VERSION ""

NS_ :

BS_:

BU_: XXX CAMERA FRONT_RADAR ADRV APRK

BO_ 731 MLM_02_200ms: 8 XXX
 SG_ MLM_SlvColor_X : 0|8@1+ (1,0) [0|255] "" XXX
 SG_ MLM_SlvColor_Y : 8|16@1+ (1,0) [0|65535] "" XXX
 SG_ MLM_SlvBrgtnsVal : 24|8@1+ (1,0) [0|255] "" XXX
 SG_ MLM_SlvFadeInTimetVal : 32|8@1+ (1,0) [0|255] "" XXX
 SG_ MLM_SlvFadeOutTimetVal : 40|8@1+ (1,0) [0|255] "" XXX
 SG_ MLM_SlvFadeInOutOnOff : 48|8@1+ (1,0) [0|255] "" XXX

BO_ 732 ADAS_PRK_CAM_01_600ms: 8 XXX
 SG_ ADAS_PRK_CAM_Crc1Val : 0|16@1+ (1,0) [0|65535] "" XXX
 SG_ ADAS_PRK_CAM_AlvCnt1Val : 16|8@1+ (1,0) [0|255] "" XXX
 SG_ SVM_CamExtID : 24|8@1+ (1,0) [0|255] "" XXX
 SG_ SVM_CamExtTrnX : 32|13@1+ (1,0) [0|8191] "" XXX
 SG_ SVM_CamExtTrnY : 45|19@1+ (1,0) [0|524287] "" XXX
 SG_ SVM_CamExtTrnZ : 64|10@1+ (1,0) [0|1023] "" XXX
 SG_ SVM_CamExtPitch : 74|11@1+ (1,0) [0|2047] "" XXX
 SG_ SVM_CamExtYaw : 85|11@1+ (1,0) [0|2047] "" XXX
 SG_ SVM_CamExtRoll : 96|8@1+ (1,0) [0|255] "" XXX

BO_ 733 CMS_LH_01_200ms: 8 XXX
 SG_ USM_TurnDstLnDispSta : 20|2@1+ (1,0) [0|3] "" XXX
 SG_ USM_TurnDstLnDispStaRH : 22|2@1+ (1,0) [0|3] "" XXX
 SG_ USM_RhstaLvlEnaSta : 24|2@1+ (1,0) [0|3] "" XXX
 SG_ USM_RhstaLvlEnaStaRH : 26|2@1+ (1,0) [0|3] "" XXX
 SG_ USM_CMSDayBrgtnsLvlLHSta : 28|4@1+ (1,0) [0|15] "" XXX
 SG_ USM_CMSNgtBrgtnsLvlLHSta : 32|4@1+ (1,0) [0|15] "" XXX
 SG_ IMS_CMSPlayBackSta_LH : 36|4@1+ (1,0) [0|15] "" XXX
 SG_ CMSFldReq : 40|8@1+ (1,0) [0|255] "" XXX
 SG_ CMS_LHVerPosVal : 48|8@1+ (1,0) [0|255] "" XXX
 SG_ CMS_LHHorPosVal : 56|8@1+ (1,0) [0|255] "" XXX

BO_ 734 CMS_LH_02_200ms: 8 XXX
 SG_ CMS_LHSta : 16|2@1+ (1,0) [0|3] "" XXX
 SG_ CMS_Opt : 18|6@1+ (1,0) [0|63] "" XXX

BO_ 735 HU_FPM_E: 8 XXX
 SG_ CF_AVN_FpLpRedNValueSet : 0|9@1+ (1,0) [0|511] "" XXX
 SG_ CF_AVN_FpLpGreenNValueSet : 9|9@1+ (1,0) [0|511] "" XXX
 SG_ CF_AVN_FpLpBlueNValueSet : 18|9@1+ (1,0) [0|511] "" XXX
 SG_ CF_AVN_FpLpCtrlNvalueSet : 27|5@1+ (1,0) [0|31] "" XXX

BO_ 736 VCU_03_100ms: 32 XXX
 SG_ VCU_Crc3Val : 0|16@1+ (1,0) [0|65535] "" XXX
 SG_ VCU_AlvCnt3Val : 16|8@1+ (1,0) [0|255] "" XXX
 SG_ VCU_CrzDrvAlertDisp : 24|2@1+ (1,0) [0|3] "" XXX
 SG_ VCU_SpdLimSetLampSta : 26|2@1+ (1,0) [0|3] "" XXX
 SG_ VCU_CrzOnLampSta : 32|2@1+ (1,0) [0|3] "" XXX
 SG_ VCU_CrzSetLampSta : 34|2@1+ (1,0) [0|3] "" XXX
 SG_ VCU_CrzOvrrideSta : 36|2@1+ (1,0) [0|3] "" XXX
 SG_ VCU_SpdLmtActSta : 38|1@1+ (1,0) [0|1] "" XXX
 SG_ VCU_CrzSetSpdVal : 40|8@1+ (1,0) [0|255] "" XXX
 SG_ VCU_SpdLmtSetSpdVal : 48|7@1+ (1,0) [0|127] "" XXX
 SG_ MAX_SPEED : 55|1@0+ (1,0) [0|1] "" XXX
 SG_ VCU_RegenLvl_EcoModeSta : 56|2@1+ (1,0) [0|3] "" XXX
 SG_ VCU_RegenLvl_NorModeSta : 58|2@1+ (1,0) [0|3] "" XXX
 SG_ VCU_RegenLvl_SptModeSta : 60|2@1+ (1,0) [0|3] "" XXX
 SG_ VCU_SccAvailSta : 62|2@1+ (1,0) [0|3] "" XXX
 SG_ VCU_SccMaxTqVal : 64|8@1+ (1,0) [0|255] "" XXX
 SG_ VCU_EcoModSpdLmt_ActSta : 72|5@1+ (1,0) [0|31] "" XXX
 SG_ VCU_SmartModSta : 77|3@1+ (1,0) [0|7] "" XXX
 SG_ VCU_EcoModSpdLmt_SetSpdVal : 80|8@1+ (1,0) [0|255] "" XXX
 SG_ VCU_SmartRegen_UsmSta : 88|2@1+ (1,0) [0|3] "" XXX
 SG_ VCU_SmartRegen_OnSta : 90|2@1+ (1,0) [0|3] "" XXX
 SG_ VCU_SmartRegen_RdrCstActSta : 92|2@1+ (1,0) [0|3] "" XXX
 SG_ VCU_SmartRegen_WarnMsgSta : 94|2@1+ (1,0) [0|3] "" XXX
 SG_ VCU_SmartModIdx : 96|5@1+ (1,0) [0|31] "" XXX
 SG_ VCU_VehHoldSta : 101|2@1+ (1,0) [0|3] "" XXX
 SG_ VCU_SmartRegen_OnAlarmSta : 103|2@1+ (1,0) [0|3] "" XXX
 SG_ VCU_RegenLvlVal : 105|6@1+ (1,0) [0|63] "" XXX
 SG_ VCU_SmartRegen_MapCstActSta : 111|3@1+ (1,0) [0|7] "" XXX
 SG_ VCU_SmartRegen_MapEventUsmSta : 114|2@1+ (1,0) [0|3] "" XXX
 SG_ VCU_SmartRegen_IntsectUsmSta : 116|2@1+ (1,0) [0|3] "" XXX
 SG_ VCU_SmartRegen_SpdHumpUsmSta : 118|2@1+ (1,0) [0|3] "" XXX
 SG_ VCU_SmartRegen_SpdLmtUsmSta : 120|2@1+ (1,0) [0|3] "" XXX
 SG_ VCU_SmartRegen_SensUsmSta : 122|6@1+ (1,0) [0|63] "" XXX
 SG_ VCU_SmartRegen_VehHoldUsmSta : 128|2@1+ (1,0) [0|3] "" XXX
 SG_ VCU_SmartRegen_IntsectCstActSta : 130|2@1+ (1,0) [0|3] "" XXX
 SG_ VCU_SmartRegen_SpdHumpCstActSta : 132|2@1+ (1,0) [0|3] "" XXX
 SG_ VCU_SmartRegen_SpdLmtCstActSta : 134|2@1+ (1,0) [0|3] "" XXX
 SG_ VCU_iPedalUsmSta : 136|2@1+ (1,0) [0|3] "" XXX
 SG_ VCU_SmartRegen_MapCstWarnMsgSta : 138|3@1+ (1,0) [0|7] "" XXX
 SG_ VCU_SmartRegen_RdrCstWarnMsgSta : 141|3@1+ (1,0) [0|7] "" XXX
 SG_ MAX_SPEED_COPY : 144|8@1+ (1,0) [0|255] "" XXX
 SG_ VCU_SpdLmtDrvAlertDisp : 173|2@1+ (1,0) [0|3] "" XXX
 SG_ VCU_iPedalActSta : 175|2@1+ (1,0) [0|3] "" XXX
 SG_ VCU_DrvModeApply : 177|8@1+ (1,0) [0|255] "" XXX
 SG_ VCU_iPedalIndiSta : 185|7@1+ (1,0) [0|127] "" XXX
 SG_ VCU_TowWeightUsmSta : 192|4@1+ (1,0) [0|15] "" XXX
 SG_ VCU_TowMaxWeightUsmSta : 196|4@1+ (1,0) [0|15] "" XXX
 SG_ VCU_TrailerModWarnMsgSta : 200|8@1+ (1,0) [0|255] "" XXX
 SG_ VCU_VgsSftMod : 208|3@1+ (1,0) [0|7] "" XXX
 SG_ VCU_VgsVirEngSpdRpmMaxVal : 211|5@1+ (1,0) [0|31] "" XXX
 SG_ VCU_VgsGearStepType : 216|4@1+ (1,0) [0|15] "" XXX
 SG_ VCU_VgsVirEngSpdRpmRedStartVal : 220|28@1+ (1,0) [0|268435455] "" XXX
 SG_ VCU_eEPBCtrlSta : 248|2@1+ (1,0) [0|3] "" XXX
 SG_ VCU_eEPBSta : 250|2@1+ (1,0) [0|3] "" XXX
 SG_ VCU_eEPBCommSta : 252|4@1+ (1,0) [0|15] "" XXX

BO_ 741 OBC_01_100ms: 8 XXX
 SG_ OBC_Crc1Val : 0|16@1+ (1,0) [0|65535] "" XXX
 SG_ OBC_AlvCnt1Val : 16|8@1+ (1,0) [0|255] "" XXX
 SG_ OBC_SysRdySta : 24|4@1+ (1,0) [0|15] "" XXX
 SG_ OBC_ContrabSta : 28|4@1+ (1,0) [0|15] "" XXX
 SG_ OBC_SysFltSta : 32|2@1+ (1,0) [0|3] "" XXX
 SG_ OBC_ChrgFnshSta : 34|2@1+ (1,0) [0|3] "" XXX
 SG_ OBC_AcDetSta : 36|2@1+ (1,0) [0|3] "" XXX
 SG_ OBC_HvIntlkReq : 38|2@1+ (1,0) [0|3] "" XXX
 SG_ OBC_VcrmReq : 40|2@1+ (1,0) [0|3] "" XXX
 SG_ OBC_SvrLmpReq : 42|6@1+ (1,0) [0|63] "" XXX
 SG_ OBC_OpModeSta : 48|3@1+ (1,0) [0|7] "" XXX
 SG_ OBC_DiagInfoGrp : 51|5@1+ (1,0) [0|31] "" XXX
 SG_ OBC_DcMaxCurrVal : 56|8@1+ (1,0) [0|255] "" XXX
 SG_ OBC_SeqSta : 64|8@1+ (1,0) [0|255] "" XXX
 SG_ OBC_PwrLmtSta : 72|4@1+ (1,0) [0|15] "" XXX
 SG_ OBC_InfoCodVal : 76|12@1+ (1,0) [0|4095] "" XXX
 SG_ OBC_EstDcOutPwrValForVcms : 88|8@1+ (1,0) [0|255] "" XXX
 SG_ OBC_AcVoltValForVcms : 96|8@1+ (1,0) [0|255] "" XXX

BO_ 746 MCU_08_200ms: 8 XXX
 SG_ MCU_Crc8Val : 0|16@1+ (1,0) [0|65535] "" XXX
 SG_ MCU_AlvCnt8Val : 16|8@1+ (1,0) [0|255] "" XXX
 SG_ VCRM_Mg2RsvrLssjsFigRdsVal : 24|10@1+ (1,0) [0|1023] "" XXX
 SG_ VCRM_Mg2MainStateSta : 34|6@1+ (1,0) [0|63] "" XXX
 SG_ VCRM_Mg2RsvrLssjsFigDevVal : 40|16@1+ (1,0) [0|65535] "" XXX
 SG_ VCRM_Mg2OpSta : 56|8@1+ (1,0) [0|255] "" XXX
 SG_ VCRM_Mg2CurRmsVal : 64|16@1+ (1,0) [0|65535] "" XXX
 SG_ MCU_Mg2MotPower_Wh : 80|16@1+ (1,0) [0|65535] "" XXX
 SG_ MCU_Mg2GenPower_Wh : 96|32@1+ (1,0) [0|4294967295] "" XXX
 SG_ VCRM_Mg2FltCodeVal : 128|8@1+ (1,0) [0|255] "" XXX

BO_ 758 SBCM_DRV_02_200ms: 8 XXX
 SG_ SBCM_DRV_Crc2Val : 0|8@1+ (1,0) [0|255] "" XXX
 SG_ SBCM_DRV_DiagSta : 8|4@1+ (1,0) [0|15] "" XXX
 SG_ SBCM_DRV_AlvCnt2Val : 12|4@1+ (1,0) [0|15] "" XXX
 SG_ SBCM_PsvDrLkReq : 16|6@1+ (1,0) [0|63] "" XXX
 SG_ USM_DrvGhostDoorSta : 22|6@1+ (1,0) [0|63] "" XXX
 SG_ DRV_CrashMRActAlarm : 28|8@1+ (1,0) [0|255] "" XXX
 SG_ IMS_OSMirPlayBackSta_LH : 36|4@1+ (1,0) [0|15] "" XXX
 SG_ ECMMRR_PLUS : 40|8@1+ (1,0) [0|255] "" XXX
 SG_ Mirror_LHVerPosVal : 48|8@1+ (1,0) [0|255] "" XXX
 SG_ Mirror_LHHorPosVal : 56|8@1+ (1,0) [0|255] "" XXX

BO_ 759 SBCM_RL_02_200ms: 8 XXX
 SG_ RL_CrashMRActAlarm : 10|2@1+ (1,0) [0|3] "" XXX
 SG_ PwrDRBuzzerOut_RL : 12|4@1+ (1,0) [0|15] "" XXX
 SG_ PwrDRClosingRLDrSta : 16|8@1+ (1,0) [0|255] "" XXX

BO_ 760 SBCM_RR_02_200ms: 8 XXX
 SG_ SMK_Crc1Val : 0|8@1+ (1,0) [0|255] "" XXX
 SG_ Auth_Event : 8|4@1+ (1,0) [0|15] "" XXX
 SG_ RR_CrashMRActAlarm : 10|2@1+ (1,0) [0|3] "" XXX
 SG_ SMK_AlvCnt1Val : 12|4@1+ (1,0) [0|15] "" XXX
 SG_ PwrDRClosingRRDrSta : 16|8@1+ (1,0) [0|255] "" XXX
 SG_ DoorLock_PsvDrUnLkReq : 19|3@1+ (1,0) [0|7] "" XXX
 SG_ DoorLock_DrvDrPsvAcsReq : 22|2@1+ (1,0) [0|3] "" XXX
 SG_ DoorLock_AsstDrPsvAcsReq : 24|2@1+ (1,0) [0|3] "" XXX
 SG_ DoorLock_TrnkTlgtPsvAcsReq : 26|2@1+ (1,0) [0|3] "" XXX
 SG_ DoorLock_RrLftDrPsvAcsReq : 28|2@1+ (1,0) [0|3] "" XXX
 SG_ DoorLock_RrRtDrPsvAcsReq : 30|8@1+ (1,0) [0|255] "" XXX
 SG_ RSPA_DigitalKeyAuth : 38|4@1+ (1,0) [0|15] "" XXX
 SG_ SCM_SWVerMajor1 : 40|8@1+ (1,0) [0|255] "" XXX
 SG_ Auth_Method : 42|6@1+ (1,0) [0|63] "" XXX
 SG_ SCM_SWVerMinor1 : 48|8@1+ (1,0) [0|255] "" XXX
 SG_ SCM_SWVerMinor2 : 56|8@1+ (1,0) [0|255] "" XXX

BO_ 761 CMS_RH_01_200ms_CMS: 8 XXX
 SG_ Mirror_RHVerPosVal : 48|8@1+ (1,0) [0|255] "" XXX
 SG_ Mirror_RHHorPosVal : 56|8@1+ (1,0) [0|255] "" XXX

BO_ 762 BMS_02_100ms: 8 XXX
 SG_ BMS_Crc2Val : 0|16@1+ (1,0) [0|65535] "" XXX
 SG_ BMS_AlvCnt2Val : 16|8@1+ (1,0) [0|255] "" XXX
 SG_ xEV_SrvLmpReq : 24|2@1+ (1,0) [0|3] "" XXX
 SG_ xEV_MainRlyOnSta : 26|2@1+ (1,0) [0|3] "" XXX
 SG_ xEV_SysFltSta : 28|4@1+ (1,0) [0|15] "" XXX
 SG_ xEV_BattRmnEnrgVal : 32|8@1+ (1,0) [0|255] "" XXX
 SG_ xEV_InltTempVal : 40|8@1+ (1,0) [0|255] "" XXX
 SG_ xEV_MinBattCelVoltVal : 48|8@1+ (1,0) [0|255] "" XXX
 SG_ xEV_MaxBattCelVoltVal : 56|8@1+ (1,0) [0|255] "" XXX
 SG_ xEV_BattCurrVal : 64|16@1+ (1,0) [0|65535] "" XXX
 SG_ xEV_MinBattTempVal : 80|8@1+ (1,0) [0|255] "" XXX
 SG_ xEV_MaxBattTempVal : 88|16@1+ (1,0) [0|65535] "" XXX
 SG_ xEV_DiagGrpVal : 104|8@1+ (1,0) [0|255] "" XXX
 SG_ xEV_DiagMonVal : 112|8@1+ (1,0) [0|255] "" XXX
 SG_ xEV_SocDis : 120|34@1+ (1,0) [0|17179869183] "" XXX
 SG_ xEV_ClimateOffReq : 154|2@1+ (1,0) [0|3] "" XXX
 SG_ xEV_MainRlyOnRetrySta : 156|2@1+ (1,0) [0|3] "" XXX
 SG_ xEV_Bms_BlackBox_Data_req : 158|12@1+ (1,0) [0|4095] "" XXX
 SG_ xEV_BmsRomType : 170|6@1+ (1,0) [0|63] "" XXX
 SG_ xEV_PRATempSnsVal_ : 176|16@1+ (1,0) [0|65535] "" XXX
 SG_ xEV_BattRCHTimeEst : 192|16@1+ (1,0) [0|65535] "" XXX
 SG_ EV_DischrgCurrLimForV2X : 208|16@1+ (1,0) [0|65535] "" XXX
 SG_ xEV_Bms_IsolDetDeactFuncSta : 224|2@1+ (1,0) [0|3] "" XXX
 SG_ xEV_Bms_CellBalDeactFuncSta : 226|6@1+ (1,0) [0|63] "" XXX
 SG_ EV_V2XDischrgLimSocVal_SYNC : 232|8@1+ (1,0) [0|255] "" XXX

BO_ 763 SBCM_DRV_03_200ms: 8 XXX
 SG_ SBCM_DRV_Crc3Val : 0|12@1+ (1,0) [0|4095] "" XXX
 SG_ SBCM_DRV_AlvCnt3Val : 12|22@1+ (1,0) [0|4194303] "" XXX
 SG_ PwrDRBuzzerOut_DRV : 34|12@1+ (1,0) [0|4095] "" XXX
 SG_ SBCM_Longkey_DRVDrAtClsSwSta : 46|2@1+ (1,0) [0|3] "" XXX
 SG_ PwrDRClosingDRVDrSta : 48|8@1+ (1,0) [0|255] "" XXX

BO_ 769 CCU_FOD_01_200ms: 8 XXX
 SG_ CCU_FOD_Crc1Val : 0|16@1+ (1,0) [0|65535] "" XXX
 SG_ CCU_FOD_AlvCnt1Val : 16|8@1+ (1,0) [0|255] "" XXX
 SG_ CCU_FOD_VIN_Status : 24|2@1+ (1,0) [0|3] "" XXX
 SG_ CCU_FOD_VIN_Index : 26|6@1+ (1,0) [0|63] "" XXX
 SG_ CCU_FOD_VIN_32 : 32|8@1+ (1,0) [0|255] "" XXX

BO_ 773 MCU_09_1000ms: 8 XXX
 SG_ MCU_Crc9Val : 0|16@1+ (1,0) [0|65535] "" XXX
 SG_ MCU_AlvCnt9Val : 16|8@1+ (1,0) [0|255] "" XXX
 SG_ VCRM_Mg2EstMtrTqVal : 24|8@1+ (1,0) [0|255] "" XXX
 SG_ VCRM_Mg2MtrDeratingFctrVal : 32|8@1+ (1,0) [0|255] "" XXX
 SG_ VCRM_Mg2InvtTempVal : 40|8@1+ (1,0) [0|255] "" XXX
 SG_ VCRM_Mg2MtrTempVal : 48|24@1+ (1,0) [0|16777215] "" XXX
 SG_ VCRM_Mg2IgbtJnctnTempVal : 72|16@1+ (1,0) [0|65535] "" XXX
 SG_ VCRM_Mg2InvtInVoltVal : 88|8@1+ (1,0) [0|255] "" XXX
 SG_ VCRM_Mg2EwpSpdReq : 96|8@1+ (1,0) [0|255] "" XXX
 SG_ VCRM_Mg2HtsnkTempVal : 104|8@1+ (1,0) [0|255] "" XXX
 SG_ VCRM_Mg2ActlMtrRotatSpdRpmVal : 112|16@1+ (1,0) [0|65535] "" XXX
 SG_ VCRM_Mg2EwpActSpdRpmVal : 128|56@1+ (1,0) [0|7.20575940379279e+16] "" XXX
 SG_ VCRM_Mg2LampReq : 184|2@1+ (1,0) [0|3] "" XXX
 SG_ VCRM_Mg2McuReq : 186|6@1+ (1,0) [0|63] "" XXX

BO_ 778 VCMS_02_100ms: 8 XXX
 SG_ VCMS_CyclicRedundancyCheck2Value : 0|16@1+ (1,0) [0|65535] "" XXX
 SG_ VCMS_AliveCounter2Value : 16|8@1+ (1,0) [0|255] "" XXX
 SG_ VCMS_CONTRAB : 24|2@1+ (1,0) [0|3] "" XXX
 SG_ VCMS_PDStatus : 26|2@1+ (1,0) [0|3] "" XXX
 SG_ VCMS_ChgFinished : 28|2@1+ (1,0) [0|3] "" XXX
 SG_ VCMS_WRN : 30|2@1+ (1,0) [0|3] "" XXX
 SG_ VCMS_Flt : 32|2@1+ (1,0) [0|3] "" XXX
 SG_ VCMS_Rdy : 34|2@1+ (1,0) [0|3] "" XXX
 SG_ VCMS_IG3DrvStat : 36|2@1+ (1,0) [0|3] "" XXX
 SG_ VCMS_PlugConnect : 38|2@1+ (1,0) [0|3] "" XXX
 SG_ VCMS_S2SWOnStat : 40|2@1+ (1,0) [0|3] "" XXX
 SG_ VCMS_MILReq : 42|2@1+ (1,0) [0|3] "" XXX
 SG_ VCMS_VCRM_Req : 44|2@1+ (1,0) [0|3] "" XXX
 SG_ VCMS_SERVICE_LAMP_Req : 46|2@1+ (1,0) [0|3] "" XXX
 SG_ VCMS_V2LActivation : 48|2@1+ (1,0) [0|3] "" XXX
 SG_ VCMS_DCChargingStat : 50|2@1+ (1,0) [0|3] "" XXX
 SG_ VCMS_ACChargingStat : 52|4@1+ (1,0) [0|15] "" XXX
 SG_ VCMS_ChargeInit : 56|2@1+ (1,0) [0|3] "" XXX
 SG_ VCMS_ChargingCycle : 58|2@1+ (1,0) [0|3] "" XXX
 SG_ VCMS_EvseRdyStat : 60|2@1+ (1,0) [0|3] "" XXX
 SG_ VCMS_ChgStopAlarm : 62|2@1+ (1,0) [0|3] "" XXX
 SG_ VCMS_PlcCpFlt : 64|2@1+ (1,0) [0|3] "" XXX
 SG_ VCMS_McuForcedDischReq : 66|2@1+ (1,0) [0|3] "" XXX
 SG_ VCMS_GbtPDStatus : 68|2@1+ (1,0) [0|3] "" XXX
 SG_ VCMS_V2lPlugConnect : 70|1@1+ (1,0) [0|1] "" XXX
 SG_ VCMS_CPDutyFloat : 71|10@1+ (1,0) [0|1023] "" XXX
 SG_ VCMS_CPVolt : 81|7@1+ (1,0) [0|127] "" XXX
 SG_ VCMS_FltCode_Confirm : 88|5@1+ (1,0) [0|31] "" XXX
 SG_ VCMS_FltType_Confirm : 93|3@1+ (1,0) [0|7] "" XXX
 SG_ VCMS_PdVolt : 96|8@1+ (1,0) [0|255] "" XXX
 SG_ VCMS_CluDisMode : 104|8@1+ (1,0) [0|255] "" XXX
 SG_ VCMS_EvseMaxVolt : 112|16@1+ (1,0) [0|65535] "" XXX
 SG_ VCMS_EvseMaxCurr : 128|16@1+ (1,0) [0|65535] "" XXX
 SG_ VCMS_EvseOutCurr : 144|16@1+ (1,0) [0|65535] "" XXX
 SG_ VCMS_ChgInletTmpMax : 160|8@1+ (1,0) [0|255] "" XXX
 SG_ VCMS_ChgEstPwr : 168|16@1+ (1,0) [0|65535] "" XXX
 SG_ OBC_AcPwrSysTyp : 173|3@1+ (1,0) [0|7] "" XXX
 SG_ VCMS_ChgAlarm_Stat : 184|4@1+ (1,0) [0|15] "" XXX
 SG_ VCMS_ChgAlarm_Subcode : 188|4@1+ (1,0) [0|15] "" XXX
 SG_ VCMS_ChgMaxCurr : 192|16@1+ (1,0) [0|65535] "" XXX
 SG_ VCMS_AcPwrSysTyp : 208|3@1+ (1,0) [0|7] "" XXX
 SG_ VCMS_Chg_SOC_Lv : 211|3@1+ (1,0) [0|7] "" XXX
 SG_ VCMS_GbtPlugConnect : 214|2@1+ (1,0) [0|3] "" XXX
 SG_ VCMS_ChrgInletTyp : 216|8@1+ (1,0) [0|255] "" XXX
 SG_ VCMS_ChgInCurrModSta : 224|2@1+ (1,0) [0|3] "" XXX
 SG_ VCMS_V2GMode : 226|3@1+ (1,0) [0|7] "" XXX
 SG_ VCMS_V2LMode : 229|20@1+ (1,0) [0|1048575] "" XXX
 SG_ VCMS_Asw_Num : 249|7@1+ (1,0) [0|127] "" XXX

BO_ 799 SBCM_DRV_01_200ms: 8 XXX
 SG_ SBCM_DRV_Crc1Val : 0|8@1+ (1,0) [0|255] "" XXX
 SG_ DRVDoorPushAlarm : 8|2@1+ (1,0) [0|3] "" XXX
 SG_ DRV_CrashUnlockCmd : 10|1@1+ (1,0) [0|1] "" XXX
 SG_ C_ApprOpenStatus : 11|1@1+ (1,0) [0|1] "" XXX
 SG_ SBCM_DRV_AlvCnt1Val : 12|8@1+ (1,0) [0|255] "" XXX
 SG_ Warn_DrvDrSwSta_SBCM : 20|2@1+ (1,0) [0|3] "" XXX
 SG_ DoorLock_DrvDrUnLkSta_SBCM : 22|2@1+ (1,0) [0|3] "" XXX
 SG_ DRV_SEAWarn_LH : 24|2@1+ (1,0) [0|3] "" XXX
 SG_ DRV_SEAWarn_RH : 26|2@1+ (1,0) [0|3] "" XXX
 SG_ DRV_SEWWarn_LH : 28|2@1+ (1,0) [0|3] "" XXX
 SG_ DRV_SEWWarn_RH : 30|2@1+ (1,0) [0|3] "" XXX
 SG_ DRV_MRActivationAlarm : 32|2@1+ (1,0) [0|3] "" XXX
 SG_ DRV_ReleaseWarn : 34|2@1+ (1,0) [0|3] "" XXX
 SG_ Latch_TypeOption_DRV : 36|2@1+ (1,0) [0|3] "" XXX
 SG_ DRV_SWFailAlarm : 38|6@1+ (1,0) [0|63] "" XXX
 SG_ USM_PwrDRCloseByRKELockSta : 44|2@1+ (1,0) [0|3] "" XXX
 SG_ USM_PwrDRCloseByRKELockOpt : 46|2@1+ (1,0) [0|3] "" XXX
 SG_ USM_PwrDRCloseByBrakeSta : 48|2@1+ (1,0) [0|3] "" XXX
 SG_ USM_PwrDRCloseByBrakeOpt : 50|2@1+ (1,0) [0|3] "" XXX
 SG_ USM_PwrDRBuzzerSta : 52|2@1+ (1,0) [0|3] "" XXX
 SG_ USM_PwrDRBuzzerOpt : 54|2@1+ (1,0) [0|3] "" XXX
 SG_ PDS_TypeOption_DRV : 56|2@1+ (1,0) [0|3] "" XXX
 SG_ C_DrvDoorApproachOpen : 58|2@1+ (1,0) [0|3] "" XXX
 SG_ C_DrvDoorApproachClose : 60|2@1+ (1,0) [0|3] "" XXX
 SG_ DoorLock_PDSLkSwSta_DRV : 62|2@1+ (1,0) [0|3] "" XXX

BO_ 805 BMS_06_100ms: 8 XXX
 SG_ BMS_Crc6Val : 0|16@1+ (1,0) [0|65535] "" XXX
 SG_ BMS_AlvCnt6Val : 16|8@1+ (1,0) [0|255] "" XXX
 SG_ CHRG_StndChrgConnSta_120V : 24|2@1+ (1,0) [0|3] "" XXX
 SG_ CHRG_StndChrgSta : 26|2@1+ (1,0) [0|3] "" XXX
 SG_ CHRG_ChrgCycStrtSta : 28|2@1+ (1,0) [0|3] "" XXX
 SG_ CHRG_FulChrgSta : 30|2@1+ (1,0) [0|3] "" XXX
 SG_ CHRG_ChrgSta : 32|2@1+ (1,0) [0|3] "" XXX
 SG_ CHRG_SpplmntChrgSta : 34|2@1+ (1,0) [0|3] "" XXX
 SG_ CHRG_LdcInhbtReq : 36|2@1+ (1,0) [0|3] "" XXX
 SG_ CHRG_NorChgFnshSta : 38|2@1+ (1,0) [0|3] "" XXX
 SG_ CHRG_ChrgFnshSta : 40|2@1+ (1,0) [0|3] "" XXX
 SG_ CHRG_Ig3RlyOffReq : 42|2@1+ (1,0) [0|3] "" XXX
 SG_ CHRG_PShftChgSta : 44|2@1+ (1,0) [0|3] "" XXX
 SG_ CHRG_PilotFlSta : 46|2@1+ (1,0) [0|3] "" XXX
 SG_ CHRG_ObcCmdCurrVal : 48|16@1+ (1,0) [0|65535] "" XXX
 SG_ CHRG_StndChrgRmnTimeVal : 64|16@1+ (1,0) [0|65535] "" XXX
 SG_ CHRG_ChrgRmnTimeVal : 80|16@1+ (1,0) [0|65535] "" XXX
 SG_ CHRG_ObcRlyOnSta : 96|2@1+ (1,0) [0|3] "" XXX
 SG_ CHRG_NrmlOpSta : 98|2@1+ (1,0) [0|3] "" XXX
 SG_ CHRG_ChgLamp_1EA : 100|4@1+ (1,0) [0|15] "" XXX
 SG_ CHRG_ObcCmdVoltVal : 104|16@1+ (1,0) [0|65535] "" XXX
 SG_ CHRG_ObcMainVoltVal : 120|8@1+ (1,0) [0|255] "" XXX
 SG_ CHRG_StndChrgRmnTime120Val : 128|16@1+ (1,0) [0|65535] "" XXX
 SG_ CHRG_StndChrgRmnTime240Val : 144|16@1+ (1,0) [0|65535] "" XXX
 SG_ CHRG_ObcOutCurrVal : 160|8@1+ (1,0) [0|255] "" XXX
 SG_ CHRG_DomStndChrgRmnTimeVal : 168|16@1+ (1,0) [0|65535] "" XXX
 SG_ CHRG_ChrgFltSubCodVal : 184|8@1+ (1,0) [0|255] "" XXX
 SG_ CHRG_ScChgTrgtSocVal : 192|8@1+ (1,0) [0|255] "" XXX
 SG_ CHRG_EuroStndChrgRmnTimeVal : 200|16@1+ (1,0) [0|65535] "" XXX
 SG_ CHRG_RealStndChrgRmnTimeVal : 216|16@1+ (1,0) [0|65535] "" XXX
 SG_ PHEV_EstChrgRmnTimeVal : 232|16@1+ (1,0) [0|65535] "" XXX
 SG_ CHRG_ChrgLmp_3EA : 248|8@1+ (1,0) [0|255] "" XXX

BO_ 816 BMS_05_100ms: 8 XXX
 SG_ BMS_Crc5Val : 0|16@1+ (1,0) [0|65535] "" XXX
 SG_ BMS_AlvCnt5Val : 16|8@1+ (1,0) [0|255] "" XXX
 SG_ EV_SysErrSta : 24|2@1+ (1,0) [0|3] "" XXX
 SG_ EV_BattHtOpSta : 26|2@1+ (1,0) [0|3] "" XXX
 SG_ EV_EnrgTrnsfrTyp : 28|4@1+ (1,0) [0|15] "" XXX
 SG_ EV_FulSocVal : 32|8@1+ (1,0) [0|255] "" XXX
 SG_ EV_BulkSocVal : 40|8@1+ (1,0) [0|255] "" XXX
 SG_ EV_EnrgCapVal : 48|16@1+ (1,0) [0|65535] "" XXX
 SG_ EV_FulSocRmnTimeVal : 64|16@1+ (1,0) [0|65535] "" XXX
 SG_ EV_BulkSocRmnTimeVal : 80|16@1+ (1,0) [0|65535] "" XXX
 SG_ EV_MaxPwrVal : 96|16@1+ (1,0) [0|65535] "" XXX
 SG_ EV_EnrgReqVal : 112|16@1+ (1,0) [0|65535] "" XXX
 SG_ EV_WeldDetSta : 128|2@1+ (1,0) [0|3] "" XXX
 SG_ EV_Rdy2ChrgSta : 130|2@1+ (1,0) [0|3] "" XXX
 SG_ EV_CabinConSta : 132|2@1+ (1,0) [0|3] "" XXX
 SG_ EV_TempChrgFlSta : 134|2@1+ (1,0) [0|3] "" XXX
 SG_ EV_GearPosChrgFlSta : 136|2@1+ (1,0) [0|3] "" XXX
 SG_ EV_LkFltChrgFlSta : 138|2@1+ (1,0) [0|3] "" XXX
 SG_ EV_MalFuncChrgFlSta : 140|2@1+ (1,0) [0|3] "" XXX
 SG_ EV_CurrDiffChrgFlSta : 142|2@1+ (1,0) [0|3] "" XXX
 SG_ EV_VoltRngChrgFlSta : 144|2@1+ (1,0) [0|3] "" XXX
 SG_ EV_IncompChrgFlSta : 146|2@1+ (1,0) [0|3] "" XXX
 SG_ EV_NoDataChrgFlSta : 148|4@1+ (1,0) [0|15] "" XXX
 SG_ EV_MaxCurrVal : 152|16@1+ (1,0) [0|65535] "" XXX
 SG_ EV_MaxVoltVal : 168|16@1+ (1,0) [0|65535] "" XXX
 SG_ CHRG_ScChgTargetSOCSync : 184|8@1+ (1,0) [0|255] "" XXX
 SG_ CHRG_QcChgTargetSOCSync : 192|8@1+ (1,0) [0|255] "" XXX
 SG_ EV_LowOutTempStatus : 200|2@1+ (1,0) [0|3] "" XXX
 SG_ CHRG_TargetSocFullChgSta : 202|2@1+ (1,0) [0|3] "" XXX
 SG_ CHRG_QuickChgStartSta : 204|4@1+ (1,0) [0|15] "" XXX
 SG_ CHRG_BattPackVoltVal : 208|16@1+ (1,0) [0|65535] "" XXX
 SG_ CHRG_ScChgEnergy_TargetSOCVal : 224|16@1+ (1,0) [0|65535] "" XXX
 SG_ CHRG_QcChgEnergy_TargetSOCVal : 240|8@1+ (1,0) [0|255] "" XXX

BO_ 821 BMS_07_100ms: 8 XXX
 SG_ BMS_Crc7Val : 0|16@1+ (1,0) [0|65535] "" XXX
 SG_ BMS_AlvCnt7Val : 16|8@1+ (1,0) [0|255] "" XXX
 SG_ VCRM_StndChrgConnSta : 24|2@1+ (1,0) [0|3] "" XXX
 SG_ VCRM_StndChrgSta : 26|2@1+ (1,0) [0|3] "" XXX
 SG_ VCRM_MilReq : 28|2@1+ (1,0) [0|3] "" XXX
 SG_ VCRM_SrvLmpReq : 30|2@1+ (1,0) [0|3] "" XXX
 SG_ VCRM_MainRlyOnSta : 32|2@1+ (1,0) [0|3] "" XXX
 SG_ VCRM_SysFltSta : 34|2@1+ (1,0) [0|3] "" XXX
 SG_ VCRM_ChrgSta : 36|2@1+ (1,0) [0|3] "" XXX
 SG_ VCRM_ChrgFnshSta : 38|2@1+ (1,0) [0|3] "" XXX
 SG_ VCRM_SocDisplayVal : 40|8@1+ (1,0) [0|255] "" XXX
 SG_ VCRM_InltTempVal : 48|8@1+ (1,0) [0|255] "" XXX
 SG_ VCRM_MinBattCelVoltSta : 56|8@1+ (1,0) [0|255] "" XXX
 SG_ VCRM_MaxBattCelVoltSta : 64|8@1+ (1,0) [0|255] "" XXX
 SG_ VCRM_BattCurrVal : 72|16@1+ (1,0) [0|65535] "" XXX
 SG_ VCRM_MinBattTempVal : 88|8@1+ (1,0) [0|255] "" XXX
 SG_ VCRM_MaxBattTempVal : 96|8@1+ (1,0) [0|255] "" XXX
 SG_ VCRM_ServceMliLampReq : 104|2@1+ (1,0) [0|3] "" XXX
 SG_ VCRM_SubFanSpdStpSta : 106|6@1+ (1,0) [0|63] "" XXX
 SG_ VCRM_DiagGrpVal : 112|8@1+ (1,0) [0|255] "" XXX
 SG_ VCRM_IsolResistVal : 120|4@1+ (1,0) [0|15] "" XXX
 SG_ VCRM_ChrgLmp_1EA : 124|4@1+ (1,0) [0|15] "" XXX
 SG_ VCRM_ObcCmdCurrVal : 128|8@1+ (1,0) [0|255] "" XXX
 SG_ VCRM_StndChrgRmnTimeVal : 136|16@1+ (1,0) [0|65535] "" XXX
 SG_ VCRM_SwVerVal : 152|16@1+ (1,0) [0|65535] "" XXX
 SG_ VCRM_BattPckVoltVal : 168|16@1+ (1,0) [0|65535] "" XXX
 SG_ VCRM_SubInltTempVal : 184|8@1+ (1,0) [0|255] "" XXX
 SG_ VCRM_BattChrgLimVal : 192|16@1+ (1,0) [0|65535] "" XXX
 SG_ VCRM_BattDischrgLimVal : 208|16@1+ (1,0) [0|65535] "" XXX
 SG_ VCRM_ChrgLmp_3EA : 224|8@1+ (1,0) [0|255] "" XXX
 SG_ VCRM_SocVal_ : 232|8@1+ (1,0) [0|255] "" XXX
 SG_ VCRM_BatMonitorFaultcode : 240|8@1+ (1,0) [0|255] "" XXX

BO_ 827 TP_HU_IAU: 8 XXX
 SG_ TP_HU_IAU_Byte0 : 0|8@1+ (1,0) [0|255] "" XXX
 SG_ TP_HU_IAU_Byte1 : 8|8@1+ (1,0) [0|255] "" XXX
 SG_ TP_HU_IAU_Byte2 : 16|8@1+ (1,0) [0|255] "" XXX
 SG_ TP_HU_IAU_Byte3 : 24|8@1+ (1,0) [0|255] "" XXX
 SG_ TP_HU_IAU_Byte4 : 32|8@1+ (1,0) [0|255] "" XXX
 SG_ TP_HU_IAU_Byte5 : 40|8@1+ (1,0) [0|255] "" XXX
 SG_ TP_HU_IAU_Byte6 : 48|8@1+ (1,0) [0|255] "" XXX
 SG_ TP_HU_IAU_Byte7 : 56|8@1+ (1,0) [0|255] "" XXX

BO_ 828 TP_IAU_HU: 8 XXX
 SG_ TP_IAU_HU_Byte0 : 0|8@1+ (1,0) [0|255] "" XXX
 SG_ TP_IAU_HU_Byte1 : 8|8@1+ (1,0) [0|255] "" XXX
 SG_ TP_IAU_HU_Byte2 : 16|8@1+ (1,0) [0|255] "" XXX
 SG_ TP_IAU_HU_Byte3 : 24|8@1+ (1,0) [0|255] "" XXX
 SG_ TP_IAU_HU_Byte4 : 32|8@1+ (1,0) [0|255] "" XXX
 SG_ TP_IAU_HU_Byte5 : 40|8@1+ (1,0) [0|255] "" XXX
 SG_ TP_IAU_HU_Byte6 : 48|8@1+ (1,0) [0|255] "" XXX
 SG_ TP_IAU_HU_Byte7 : 56|8@1+ (1,0) [0|255] "" XXX

BO_ 836 WCCU_03_200ms: 8 XXX
 SG_ WCCU_GA_SSID_5 : 64|32@1+ (1,0) [0|4294967295] "" XXX
 SG_ WCCU_GA_SSID_6 : 96|32@1+ (1,0) [0|4294967295] "" XXX
 SG_ WCCU_GA_SSID_7 : 128|32@1+ (1,0) [0|4294967295] "" XXX
 SG_ WCCU_GA_SSID_8 : 160|32@1+ (1,0) [0|4294967295] "" XXX
 SG_ WCCU_GA_SSID_9 : 192|32@1+ (1,0) [0|4294967295] "" XXX
 SG_ WCCU_GA_SSID_10 : 224|8@1+ (1,0) [0|255] "" XXX

BO_ 837 ADAS_DRV_01_200ms: 8 XXX
 SG_ ADAS_DRV_Crc1Val : 0|16@1+ (1,0) [0|65535] "" XXX
 SG_ ADAS_DRV_AlvCnt1Val : 16|8@1+ (1,0) [0|255] "" XXX
 SG_ ADAS_DRV_FCAEquipSta : 24|2@1+ (1,0) [0|3] "" XXX
 SG_ ADAS_DRV_SCCEquipSta : 26|2@1+ (1,0) [0|3] "" XXX
 SG_ ADAS_DRV_MDPSCtrlSta : 28|4@1+ (1,0) [0|15] "" XXX
 SG_ ADAS_DRV_CodingSta : 32|2@1+ (1,0) [0|3] "" XXX
 SG_ ADAS_DRV_ACANMonSta : 34|6@1+ (1,0) [0|63] "" XXX

BO_ 842 DATC_16_1000ms: 8 XXX
 SG_ DATC_Crc16Val : 0|16@1+ (1,0) [0|65535] "" XXX
 SG_ DATC_AlvCnt16Val : 16|8@1+ (1,0) [0|255] "" XXX
 SG_ DATC_SwVer1 : 24|7@1+ (1,0) [0|127] "" XXX
 SG_ DATC_SwVer2 : 31|7@1+ (1,0) [0|127] "" XXX
 SG_ DATC_SwVer3 : 38|10@1+ (1,0) [0|1023] "" XXX
 SG_ DATC_Typ2 : 48|8@1+ (1,0) [0|255] "" XXX

BO_ 853 CCM_03_200ms: 8 XXX
 SG_ CCM_Crc3Val : 0|16@1+ (1,0) [0|65535] "" XXX
 SG_ CCM_AlvCnt3Val : 16|8@1+ (1,0) [0|255] "" XXX
 SG_ CCM_Evse_ID1 : 24|40@1+ (1,0) [0|1099511627775] "" XXX
 SG_ CCM_Evse_ID2 : 64|40@1+ (1,0) [0|1099511627775] "" XXX
 SG_ CCM_Cert_PCID1 : 104|24@1+ (1,0) [0|16777215] "" XXX
 SG_ CCM_Cert_PCID2 : 128|64@1+ (1,0) [0|1.84467440737096e+19] "" XXX
 SG_ CCM_Cert_PCID3 : 192|8@1+ (1,0) [0|255] "" XXX

BO_ 858 SBCM_AST_02_200ms: 8 XXX
 SG_ SBCM_AST_Crc3Val : 0|8@1+ (1,0) [0|255] "" XXX
 SG_ SBCM_AST_DiagSta : 8|4@1+ (1,0) [0|15] "" XXX
 SG_ AST_CrashUnlockCmd : 10|2@1+ (1,0) [0|3] "" XXX
 SG_ SBCM_AST_AlvCnt3Val : 12|20@1+ (1,0) [0|1048575] "" XXX
 SG_ DoorLock_CtrlDrLkSwSta_SBCM : 16|2@1+ (1,0) [0|3] "" XXX
 SG_ DoorLock_CtrlDrUnLkSwSta_SBCM : 18|2@1+ (1,0) [0|3] "" XXX
 SG_ Warn_AsstDrSwSta_SBCM : 20|2@1+ (1,0) [0|3] "" XXX
 SG_ DoorLock_AsstDrUnLkSta_SBCM : 22|2@1+ (1,0) [0|3] "" XXX
 SG_ AST_SEAWarn_RH : 24|2@1+ (1,0) [0|3] "" XXX
 SG_ AST_SEAWarn_LH : 26|2@1+ (1,0) [0|3] "" XXX
 SG_ AST_SEWWarn_LH : 28|2@1+ (1,0) [0|3] "" XXX
 SG_ AST_SEWWarn_RH : 30|2@1+ (1,0) [0|3] "" XXX
 SG_ AST_MRActivationAlarm : 32|2@1+ (1,0) [0|3] "" XXX
 SG_ PwrDRBuzzerOut_AST : 34|2@1+ (1,0) [0|3] "" XXX
 SG_ USM_AstGhostDoorSta : 36|2@1+ (1,0) [0|3] "" XXX
 SG_ AST_SWFailAlarm : 38|2@1+ (1,0) [0|3] "" XXX
 SG_ PwrDRClosingASTDrSta : 40|6@1+ (1,0) [0|63] "" XXX
 SG_ PDS_TypeOption_AST : 42|6@1+ (1,0) [0|63] "" XXX
 SG_ SBCM_Longkey_ASTDrAtClsSwSta : 46|2@1+ (1,0) [0|3] "" XXX

BO_ 862 SBCM_RL_01_200ms: 8 XXX
 SG_ SBCM_RL_Crc1Val : 0|8@1+ (1,0) [0|255] "" XXX
 SG_ RLDoorPushAlarm : 8|2@1+ (1,0) [0|3] "" XXX
 SG_ RL_CrashUnlockCmd : 10|2@1+ (1,0) [0|3] "" XXX
 SG_ SBCM_RL_AlvCnt1Val : 12|4@1+ (1,0) [0|15] "" XXX
 SG_ Warn_RrLftDrSwSta_SBCM : 16|2@1+ (1,0) [0|3] "" XXX
 SG_ DoorLock_RrLftDrUnLkSta_SBCM : 18|2@1+ (1,0) [0|3] "" XXX
 SG_ RL_SEAActivated : 20|2@1+ (1,0) [0|3] "" XXX
 SG_ RL_SEAWarn : 22|2@1+ (1,0) [0|3] "" XXX
 SG_ RL_SEWWarn : 24|2@1+ (1,0) [0|3] "" XXX
 SG_ RL_ReleaseWarn : 26|2@1+ (1,0) [0|3] "" XXX
 SG_ RL_SWFailAlarm : 28|2@1+ (1,0) [0|3] "" XXX
 SG_ RL_ChildLock_ActnFlSta : 30|2@1+ (1,0) [0|3] "" XXX
 SG_ RL_MRActivationAlarm : 32|2@1+ (1,0) [0|3] "" XXX
 SG_ RL_ChildLock_Status : 34|2@1+ (1,0) [0|3] "" XXX
 SG_ USM_RLGhostDoorSta : 36|4@1+ (1,0) [0|15] "" XXX
 SG_ DoorLock_PDSLkSwSta_RL : 40|2@1+ (1,0) [0|3] "" XXX
 SG_ PDS_TypeOption_RL : 42|6@1+ (1,0) [0|63] "" XXX

BO_ 866 CAM_0x362: 32 CAMERA
 SG_ CHECKSUM : 0|16@1+ (1,0) [0|65535] "" XXX
 SG_ COUNTER : 16|8@1+ (1,0) [0|255] "" XXX
 SG_ BYTE3 : 24|8@1+ (1,0) [0|255] "" XXX
 SG_ BYTE4 : 32|8@1+ (1,0) [0|255] "" XXX
 SG_ BYTE5 : 40|8@1+ (1,0) [0|255] "" XXX
 SG_ BYTE6 : 48|8@1+ (1,0) [0|255] "" XXX
 SG_ LEFT_LANE_LINE : 56|2@1+ (1,0) [0|3] "" XXX
 SG_ SET_ME_0 : 58|2@1+ (1,0) [0|3] "" XXX
 SG_ RIGHT_LANE_LINE : 60|2@1+ (1,0) [0|3] "" XXX
 SG_ SET_ME_0_2 : 62|2@1+ (1,0) [0|3] "" XXX
 SG_ BYTE8 : 64|8@1+ (1,0) [0|255] "" XXX
 SG_ BYTE9 : 72|8@1+ (1,0) [0|255] "" XXX
 SG_ BYTE10 : 80|8@1+ (1,0) [0|255] "" XXX
 SG_ BYTE11 : 88|8@1+ (1,0) [0|255] "" XXX
 SG_ BYTE12 : 96|8@1+ (1,0) [0|255] "" XXX
 SG_ BYTE13 : 104|8@1+ (1,0) [0|255] "" XXX
 SG_ BYTE14 : 112|8@1+ (1,0) [0|255] "" XXX
 SG_ BYTE15 : 120|8@1+ (1,0) [0|255] "" XXX
 SG_ BYTE16 : 128|8@1+ (1,0) [0|255] "" XXX
 SG_ BYTE17 : 136|8@1+ (1,0) [0|255] "" XXX
 SG_ BYTE18 : 144|8@1+ (1,0) [0|255] "" XXX
 SG_ BYTE19 : 152|8@1+ (1,0) [0|255] "" XXX
 SG_ BYTE20 : 160|8@1+ (1,0) [0|255] "" XXX
 SG_ BYTE21 : 168|8@1+ (1,0) [0|255] "" XXX
 SG_ BYTE22 : 176|8@1+ (1,0) [0|255] "" XXX
 SG_ BYTE23 : 184|8@1+ (1,0) [0|255] "" XXX
 SG_ BYTE24 : 192|8@1+ (1,0) [0|255] "" XXX
 SG_ BYTE25 : 200|8@1+ (1,0) [0|255] "" XXX
 SG_ BYTE26 : 208|8@1+ (1,0) [0|255] "" XXX
 SG_ BYTE27 : 216|8@1+ (1,0) [0|255] "" XXX
 SG_ BYTE28 : 224|8@1+ (1,0) [0|255] "" XXX
 SG_ BYTE29 : 232|8@1+ (1,0) [0|255] "" XXX
 SG_ BYTE30 : 240|8@1+ (1,0) [0|255] "" XXX
 SG_ BYTE31 : 248|8@1+ (1,0) [0|255] "" XXX

BO_ 874 BLINDSPOTS_FRONT_CORNER_2: 16 XXX
 SG_ CHECKSUM : 0|16@1+ (1,0) [0|65535] "" XXX
 SG_ COUNTER : 16|8@1+ (1,0) [0|255] "" XXX

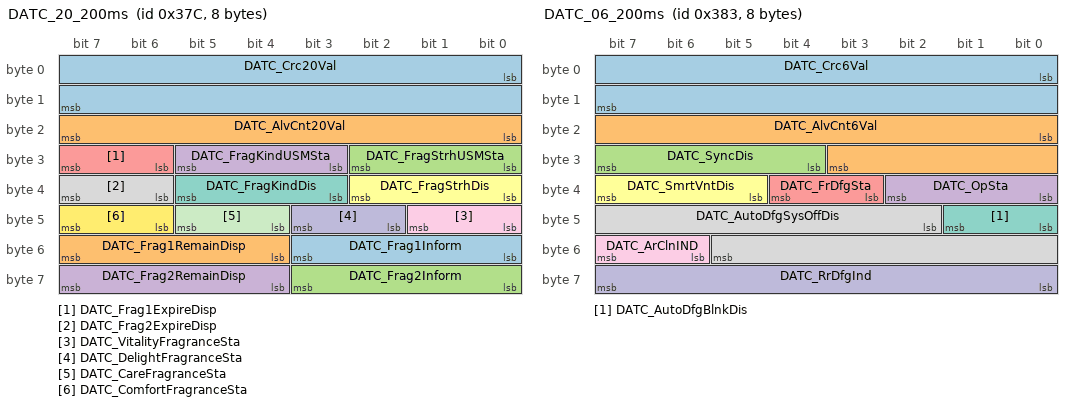
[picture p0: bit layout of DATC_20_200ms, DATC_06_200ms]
BO_ 892 DATC_20_200ms: 8 XXX
 SG_ DATC_Crc20Val : 0|16@1+ (1,0) [0|65535] "" XXX
 SG_ DATC_AlvCnt20Val : 16|8@1+ (1,0) [0|255] "" XXX
 SG_ DATC_FragStrhUSMSta : 24|3@1+ (1,0) [0|7] "" XXX
 SG_ DATC_FragKindUSMSta : 27|3@1+ (1,0) [0|7] "" XXX
 SG_ DATC_Frag1ExpireDisp : 30|2@1+ (1,0) [0|3] "" XXX
 SG_ DATC_FragStrhDis : 32|3@1+ (1,0) [0|7] "" XXX
 SG_ DATC_FragKindDis : 35|3@1+ (1,0) [0|7] "" XXX
 SG_ DATC_Frag2ExpireDisp : 38|2@1+ (1,0) [0|3] "" XXX
 SG_ DATC_VitalityFragranceSta : 40|2@1+ (1,0) [0|3] "" XXX
 SG_ DATC_DelightFragranceSta : 42|2@1+ (1,0) [0|3] "" XXX
 SG_ DATC_CareFragranceSta : 44|2@1+ (1,0) [0|3] "" XXX
 SG_ DATC_ComfortFragranceSta : 46|2@1+ (1,0) [0|3] "" XXX
 SG_ DATC_Frag1Inform : 48|4@1+ (1,0) [0|15] "" XXX
 SG_ DATC_Frag1RemainDisp : 52|4@1+ (1,0) [0|15] "" XXX
 SG_ DATC_Frag2Inform : 56|4@1+ (1,0) [0|15] "" XXX
 SG_ DATC_Frag2RemainDisp : 60|4@1+ (1,0) [0|15] "" XXX

BO_ 895 GATEWAY_STS_100ms: 8 XXX
 SG_ GATEWAY_HS_D_STS : 22|2@1+ (1,0) [0|3] "" XXX

BO_ 896 DATC_03_200ms: 8 XXX
 SG_ DATC_Crc3Val : 0|16@1+ (1,0) [0|65535] "" XXX
 SG_ DATC_AlvCnt3Val : 16|8@1+ (1,0) [0|255] "" XXX
 SG_ DATC_DrvTempCDis : 24|8@1+ (1,0) [0|255] "" XXX
 SG_ DATC_DrvTempFDis : 32|8@1+ (1,0) [0|255] "" XXX
 SG_ DATC_PassTempCDis : 40|8@1+ (1,0) [0|255] "" XXX
 SG_ DATC_PassTempFDis : 48|8@1+ (1,0) [0|255] "" XXX
 SG_ DATC_TempDispSta : 56|8@1+ (1,0) [0|255] "" XXX

BO_ 897 DATC_04_200ms: 8 XXX
 SG_ DATC_Crc4Val : 0|16@1+ (1,0) [0|65535] "" XXX
 SG_ DATC_AlvCnt4Val : 16|8@1+ (1,0) [0|255] "" XXX
 SG_ DATC_RrDrvTempCDis : 24|8@1+ (1,0) [0|255] "" XXX
 SG_ DATC_RrDrvTempFDis : 32|8@1+ (1,0) [0|255] "" XXX

BO_ 898 DATC_05_200ms: 8 XXX
 SG_ DATC_Crc5Val : 0|16@1+ (1,0) [0|65535] "" XXX
 SG_ DATC_AlvCnt5Val : 16|8@1+ (1,0) [0|255] "" XXX
 SG_ DATC_FrDrvModDis : 24|4@1+ (1,0) [0|15] "" XXX
 SG_ DATC_FrPassModDis : 28|4@1+ (1,0) [0|15] "" XXX
 SG_ DATC_ClmtTxtPopupOSD : 32|8@1+ (1,0) [0|255] "" XXX
 SG_ DATC_TempDispUnitSta : 40|2@1+ (1,0) [0|3] "" XXX
 SG_ DATC_DrvAutoDis : 42|4@1+ (1,0) [0|15] "" XXX
 SG_ DATC_FrClmtScrnDis : 46|2@1+ (1,0) [0|3] "" XXX
 SG_ DATC_AcDis : 48|2@1+ (1,0) [0|3] "" XXX
 SG_ DATC_IntakeSta : 50|6@1+ (1,0) [0|63] "" XXX

BO_ 899 DATC_06_200ms: 8 XXX
 SG_ DATC_Crc6Val : 0|16@1+ (1,0) [0|65535] "" XXX
 SG_ DATC_AlvCnt6Val : 16|12@1+ (1,0) [0|4095] "" XXX
 SG_ DATC_SyncDis : 28|4@1+ (1,0) [0|15] "" XXX
 SG_ DATC_OpSta : 32|3@1+ (1,0) [0|7] "" XXX
 SG_ DATC_FrDfgSta : 35|2@1+ (1,0) [0|3] "" XXX
 SG_ DATC_SmrtVntDis : 37|3@1+ (1,0) [0|7] "" XXX
 SG_ DATC_AutoDfgBlnkDis : 40|2@1+ (1,0) [0|3] "" XXX
 SG_ DATC_AutoDfgSysOffDis : 42|12@1+ (1,0) [0|4095] "" XXX
 SG_ DATC_ArClnIND : 54|2@1+ (1,0) [0|3] "" XXX
 SG_ DATC_RrDfgInd : 56|8@1+ (1,0) [0|255] "" XXX

BO_ 900 DATC_07_200ms: 8 XXX
 SG_ DATC_Crc7Val : 0|16@1+ (1,0) [0|65535] "" XXX
 SG_ DATC_AlvCnt7Val : 16|8@1+ (1,0) [0|255] "" XXX
 SG_ DATC_FrDrvBlwDis : 24|4@1+ (1,0) [0|15] "" XXX
 SG_ DATC_FrPsBlwDis : 28|4@1+ (1,0) [0|15] "" XXX
 SG_ DATC_HeatDis : 32|4@1+ (1,0) [0|15] "" XXX
 SG_ DATC_DrvOnlyDis : 36|20@1+ (1,0) [0|1048575] "" XXX
 SG_ DATC_AUTOStep : 56|4@1+ (1,0) [0|15] "" XXX
 SG_ DATC_IntakeDis : 60|4@1+ (1,0) [0|15] "" XXX

BO_ 902 PSM_02_200ms: 8 XXX
 SG_ PSM_DrvStSldFwdDis : 0|2@1+ (1,0) [0|3] "" XXX
 SG_ PSM_DrvStSldBckwdDis : 2|2@1+ (1,0) [0|3] "" XXX
 SG_ PSM_DrvStReclneFwdDis : 4|2@1+ (1,0) [0|3] "" XXX
 SG_ PSM_DrvStReclneBckwdDis : 6|2@1+ (1,0) [0|3] "" XXX
 SG_ PSM_IMSOptTyp : 8|16@1+ (1,0) [0|65535] "" XXX
 SG_ PSM_DrvStTiltDnDis : 10|2@1+ (1,0) [0|3] "" XXX
 SG_ PSM_DrvStHghtUpDis : 12|2@1+ (1,0) [0|3] "" XXX
 SG_ PSM_DrvStHghtDnDis : 14|2@1+ (1,0) [0|3] "" XXX
 SG_ PSM_DrvStCushExtBckwdDis : 16|2@1+ (1,0) [0|3] "" XXX
 SG_ PSM_DrvStCushExtFwdDis : 18|2@1+ (1,0) [0|3] "" XXX
 SG_ PSM_DrvStHdRstUpDis : 20|2@1+ (1,0) [0|3] "" XXX
 SG_ PSM_DrvStHdRstDnDis : 22|2@1+ (1,0) [0|3] "" XXX
 SG_ SmrtIMS_StatureRspVal : 24|4@1+ (1,0) [0|15] "" XXX
 SG_ PSM_DrvStHdRstBckwdDis : 26|6@1+ (1,0) [0|63] "" XXX
 SG_ SmrtIMS_SeatedHghtRspVal : 28|4@1+ (1,0) [0|15] "" XXX
 SG_ SmrtIMS_WghtRspVal : 32|4@1+ (1,0) [0|15] "" XXX
 SG_ PSM_DrvStLmbrLoDis : 34|2@1+ (1,0) [0|3] "" XXX
 SG_ SmartIMS_DisReq : 36|4@1+ (1,0) [0|15] "" XXX
 SG_ PSM_DrvStLmbrUpDis : 38|2@1+ (1,0) [0|3] "" XXX
 SG_ SmrtIMS_ExitSta : 40|3@1+ (1,0) [0|7] "" XXX
 SG_ PSM_DrvStBlstrInfDis : 42|6@1+ (1,0) [0|63] "" XXX
 SG_ PSM_DrvStRlxTiltUpDis : 43|2@1+ (1,0) [0|3] "" XXX
 SG_ PSM_DrvStRlxTiltDnDis : 45|2@1+ (1,0) [0|3] "" XXX
 SG_ PSM_DrvStLegUpDis : 47|2@1+ (1,0) [0|3] "" XXX
 SG_ PSM_DrvStLegDnDis : 49|7@1+ (1,0) [0|127] "" XXX

BO_ 903 APSU_03_200ms_APSU: 8 XXX
 SG_ PSM_LmbrSigSrcTyp : 44|4@1+ (1,0) [0|15] "" XXX

BO_ 904 PSM_04_200ms: 8 XXX
 SG_ PSM_DrvReclinePosition : 0|8@1+ (1,0) [0|255] "" XXX
 SG_ PSM_EsyAcsGetOnSta : 8|2@1+ (1,0) [0|3] "" XXX
 SG_ PSM_EsyAcsGetOffSta : 10|2@1+ (1,0) [0|3] "" XXX
 SG_ PSM_EsyAcsStpSta : 12|4@1+ (1,0) [0|15] "" XXX
 SG_ RRPSS_L_StSldFwdMvBtn : 16|0@1+ (1,0) [0|0] "" XXX
 SG_ RRPSS_L_StSldBwdMvBtn : 18|0@1+ (1,0) [0|0] "" XXX
 SG_ RRPSS_L_StRclFwdMvBtn : 20|0@1+ (1,0) [0|0] "" XXX
 SG_ RRPSS_L_StRclBwdMvBtn : 22|0@1+ (1,0) [0|0] "" XXX
 SG_ PSM_SWVerMinor1 : 24|8@1+ (1,0) [0|255] "" XXX
 SG_ RRPSS_L_StTltUpMvBtn : 28|0@1+ (1,0) [0|0] "" XXX
 SG_ RRPSS_L_StTltDnMvBtn : 30|0@1+ (1,0) [0|0] "" XXX
 SG_ RRPSS_L_StHRestUpMvBtn : 32|0@1+ (1,0) [0|0] "" XXX
 SG_ RRPSS_L_StHRestDnMvBtn : 34|0@1+ (1,0) [0|0] "" XXX
 SG_ RRPSS_L_StHRestFwdMvBtn : 36|0@1+ (1,0) [0|0] "" XXX
 SG_ RRPSS_L_StHRestBwdMvBtn : 38|0@1+ (1,0) [0|0] "" XXX
 SG_ RRPSS_L_StLegRestUpBtn : 40|0@1+ (1,0) [0|0] "" XXX
 SG_ RRPSS_L_StLegRestDnBtn : 42|0@1+ (1,0) [0|0] "" XXX
 SG_ PSM_DrvHeightPosition : 48|8@1+ (1,0) [0|255] "" XXX
 SG_ PSM_DrvSlidePosition : 56|8@1+ (1,0) [0|255] "" XXX

BO_ 905 SBCM_RR_01_200ms: 8 XXX
 SG_ SBCM_RR_Crc1Val : 0|8@1+ (1,0) [0|255] "" XXX
 SG_ RRDoorPushAlarm : 8|2@1+ (1,0) [0|3] "" XXX
 SG_ RR_CrashUnlockCmd : 10|2@1+ (1,0) [0|3] "" XXX
 SG_ SBCM_RR_AlvCnt1Val : 12|4@1+ (1,0) [0|15] "" XXX
 SG_ Warn_RrRtDrSwSta_SBCM : 16|2@1+ (1,0) [0|3] "" XXX
 SG_ DoorLock_RrRtDrUnLkSta_SBCM : 18|2@1+ (1,0) [0|3] "" XXX
 SG_ RR_SEAActivated : 20|2@1+ (1,0) [0|3] "" XXX
 SG_ RR_SEAWarn : 22|2@1+ (1,0) [0|3] "" XXX
 SG_ RR_SEWWarn : 24|2@1+ (1,0) [0|3] "" XXX
 SG_ RR_ReleaseWarn : 26|2@1+ (1,0) [0|3] "" XXX
 SG_ RR_SWFailAlarm : 28|2@1+ (1,0) [0|3] "" XXX
 SG_ RR_ChildLock_ActnFlSta : 30|2@1+ (1,0) [0|3] "" XXX
 SG_ RR_MRActivationAlarm : 32|2@1+ (1,0) [0|3] "" XXX
 SG_ RR_ChildLock_Status : 34|2@1+ (1,0) [0|3] "" XXX
 SG_ USM_RRGhostDoorSta : 36|4@1+ (1,0) [0|15] "" XXX
 SG_ DoorLock_PDSLkSwSta_RR : 40|2@1+ (1,0) [0|3] "" XXX
 SG_ PDS_TypeOption_RR : 42|6@1+ (1,0) [0|63] "" XXX

BO_ 907 FPM_11_200ms: 8 XXX
 SG_ FPM_Crc11Val : 0|12@1+ (1,0) [0|4095] "" XXX
 SG_ FPM_AlvCnt11Val : 12|20@1+ (1,0) [0|1048575] "" XXX
 SG_ FPM2AVN_H2PV : 32|16@1+ (1,0) [0|65535] "" XXX
 SG_ FPM2IAU_H2PV : 48|8@1+ (1,0) [0|255] "" XXX

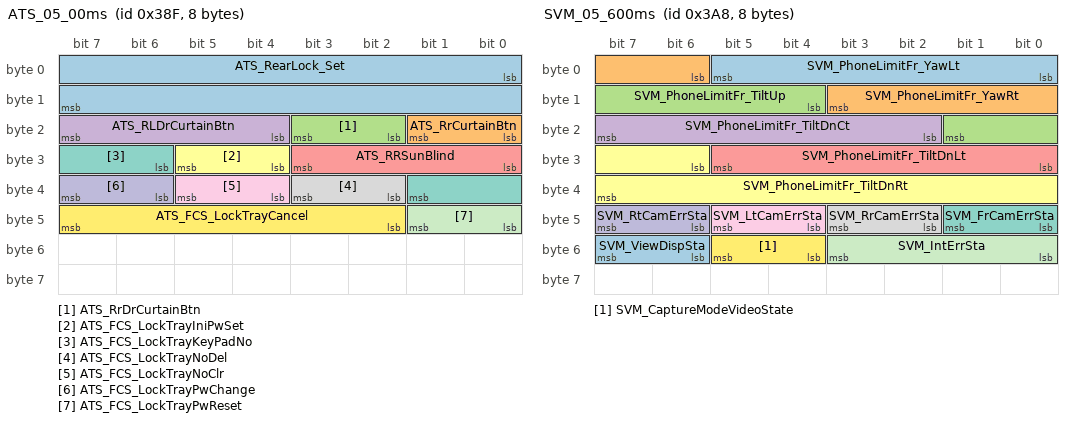
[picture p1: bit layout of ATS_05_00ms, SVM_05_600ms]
BO_ 911 ATS_05_00ms: 8 XXX
 SG_ ATS_RearLock_Set : 0|16@1+ (1,0) [0|65535] "" XXX
 SG_ ATS_RrCurtainBtn : 16|2@1+ (1,0) [0|3] "" XXX
 SG_ ATS_RrDrCurtainBtn : 18|2@1+ (1,0) [0|3] "" XXX
 SG_ ATS_RLDrCurtainBtn : 20|4@1+ (1,0) [0|15] "" XXX
 SG_ ATS_RRSunBlind : 24|4@1+ (1,0) [0|15] "" XXX
 SG_ ATS_FCS_LockTrayIniPwSet : 28|2@1+ (1,0) [0|3] "" XXX
 SG_ ATS_FCS_LockTrayKeyPadNo : 30|4@1+ (1,0) [0|15] "" XXX
 SG_ ATS_FCS_LockTrayNoDel : 34|2@1+ (1,0) [0|3] "" XXX
 SG_ ATS_FCS_LockTrayNoClr : 36|2@1+ (1,0) [0|3] "" XXX
 SG_ ATS_FCS_LockTrayPwChange : 38|2@1+ (1,0) [0|3] "" XXX
 SG_ ATS_FCS_LockTrayPwReset : 40|2@1+ (1,0) [0|3] "" XXX
 SG_ ATS_FCS_LockTrayCancel : 42|6@1+ (1,0) [0|63] "" XXX

BO_ 912 HU_GW_PE_01_HU: 8 XXX
 SG_ ThemeType : 12|4@1+ (1,0) [0|15] "" XXX
 SG_ CAM_Request : 33|7@1+ (1,0) [0|127] "" XXX

BO_ 916 BCM_19_200ms: 8 XXX
 SG_ BCM_Crc19Val : 0|8@1+ (1,0) [0|255] "" XXX
 SG_ USM_1stRrStRmndSta : 8|4@1+ (1,0) [0|15] "" XXX
 SG_ BCM_AlvCnt19Val : 12|7@1+ (1,0) [0|127] "" XXX
 SG_ USM_IBU_AutoDrUnLkReq : 19|5@1+ (1,0) [0|31] "" XXX
 SG_ USM_IBU_TwoTrnUnLkCurrentSta : 24|5@1+ (1,0) [0|31] "" XXX
 SG_ USM_IBU_RemoteWDWCurrentSta : 29|11@1+ (1,0) [0|2047] "" XXX
 SG_ USM_IBU_AutoDrLkReq2 : 40|8@1+ (1,0) [0|255] "" XXX

BO_ 917 MCU_04_200ms: 8 XXX
 SG_ MCU_Crc4Val : 0|16@1+ (1,0) [0|65535] "" XXX
 SG_ MCU_AlvCnt4Val : 16|8@1+ (1,0) [0|255] "" XXX
 SG_ VCRM_Mg1RsvrLssjsFigRdsVal : 24|10@1+ (1,0) [0|1023] "" XXX
 SG_ VCRM_Mg1MainStateSta : 34|6@1+ (1,0) [0|63] "" XXX
 SG_ VCRM_Mg1RsvrLssjsFigDevVal : 40|16@1+ (1,0) [0|65535] "" XXX
 SG_ VCRM_Mg1OpSta : 56|8@1+ (1,0) [0|255] "" XXX
 SG_ VCRM_Mg1CurRmsVal : 64|16@1+ (1,0) [0|65535] "" XXX
 SG_ MCU_Mg1MotPower_Wh : 80|16@1+ (1,0) [0|65535] "" XXX
 SG_ MCU_Mg1GenPower_Wh : 96|32@1+ (1,0) [0|4294967295] "" XXX
 SG_ VCRM_Mg1FltCodeVal : 128|8@1+ (1,0) [0|255] "" XXX

BO_ 923 OBC_01_100ms_1_OBC: 8 XXX
 SG_ ECO_SysRdySta : 42|6@1+ (1,0) [0|63] "" XXX
 SG_ OBC_AcPwrDis : 88|8@1+ (1,0) [0|255] "" XXX

BO_ 925 HCU_08_100ms_1_HCU: 8 XXX
 SG_ ENG_PwrAutoOffTimeSta : 26|19@1+ (1,0) [0|524287] "" XXX
 SG_ ENG_AutoShutOff : 45|3@1+ (1,0) [0|7] "" XXX

BO_ 928 TPMS_01_200ms: 8 XXX
 SG_ TPMS_Crc1Val : 0|16@1+ (1,0) [0|65535] "" XXX
 SG_ TPMS_AlvCnt1Val : 16|8@1+ (1,0) [0|255] "" XXX
 SG_ TPMS_FLPosWrngLmpSta : 24|2@1+ (1,0) [0|3] "" XXX
 SG_ TPMS_FRPosWrngLmpSta : 26|2@1+ (1,0) [0|3] "" XXX
 SG_ TPMS_RLPosWrngLmpSta : 28|2@1+ (1,0) [0|3] "" XXX
 SG_ TPMS_RRPosWrngLmpSta : 30|2@1+ (1,0) [0|3] "" XXX
 SG_ TPMS_FLTirePrsrVal : 32|8@1+ (1,0) [0|255] "" XXX
 SG_ TPMS_FRTirePrsrVal : 40|8@1+ (1,0) [0|255] "" XXX
 SG_ TPMS_RLTirePrsrVal : 48|8@1+ (1,0) [0|255] "" XXX
 SG_ TPMS_RRTirePrsrVal : 56|8@1+ (1,0) [0|255] "" XXX
 SG_ TPMS_SnsrSta : 64|3@1+ (1,0) [0|7] "" XXX
 SG_ TPMS_WrngLmpSta : 67|2@1+ (1,0) [0|3] "" XXX
 SG_ TPMS_TreadWrngLmpSta : 69|3@1+ (1,0) [0|7] "" XXX
 SG_ TPMS_PrsrUnitSta : 72|8@1+ (1,0) [0|255] "" XXX
 SG_ TPMS_FLMuteTimer : 80|4@1+ (1,0) [0|15] "" XXX
 SG_ TPMS_FRMuteTimer : 84|4@1+ (1,0) [0|15] "" XXX
 SG_ TPMS_RLMuteTimer : 88|4@1+ (1,0) [0|15] "" XXX
 SG_ TPMS_RRMuteTimer : 92|4@1+ (1,0) [0|15] "" XXX
 SG_ TPMS_FLSnsrRSSI : 96|6@1+ (1,0) [0|63] "" XXX
 SG_ TPMS_FRSnsrRSSI : 102|6@1+ (1,0) [0|63] "" XXX
 SG_ TPMS_RRSnsrRSSI : 108|6@1+ (1,0) [0|63] "" XXX
 SG_ TPMS_RLSnsrRSSI : 114|6@1+ (1,0) [0|63] "" XXX
 SG_ TPMS_NoiseRSSI : 120|8@1+ (1,0) [0|255] "" XXX

BO_ 934 PTGM_01_200ms: 256 XXX
 SG_ ccIC_HU_Crc5Val : 0|16@1+ (1,0) [0|65535] "" XXX
 SG_ PTGM_SpeedRValue : 8|4@1+ (1,0) [0|15] "" XXX
 SG_ PTGM_AlvCnt1Val : 12|4@1+ (1,0) [0|15] "" XXX
 SG_ ccIC_HU_AlvCnt5Val : 16|8@1+ (1,0) [0|255] "" XXX
 SG_ PTGM_ModSta : 18|4@1+ (1,0) [0|15] "" XXX
 SG_ PTGM_OptTyp : 22|2@1+ (1,0) [0|3] "" XXX
 SG_ SCC_TqIntrvntnVal : 24|16@1+ (1,0) [0|65535] "" XXX
 SG_ PTGM_TrnkLkSwSta : 26|2@1+ (1,0) [0|3] "" XXX
 SG_ PTGM_UsmSetSta : 28|4@1+ (1,0) [0|15] "" XXX
 SG_ PTGM_HeightRValue : 32|3@1+ (1,0) [0|7] "" XXX
 SG_ PTGM_OpnClsState : 35|5@1+ (1,0) [0|31] "" XXX
 SG_ TCS_LmpSta : 40|24@1+ (1,0) [0|16777215] "" XXX
 SG_ PTGM_AntiPinchSnsr : 43|13@1+ (1,0) [0|8191] "" XXX
 SG_ PTGM_TrnkTlgtOption : 56|2@1+ (1,0) [0|3] "" XXX
 SG_ PTGM_LatchType : 58|6@1+ (1,0) [0|63] "" XXX
 SG_ TCS_Sta : 64|0@1+ (1,0) [0|0] "" XXX
 SG_ SCC_EnblReq : 66|2@1+ (1,0) [0|3] "" XXX
 SG_ SCC_TqReq : 68|2@1+ (1,0) [0|3] "" XXX
 SG_ SCC_ReqLimSta : 70|16@1+ (1,0) [0|65535] "" XXX
 SG_ ESC_Sta : 72|64@1+ (1,0) [0|1.84467440737096e+19] "" XXX
 SG_ TCS_TqFlag : 86|1@1+ (1,0) [0|1] "" XXX
 SG_ MSR_TqFlag : 87|9@1+ (1,0) [0|511] "" XXX
 SG_ TCS_Req : 96|0@1+ (1,0) [0|0] "" XXX
 SG_ MSR_FuncReq : 98|64@1+ (1,0) [0|1.84467440737096e+19] "" XXX
 SG_ TCS_TqIntrvntnVal : 104|8@1+ (1,0) [0|255] "" XXX
 SG_ MSR_TqIntrvntnVal : 112|8@1+ (1,0) [0|255] "" XXX
 SG_ TCS_TqFlag_Frnt : 156|4@1+ (1,0) [0|15] "" XXX
 SG_ TCS_TqIntrvntnVal_Frnt : 160|40@1+ (1,0) [0|1099511627775] "" XXX
 SG_ TCS_MtrTrgtRpm_Flag_Frnt : 192|1@1+ (1,0) [0|1] "" XXX
 SG_ TCS_MtrTrgtRpm_Flag_Rear : 193|59@1+ (1,0) [0|5.76460752303423e+17] "" XXX
 SG_ LDM_Sta : 194|6@1+ (1,0) [0|63] "" XXX
 SG_ TCS_MtrTrgtRpm_Frnt : 200|12@1+ (1,0) [0|4095] "" XXX
 SG_ TCS_MtrTrgtRpm_Rear : 212|4@1+ (1,0) [0|15] "" XXX
 SG_ AWD_FastOpnCrdnShftCltchReq : 252|4@1+ (1,0) [0|15] "" XXX

BO_ 936 SVM_05_600ms: 8 XXX
 SG_ SVM_PhoneLimitFr_YawLt : 0|6@1+ (1,0) [0|63] "" XXX
 SG_ SVM_PhoneLimitFr_YawRt : 6|6@1+ (1,0) [0|63] "" XXX
 SG_ SVM_PhoneLimitFr_TiltUp : 12|6@1+ (1,0) [0|63] "" XXX
 SG_ SVM_PhoneLimitFr_TiltDnCt : 18|6@1+ (1,0) [0|63] "" XXX
 SG_ SVM_PhoneLimitFr_TiltDnLt : 24|6@1+ (1,0) [0|63] "" XXX
 SG_ SVM_PhoneLimitFr_TiltDnRt : 30|10@1+ (1,0) [0|1023] "" XXX
 SG_ SVM_FrCamErrSta : 40|2@1+ (1,0) [0|3] "" XXX
 SG_ SVM_RrCamErrSta : 42|2@1+ (1,0) [0|3] "" XXX
 SG_ SVM_LtCamErrSta : 44|2@1+ (1,0) [0|3] "" XXX
 SG_ SVM_RtCamErrSta : 46|2@1+ (1,0) [0|3] "" XXX
 SG_ SVM_IntErrSta : 48|4@1+ (1,0) [0|15] "" XXX
 SG_ SVM_CaptureModeVideoState : 52|2@1+ (1,0) [0|3] "" XXX
 SG_ SVM_ViewDispSta : 54|2@1+ (1,0) [0|3] "" XXX

BO_ 937 SVM_06_600ms: 8 XXX
 SG_ SVM_PhoneLimitRr_YawLt : 0|6@1+ (1,0) [0|63] "" XXX
 SG_ SVM_PhoneLimitRr_YawRt : 6|6@1+ (1,0) [0|63] "" XXX
 SG_ SVM_PhoneLimitRr_TiltUp : 12|6@1+ (1,0) [0|63] "" XXX
 SG_ SVM_PhoneLimitRr_TiltDnCt : 18|6@1+ (1,0) [0|63] "" XXX
 SG_ SVM_PhoneLimitRr_TiltDnLt : 24|6@1+ (1,0) [0|63] "" XXX
 SG_ SVM_PhoneLimitRr_TiltDnRt : 30|2@1+ (1,0) [0|3] "" XXX

BO_ 938 CDM_HS_01_200ms: 8 XXX
 SG_ CDM_HS_Crc1Val : 0|12@1+ (1,0) [0|4095] "" XXX
 SG_ CDM_HS_AlvCnt1Val : 12|8@1+ (1,0) [0|255] "" XXX
 SG_ CDM_HS_CmdStatus : 20|13@1+ (1,0) [0|8191] "" XXX
 SG_ CDM_HS_OpnClsState : 33|3@1+ (1,0) [0|7] "" XXX
 SG_ CDM_HS_WarnMsg : 36|2@1+ (1,0) [0|3] "" XXX
 SG_ CDM_HS_OptTyp : 38|2@1+ (1,0) [0|3] "" XXX

BO_ 940 SVM_07_600ms: 8 XXX
 SG_ SVM_PhoneLimitLt_YawLt : 0|6@1+ (1,0) [0|63] "" XXX
 SG_ SVM_PhoneLimitLt_YawRt : 6|6@1+ (1,0) [0|63] "" XXX
 SG_ SVM_PhoneLimitLt_TiltUp : 12|6@1+ (1,0) [0|63] "" XXX
 SG_ SVM_PhoneLimitLt_TiltDnCt : 18|6@1+ (1,0) [0|63] "" XXX
 SG_ SVM_PhoneLimitLt_TiltDnLt : 24|6@1+ (1,0) [0|63] "" XXX
 SG_ SVM_PhoneLimitLt_TiltDnRt : 30|2@1+ (1,0) [0|3] "" XXX

BO_ 941 SVM_08_600ms: 8 XXX
 SG_ SVM_PhoneLimitRt_YawLt : 0|6@1+ (1,0) [0|63] "" XXX
 SG_ SVM_PhoneLimitRt_YawRt : 6|6@1+ (1,0) [0|63] "" XXX
 SG_ SVM_PhoneLimitRt_TiltUp : 12|6@1+ (1,0) [0|63] "" XXX
 SG_ SVM_PhoneLimitRt_TiltDnCt : 18|6@1+ (1,0) [0|63] "" XXX
 SG_ SVM_PhoneLimitRt_TiltDnLt : 24|6@1+ (1,0) [0|63] "" XXX
 SG_ SVM_PhoneLimitRt_TiltDnRt : 30|2@1+ (1,0) [0|3] "" XXX

BO_ 942 HU_AMP_E: 8 XXX
 SG_ AMP_Beep1VolumeStep_DATC : 0|8@1+ (1,0) [0|255] "" XXX
 SG_ AMP_SPDIF_OutputCh_Select : 8|16@1+ (1,0) [0|65535] "" XXX
 SG_ AMP_Analog_OutputCh_Select : 24|16@1+ (1,0) [0|65535] "" XXX
 SG_ AMP_Beep1_OutputCh_Select : 40|16@1+ (1,0) [0|65535] "" XXX
 SG_ AMP_Beep1KBDVolumeStep : 56|8@1+ (1,0) [0|255] "" XXX

BO_ 945 DATC_09_200ms: 8 XXX
 SG_ DATC_Crc9Val : 0|16@1+ (1,0) [0|65535] "" XXX
 SG_ DATC_AlvCnt9Val : 16|16@1+ (1,0) [0|65535] "" XXX
 SG_ DATC_RrBlwDis : 32|8@1+ (1,0) [0|255] "" XXX
 SG_ DATC_ArClnSysOSD : 40|4@1+ (1,0) [0|15] "" XXX
 SG_ DATC_ArClnStepClr : 44|4@1+ (1,0) [0|15] "" XXX
 SG_ DATC_ArClnSmblTyp : 48|4@1+ (1,0) [0|15] "" XXX
 SG_ DATC_AfterBlowUSMSta : 52|2@1+ (1,0) [0|3] "" XXX
 SG_ DATC_SchdldVntUSMSta : 54|2@1+ (1,0) [0|3] "" XXX
 SG_ DATC_SchdldVntHrSta : 56|5@1+ (1,0) [0|31] "" XXX
 SG_ DATC_SchdldVntMinSta : 61|3@1+ (1,0) [0|7] "" XXX

BO_ 946 DATC_10_200ms: 8 XXX
 SG_ DATC_Crc10Val : 0|16@1+ (1,0) [0|65535] "" XXX
 SG_ DATC_AlvCnt10Val : 16|8@1+ (1,0) [0|255] "" XXX
 SG_ DATC_Typ : 24|8@1+ (1,0) [0|255] "" XXX
 SG_ DATC_Opt1Typ : 32|8@1+ (1,0) [0|255] "" XXX
 SG_ DATC_Opt3Typ : 40|8@1+ (1,0) [0|255] "" XXX
 SG_ DATC_Opt2Typ : 48|4@1+ (1,0) [0|15] "" XXX
 SG_ DATC_Opt4Typ : 52|6@1+ (1,0) [0|63] "" XXX
 SG_ DATC_StrWhlUSMSta : 58|2@1+ (1,0) [0|3] "" XXX
 SG_ DATC_StrWhlHtngReq : 60|4@1+ (1,0) [0|15] "" XXX

BO_ 949 ILCU_LH_02_50ms_ILCULH_HeightSnsrFront: 8 XXX
 SG_ OBC_AcVolt_SubA_Val : 146|9@1+ (1,0) [0|511] "" XXX
 SG_ OBC_AcVolt_SubB_Val : 155|5@1+ (1,0) [0|31] "" XXX

BO_ 960 BCM_11_200ms_USM: 8 XXX
 SG_ USM_ROA_RrStRmndSta : 27|5@1+ (1,0) [0|31] "" XXX

BO_ 961 BLINKER_STALKS: 8 XXX
 SG_ CHECKSUM_MAYBE : 7|8@0+ (1,0) [0|255] "" XXX
 SG_ COUNTER_ALT : 15|4@0+ (1,0) [0|15] "" XXX
 SG_ HIGHBEAM_FORWARD : 18|1@0+ (1,0) [0|1] "" XXX
 SG_ LIGHT_KNOB_POSITION : 21|2@0+ (1,0) [0|3] "" XXX
 SG_ HIGHBEAM_BACKWARD : 26|1@0+ (1,0) [0|1] "" XXX
 SG_ LEFT_BLINKER : 30|1@0+ (1,0) [0|1] "" XXX
 SG_ RIGHT_BLINKER : 32|1@0+ (1,0) [0|1] "" XXX

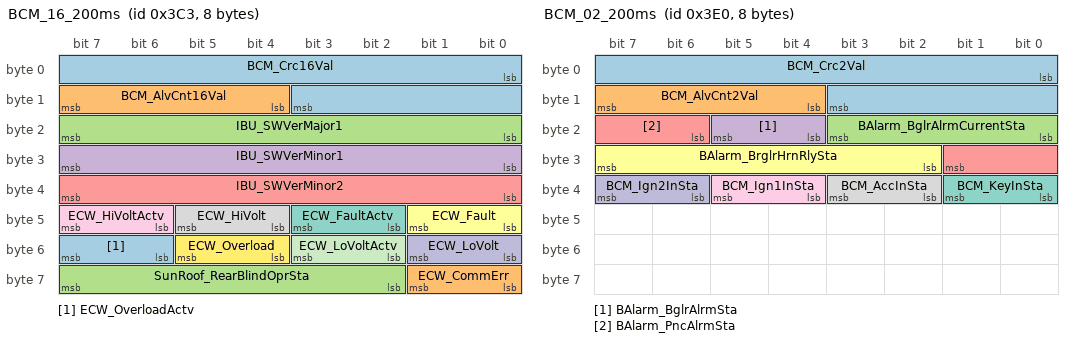
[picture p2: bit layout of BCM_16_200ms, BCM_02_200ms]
BO_ 963 BCM_16_200ms: 8 XXX
 SG_ BCM_Crc16Val : 0|12@1+ (1,0) [0|4095] "" XXX
 SG_ BCM_AlvCnt16Val : 12|4@1+ (1,0) [0|15] "" XXX
 SG_ IBU_SWVerMajor1 : 16|8@1+ (1,0) [0|255] "" XXX
 SG_ IBU_SWVerMinor1 : 24|8@1+ (1,0) [0|255] "" XXX
 SG_ IBU_SWVerMinor2 : 32|8@1+ (1,0) [0|255] "" XXX
 SG_ ECW_Fault : 40|2@1+ (1,0) [0|3] "" XXX
 SG_ ECW_FaultActv : 42|2@1+ (1,0) [0|3] "" XXX
 SG_ ECW_HiVolt : 44|2@1+ (1,0) [0|3] "" XXX
 SG_ ECW_HiVoltActv : 46|2@1+ (1,0) [0|3] "" XXX
 SG_ ECW_LoVolt : 48|2@1+ (1,0) [0|3] "" XXX
 SG_ ECW_LoVoltActv : 50|2@1+ (1,0) [0|3] "" XXX
 SG_ ECW_Overload : 52|2@1+ (1,0) [0|3] "" XXX
 SG_ ECW_OverloadActv : 54|2@1+ (1,0) [0|3] "" XXX
 SG_ ECW_CommErr : 56|2@1+ (1,0) [0|3] "" XXX
 SG_ SunRoof_RearBlindOprSta : 58|6@1+ (1,0) [0|63] "" XXX

BO_ 975 HU_GW_PE_01_CF_AVN: 8 XXX
 SG_ C_BLE_ProfileIDRValue : 12|4@1+ (1,0) [0|15] "" XXX

BO_ 979 HU_FRU_E: 8 XXX
 SG_ CF_AVN_FRButtonInput : 0|4@1+ (1,0) [0|15] "" XXX
 SG_ CF_AVN_FREntryUsageNval : 4|4@1+ (1,0) [0|15] "" XXX

BO_ 981 APSS_01_200ms: 8 XXX
 SG_ APSS_StSldFwdMvBtn : 16|2@1+ (1,0) [0|3] "" XXX
 SG_ APSS_StSldBwdMvBtn : 18|2@1+ (1,0) [0|3] "" XXX
 SG_ APSS_StRclFwdMvBtn : 20|2@1+ (1,0) [0|3] "" XXX
 SG_ APSS_StRclBwdMvBtn : 22|2@1+ (1,0) [0|3] "" XXX
 SG_ APSS_StHgtUpMvBtn : 24|2@1+ (1,0) [0|3] "" XXX
 SG_ APSS_StHgtDnMvBtn : 26|2@1+ (1,0) [0|3] "" XXX
 SG_ APSS_StTltUpMvBtn : 28|2@1+ (1,0) [0|3] "" XXX
 SG_ APSS_StTltDnMvBtn : 30|2@1+ (1,0) [0|3] "" XXX
 SG_ APSS_StHRestUpMvBtn : 32|2@1+ (1,0) [0|3] "" XXX
 SG_ APSS_StHRestDnMvBtn : 34|2@1+ (1,0) [0|3] "" XXX
 SG_ APSS_StHRestFwdMvBtn : 36|2@1+ (1,0) [0|3] "" XXX
 SG_ APSS_StHRestBwdMvBtn : 38|2@1+ (1,0) [0|3] "" XXX
 SG_ APSS_StLegUpMvBtn : 40|2@1+ (1,0) [0|3] "" XXX
 SG_ APSS_StLegDnMvBtn : 42|2@1+ (1,0) [0|3] "" XXX
 SG_ APSS_StRlxModeBtn : 44|2@1+ (1,0) [0|3] "" XXX
 SG_ APSS_StRlxReturnBtn : 46|2@1+ (1,0) [0|3] "" XXX
 SG_ APSS_StRlxTltUpMvBtn : 48|2@1+ (1,0) [0|3] "" XXX
 SG_ APSS_StRlxTltDnMvBtn : 50|6@1+ (1,0) [0|63] "" XXX

BO_ 992 BCM_02_200ms: 8 XXX
 SG_ BCM_Crc2Val : 0|12@1+ (1,0) [0|4095] "" XXX
 SG_ BCM_AlvCnt2Val : 12|4@1+ (1,0) [0|15] "" XXX
 SG_ BAlarm_BglrAlrmCurrentSta : 16|4@1+ (1,0) [0|15] "" XXX
 SG_ BAlarm_BglrAlrmSta : 20|2@1+ (1,0) [0|3] "" XXX
 SG_ BAlarm_PncAlrmSta : 22|4@1+ (1,0) [0|15] "" XXX
 SG_ BAlarm_BrglrHrnRlySta : 26|6@1+ (1,0) [0|63] "" XXX
 SG_ BCM_KeyInSta : 32|2@1+ (1,0) [0|3] "" XXX
 SG_ BCM_AccInSta : 34|2@1+ (1,0) [0|3] "" XXX
 SG_ BCM_Ign1InSta : 36|2@1+ (1,0) [0|3] "" XXX
 SG_ BCM_Ign2InSta : 38|2@1+ (1,0) [0|3] "" XXX

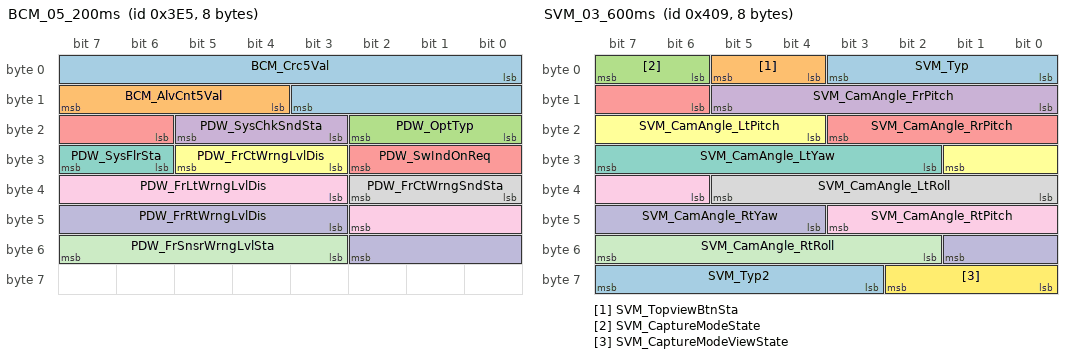
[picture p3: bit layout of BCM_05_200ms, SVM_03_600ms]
BO_ 997 BCM_05_200ms: 8 XXX
 SG_ BCM_Crc5Val : 0|12@1+ (1,0) [0|4095] "" XXX
 SG_ BCM_AlvCnt5Val : 12|4@1+ (1,0) [0|15] "" XXX
 SG_ PDW_OptTyp : 16|3@1+ (1,0) [0|7] "" XXX
 SG_ PDW_SysChkSndSta : 19|3@1+ (1,0) [0|7] "" XXX
 SG_ PDW_SwIndOnReq : 22|5@1+ (1,0) [0|31] "" XXX
 SG_ PDW_FrCtWrngLvlDis : 27|3@1+ (1,0) [0|7] "" XXX
 SG_ PDW_SysFlrSta : 30|2@1+ (1,0) [0|3] "" XXX
 SG_ PDW_FrCtWrngSndSta : 32|3@1+ (1,0) [0|7] "" XXX
 SG_ PDW_FrLtWrngLvlDis : 35|8@1+ (1,0) [0|255] "" XXX
 SG_ PDW_FrRtWrngLvlDis : 43|8@1+ (1,0) [0|255] "" XXX
 SG_ PDW_FrSnsrWrngLvlSta : 51|5@1+ (1,0) [0|31] "" XXX

BO_ 998 BCM_06_200ms: 8 XXX
 SG_ BCM_Crc6Val : 0|12@1+ (1,0) [0|4095] "" XXX
 SG_ BCM_AlvCnt6Val : 12|4@1+ (1,0) [0|15] "" XXX
 SG_ PDW_RrCtWrngLvlDis : 16|8@1+ (1,0) [0|255] "" XXX
 SG_ PDW_RrLtWrngLvlDis : 24|8@1+ (1,0) [0|255] "" XXX
 SG_ PDW_RrRtWrngLvlDis : 32|8@1+ (1,0) [0|255] "" XXX

BO_ 999 TMU_HU_E_01: 8 XXX
 SG_ TMU_eCall : 27|5@1+ (1,0) [0|31] "" XXX

BO_ 1000 ECALL_HU_E_01: 8 XXX
 SG_ TMU_eCall_Fail : 6|2@1+ (1,0) [0|3] "" XXX

BO_ 1002 UNK_DEV_MAYBE: 8 XXX
 SG_ DVRS_Prk_time_HU_OTA_E_00_HU_OTA_Update : 16|8@1+ (1,0) [0|255] "" XXX
 SG_ DVRS_Prk_Crash_Event_Count_BLTN_CAM_HU_PE_00_200ms_BLTN_CAM_DEV : 24|8@1+ (1,0) [0|255] "" XXX
 SG_ DVRS_Status_HU_CCS_PE_00_HU_CALL : 32|8@1+ (1,0) [0|255] "" XXX
 SG_ DVRS_BeepSound_BLTN_CAM_E_00_BLTN_CAM_Dis_Touch : 38|2@1+ (1,0) [0|3] "" XXX

BO_ 1003 RLPSM_01_200ms: 8 XXX
 SG_ PSM_BzrOnRLReq : 0|10@1+ (1,0) [0|1023] "" XXX
 SG_ RLPSM_RearModeState : 10|8@1+ (1,0) [0|255] "" XXX
 SG_ RLPSM_RLStEsyAcsUSMSta : 18|6@1+ (1,0) [0|63] "" XXX
 SG_ RLPSM_RLSlidePosition : 24|24@1+ (1,0) [0|16777215] "" XXX
 SG_ RLPSM_LimSetSta : 48|8@1+ (1,0) [0|255] "" XXX

BO_ 1019 HU_MOOD_E: 8 XXX
 SG_ HU_MoodTherapyDrSeat : 0|2@1+ (1,0) [0|3] "" XXX
 SG_ HU_MoodTherapyPsSeat : 2|2@1+ (1,0) [0|3] "" XXX
 SG_ HU_MoodTherapyRlSeat : 4|2@1+ (1,0) [0|3] "" XXX
 SG_ HU_MoodTherapyRrSeat : 6|2@1+ (1,0) [0|3] "" XXX
 SG_ HU_VitalityMoodLamp : 8|2@1+ (1,0) [0|3] "" XXX
 SG_ HU_VitalityFragrance : 10|2@1+ (1,0) [0|3] "" XXX
 SG_ HU_VitalityCurtain : 12|2@1+ (1,0) [0|3] "" XXX
 SG_ HU_DelightMoodLamp : 14|2@1+ (1,0) [0|3] "" XXX
 SG_ HU_DelightFragrance : 16|2@1+ (1,0) [0|3] "" XXX
 SG_ HU_DelightCurtain : 18|2@1+ (1,0) [0|3] "" XXX
 SG_ HU_CareMoodLamp : 20|2@1+ (1,0) [0|3] "" XXX
 SG_ HU_CareFragrance : 22|2@1+ (1,0) [0|3] "" XXX
 SG_ HU_CareMassage : 24|2@1+ (1,0) [0|3] "" XXX
 SG_ HU_CareCurtain : 26|2@1+ (1,0) [0|3] "" XXX
 SG_ HU_ComfortMoodLamp : 28|2@1+ (1,0) [0|3] "" XXX
 SG_ HU_ComfortFragrance : 30|2@1+ (1,0) [0|3] "" XXX
 SG_ HU_ComfortMassage : 32|2@1+ (1,0) [0|3] "" XXX
 SG_ HU_ComfortCurtain : 34|2@1+ (1,0) [0|3] "" XXX
 SG_ HU_MoodTherapyMode : 36|4@1+ (1,0) [0|15] "" XXX

BO_ 1020 MLM_03_200ms: 8 XXX
 SG_ MLM_VitalityMoodLightSta : 0|2@1+ (1,0) [0|3] "" XXX
 SG_ MLM_CareMoodLightSta : 2|2@1+ (1,0) [0|3] "" XXX
 SG_ MLM_ComfortMoodLightSta : 4|2@1+ (1,0) [0|3] "" XXX
 SG_ MLM_DelightMoodLighSta : 6|2@1+ (1,0) [0|3] "" XXX

BO_ 1024 SVM_04_200ms: 8 XXX
 SG_ BVM_View2Sta : 32|5@1+ (1,0) [0|31] "" XXX
 SG_ SVM_ExteriorColorRedNValueSta : 37|9@1+ (1,0) [0|511] "" XXX
 SG_ SVM_ExteriorColorGreenNValueSta : 46|9@1+ (1,0) [0|511] "" XXX
 SG_ SVM_ExteriorColorBlueNValueSta : 55|1@1+ (1,0) [0|1] "" XXX

BO_ 1029 ICU_12_200ms: 8 XXX
 SG_ ICU_Crc12Val : 0|12@1+ (1,0) [0|4095] "" XXX
 SG_ ICU_AlvCnt12Val : 12|8@1+ (1,0) [0|255] "" XXX
 SG_ DoorLock_CtrlDrLkSwSta_ICU : 20|2@1+ (1,0) [0|3] "" XXX
 SG_ DoorLock_CtrlDrUnLkSwSta_ICU : 22|18@1+ (1,0) [0|262143] "" XXX
 SG_ ICU_IGN3On_ReqState_New : 40|8@1+ (1,0) [0|255] "" XXX
 SG_ ICU_BattMngAlert : 48|8@1+ (1,0) [0|255] "" XXX

BO_ 1030 APSM_01_200ms: 8 XXX
 SG_ APSM_SWVerMajor1 : 32|8@1+ (1,0) [0|255] "" XXX
 SG_ APSM_SWVerMinor1 : 40|8@1+ (1,0) [0|255] "" XXX
 SG_ APSM_SWVerMinor2 : 48|8@1+ (1,0) [0|255] "" XXX

BO_ 1031 APSM_02_200ms: 8 XXX
 SG_ APSM_RearModeEnable : 16|5@1+ (1,0) [0|31] "" XXX
 SG_ APSM_AstStEsyAcsUSMSta : 21|3@1+ (1,0) [0|7] "" XXX
 SG_ APSM_ReturnModeState : 24|3@1+ (1,0) [0|7] "" XXX
 SG_ APSM_RelaxModeState : 27|3@1+ (1,0) [0|7] "" XXX
 SG_ APSM_WalkInEnable : 30|2@1+ (1,0) [0|3] "" XXX
 SG_ APSM_LimSetSta : 32|12@1+ (1,0) [0|4095] "" XXX
 SG_ APSM_FootRest_Opt : 44|2@1+ (1,0) [0|3] "" XXX
 SG_ APSM_RSE_Opt : 46|2@1+ (1,0) [0|3] "" XXX

BO_ 1032 IAU_24_200ms: 8 XXX
 SG_ IAU_Year : 0|16@1+ (1,0) [0|65535] "" XXX
 SG_ IAU_Month : 16|8@1+ (1,0) [0|255] "" XXX
 SG_ IAU_Date : 24|16@1+ (1,0) [0|65535] "" XXX
 SG_ IAU_SWVerMajor1 : 40|8@1+ (1,0) [0|255] "" XXX
 SG_ IAU_SWVerMinor1 : 48|8@1+ (1,0) [0|255] "" XXX
 SG_ IAU_SWVerMinor2 : 56|8@1+ (1,0) [0|255] "" XXX

BO_ 1033 SVM_03_600ms: 8 XXX
 SG_ SVM_Typ : 0|4@1+ (1,0) [0|15] "" XXX
 SG_ SVM_TopviewBtnSta : 4|2@1+ (1,0) [0|3] "" XXX
 SG_ SVM_CaptureModeState : 6|2@1+ (1,0) [0|3] "" XXX
 SG_ SVM_CamAngle_FrPitch : 8|6@1+ (1,0) [0|63] "" XXX
 SG_ SVM_CamAngle_RrPitch : 14|6@1+ (1,0) [0|63] "" XXX
 SG_ SVM_CamAngle_LtPitch : 20|6@1+ (1,0) [0|63] "" XXX
 SG_ SVM_CamAngle_LtYaw : 26|6@1+ (1,0) [0|63] "" XXX
 SG_ SVM_CamAngle_LtRoll : 32|6@1+ (1,0) [0|63] "" XXX
 SG_ SVM_CamAngle_RtPitch : 38|6@1+ (1,0) [0|63] "" XXX
 SG_ SVM_CamAngle_RtYaw : 44|6@1+ (1,0) [0|63] "" XXX
 SG_ SVM_CamAngle_RtRoll : 50|6@1+ (1,0) [0|63] "" XXX
 SG_ SVM_CaptureModeViewState : 56|3@1+ (1,0) [0|7] "" XXX
 SG_ SVM_Typ2 : 59|5@1+ (1,0) [0|31] "" XXX

BO_ 1036 IAU_23_200ms: 8 XXX
 SG_ IAU_Manufacturer : 0|8@1+ (1,0) [0|255] "" XXX
 SG_ IAU_VendorCode : 8|24@1+ (1,0) [0|16777215] "" XXX
 SG_ IAU_Serial : 32|8@1+ (1,0) [0|255] "" XXX

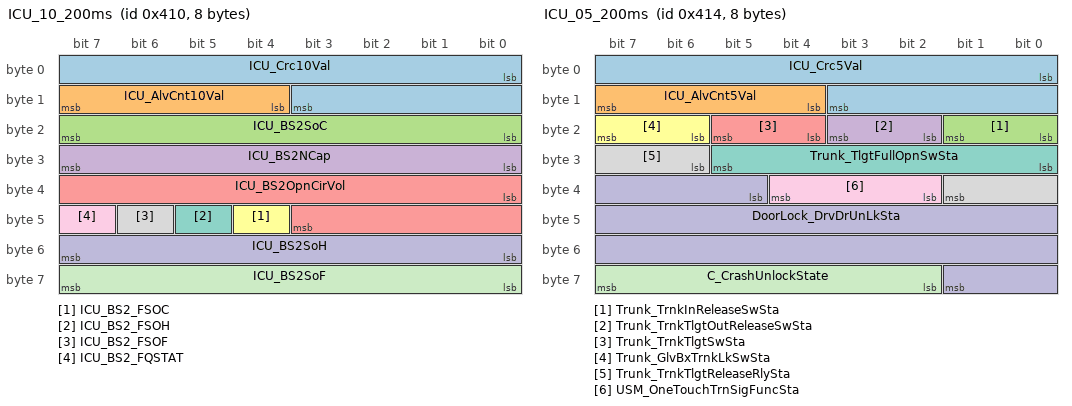
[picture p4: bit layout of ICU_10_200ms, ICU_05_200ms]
BO_ 1040 ICU_10_200ms: 8 XXX
 SG_ ICU_Crc10Val : 0|12@1+ (1,0) [0|4095] "" XXX
 SG_ ICU_AlvCnt10Val : 12|4@1+ (1,0) [0|15] "" XXX
 SG_ ICU_BS2SoC : 16|8@1+ (1,0) [0|255] "" XXX
 SG_ ICU_BS2NCap : 24|8@1+ (1,0) [0|255] "" XXX
 SG_ ICU_BS2OpnCirVol : 32|12@1+ (1,0) [0|4095] "" XXX
 SG_ ICU_BS2_FSOC : 44|1@1+ (1,0) [0|1] "" XXX
 SG_ ICU_BS2_FSOH : 45|1@1+ (1,0) [0|1] "" XXX
 SG_ ICU_BS2_FSOF : 46|1@1+ (1,0) [0|1] "" XXX
 SG_ ICU_BS2_FQSTAT : 47|1@1+ (1,0) [0|1] "" XXX
 SG_ ICU_BS2SoH : 48|8@1+ (1,0) [0|255] "" XXX
 SG_ ICU_BS2SoF : 56|8@1+ (1,0) [0|255] "" XXX

BO_ 1041 ICU_02_200ms: 8 XXX
 SG_ ICU_Crc2Val : 0|7@1+ (1,0) [0|127] "" XXX
 SG_ CHECKSUM_MAYBE : 7|1@0+ (1,0) [0|1] "" XXX
 SG_ ICU_Haptic_OPT : 8|4@1+ (1,0) [0|15] "" XXX
 SG_ ICU_AlvCnt2Val : 12|3@1+ (1,0) [0|7] "" XXX
 SG_ COUNTER_ALT : 15|4@0+ (1,0) [0|15] "" XXX
 SG_ Autocut_DlvryModSta : 20|1@1+ (1,0) [0|1] "" XXX
 SG_ SCM_Haptic_OPT : 21|1@1+ (1,0) [0|1] "" XXX
 SG_ DoorLock_AsstDrUnLkSta : 22|2@1+ (1,0) [0|3] "" XXX
 SG_ Warn_DrvDrSwSta : 24|1@1+ (1,0) [0|1] "" XXX
 SG_ DoorLock_DrvKeyUnLkSwSta : 26|2@1+ (1,0) [0|3] "" XXX
 SG_ DoorLock_RrLftDrUnLkSta : 28|2@1+ (1,0) [0|3] "" XXX
 SG_ DoorLock_RrRtDrUnLkSta : 30|4@1+ (1,0) [0|15] "" XXX
 SG_ Warn_AsstDrSwSta : 34|1@0+ (1,0) [0|1] "" XXX
 SG_ Warn_AsstStBltSwSta : 36|1@0+ (1,0) [0|1] "" XXX
 SG_ Warn_BrkFldSwSta : 38|2@1+ (1,0) [0|3] "" XXX
 SG_ DoorLock_DrvKeyLkSwSta : 40|2@1+ (1,0) [0|3] "" XXX
 SG_ Warn_DrvStBltSwSta : 42|1@0+ (1,0) [0|1] "" XXX
 SG_ Warn_HoodSwSta : 44|2@1+ (1,0) [0|3] "" XXX
 SG_ Warn_PassStOccSta : 46|4@1+ (1,0) [0|15] "" XXX
 SG_ Warn_RrCtrStBltSwSta : 50|2@1+ (1,0) [0|3] "" XXX
 SG_ Warn_RrLftDrSwSta : 52|1@0+ (1,0) [0|1] "" XXX
 SG_ Warn_RrLftStBltSwSta : 54|2@1+ (1,0) [0|3] "" XXX
 SG_ Warn_RrRtDrSwSta : 56|1@0+ (1,0) [0|1] "" XXX
 SG_ Warn_RrRtStBltSwSta : 58|2@1+ (1,0) [0|3] "" XXX
 SG_ Warn_HoodSwMemorySta : 60|2@1+ (1,0) [0|3] "" XXX
 SG_ Warn_WshrFldSwSta : 62|2@1+ (1,0) [0|3] "" XXX

BO_ 1043 ICU_04_200ms: 8 XXX
 SG_ ICU_Crc4Val : 0|8@1+ (1,0) [0|255] "" XXX
 SG_ Lamp_TrnSigLmpLftActiveSt : 8|1@0+ (1,0) [0|1] "" XXX
 SG_ Lamp_TrnSigLmpRtActiveSt : 10|1@0+ (1,0) [0|1] "" XXX
 SG_ ICU_AlvCnt4Val : 12|3@1+ (1,0) [0|7] "" XXX
 SG_ COUNTER_ALT : 15|4@0+ (1,0) [0|15] "" XXX
 SG_ LEFT_LAMP : 20|1@0+ (1,0) [0|1] "" XXX
 SG_ RIGHT_LAMP : 22|1@0+ (1,0) [0|1] "" XXX
 SG_ ExtLamp_HzrdSwSta : 26|4@1+ (1,0) [0|15] "" XXX
 SG_ IntLamp_InlTailLmpSta : 30|28@1+ (1,0) [0|268435455] "" XXX
 SG_ Lamp_TrnSigLmpLftOnReq : 58|1@1+ (1,0) [0|1] "" XXX
 SG_ LEFT_LAMP_ALT : 59|1@0+ (1,0) [0|1] "" XXX
 SG_ Lamp_TrnSigLmpRtOnReq : 60|1@1+ (1,0) [0|1] "" XXX
 SG_ RIGHT_LAMP_ALT : 61|1@0+ (1,0) [0|1] "" XXX
 SG_ ICU_HDPSpprtRdy : 62|1@0+ (1,0) [0|1] "" XXX

BO_ 1044 ICU_05_200ms: 8 XXX
 SG_ ICU_Crc5Val : 0|12@1+ (1,0) [0|4095] "" XXX
 SG_ ICU_AlvCnt5Val : 12|4@1+ (1,0) [0|15] "" XXX
 SG_ Trunk_TrnkInReleaseSwSta : 16|2@1+ (1,0) [0|3] "" XXX
 SG_ Trunk_TrnkTlgtOutReleaseSwSta : 18|2@1+ (1,0) [0|3] "" XXX
 SG_ Trunk_TrnkTlgtSwSta : 20|2@1+ (1,0) [0|3] "" XXX
 SG_ Trunk_GlvBxTrnkLkSwSta : 22|2@1+ (1,0) [0|3] "" XXX
 SG_ Trunk_TlgtFullOpnSwSta : 24|6@1+ (1,0) [0|63] "" XXX
 SG_ Trunk_TrnkTlgtReleaseRlySta : 30|4@1+ (1,0) [0|15] "" XXX
 SG_ USM_OneTouchTrnSigFuncSta : 34|3@1+ (1,0) [0|7] "" XXX
 SG_ DoorLock_DrvDrUnLkSta : 37|21@1+ (1,0) [0|2097151] "" XXX
 SG_ C_CrashUnlockState : 58|6@1+ (1,0) [0|63] "" XXX

BO_ 1046 ICU_06_200ms: 8 XXX
 SG_ ICU_Crc6Val : 0|12@1+ (1,0) [0|4095] "" XXX
 SG_ ICU_AlvCnt6Val : 12|38@1+ (1,0) [0|274877906943] "" XXX
 SG_ Lamp_RrTrnSigLmpLftOpnSta : 50|2@1+ (1,0) [0|3] "" XXX
 SG_ Lamp_RrTrnSigLmpRtOpnSta : 52|2@1+ (1,0) [0|3] "" XXX
 SG_ Lamp_FrTrnSigLmpLftOpnSta : 54|2@1+ (1,0) [0|3] "" XXX
 SG_ Lamp_FrTrnSigLmpRtOpnSta : 56|8@1+ (1,0) [0|255] "" XXX

BO_ 1047 ICU_07_200ms: 8 XXX
 SG_ ICU_Crc7Val : 0|12@1+ (1,0) [0|4095] "" XXX
 SG_ ICU_AlvCnt7Val : 12|4@1+ (1,0) [0|15] "" XXX

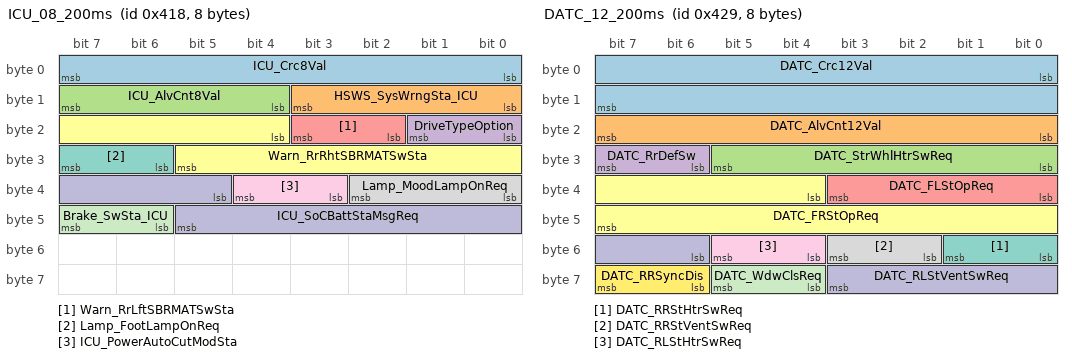
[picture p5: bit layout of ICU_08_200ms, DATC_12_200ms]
BO_ 1048 ICU_08_200ms: 8 XXX
 SG_ ICU_Crc8Val : 0|8@1+ (1,0) [0|255] "" XXX
 SG_ HSWS_SysWrngSta_ICU : 8|4@1+ (1,0) [0|15] "" XXX
 SG_ ICU_AlvCnt8Val : 12|4@1+ (1,0) [0|15] "" XXX
 SG_ DriveTypeOption : 16|2@1+ (1,0) [0|3] "" XXX
 SG_ Warn_RrLftSBRMATSwSta : 18|2@1+ (1,0) [0|3] "" XXX
 SG_ Warn_RrRhtSBRMATSwSta : 20|10@1+ (1,0) [0|1023] "" XXX
 SG_ Lamp_FootLampOnReq : 30|2@1+ (1,0) [0|3] "" XXX
 SG_ Lamp_MoodLampOnReq : 32|3@1+ (1,0) [0|7] "" XXX
 SG_ ICU_PowerAutoCutModSta : 35|2@1+ (1,0) [0|3] "" XXX
 SG_ ICU_SoCBattStaMsgReq : 37|9@1+ (1,0) [0|511] "" XXX
 SG_ Brake_SwSta_ICU : 46|2@1+ (1,0) [0|3] "" XXX

BO_ 1050 BCM_07_200ms: 8 XXX
 SG_ BCM_Crc7Val : 0|12@1+ (1,0) [0|4095] "" XXX
 SG_ BCM_AlvCnt7Val : 12|4@1+ (1,0) [0|15] "" XXX
 SG_ Lamp_HiPrioHzrdReq : 16|3@1+ (1,0) [0|7] "" XXX
 SG_ Lamp_LoPrioHzrdReq : 19|17@1+ (1,0) [0|131071] "" XXX
 SG_ Lamp_IntTailLmpOnReq : 36|2@1+ (1,0) [0|3] "" XXX
 SG_ Lamp_ExtrnlTailLmpOnReq : 38|2@1+ (1,0) [0|3] "" XXX
 SG_ Lamp_HdLmpLoOnReq : 40|2@1+ (1,0) [0|3] "" XXX
 SG_ Lamp_HdLmpHiOnReq : 42|4@1+ (1,0) [0|15] "" XXX
 SG_ Lamp_AvTailLmpSta : 46|2@1+ (1,0) [0|3] "" XXX

BO_ 1051 BCM_08_200ms: 8 XXX
 SG_ BCM_Crc8Val : 0|12@1+ (1,0) [0|4095] "" XXX
 SG_ BCM_AlvCnt8Val : 12|4@1+ (1,0) [0|15] "" XXX
 SG_ Lamp_HbaCtrlModTyp : 16|2@1+ (1,0) [0|3] "" XXX
 SG_ Lamp_IFSCtrlModTyp : 18|4@1+ (1,0) [0|15] "" XXX
 SG_ Lamp_RrFogLmpOnReq : 22|12@1+ (1,0) [0|4095] "" XXX
 SG_ Lamp_HdLmpWlcmCmd : 34|6@1+ (1,0) [0|63] "" XXX
 SG_ Lamp_PuddleLmpOnReq : 40|8@1+ (1,0) [0|255] "" XXX

BO_ 1052 BCM_09_200ms: 8 XXX
 SG_ BCM_Crc9Val : 0|12@1+ (1,0) [0|4095] "" XXX
 SG_ BCM_AlvCnt9Val : 12|7@1+ (1,0) [0|127] "" XXX
 SG_ Lamp_AutoLtSnsrNightSta : 19|2@1+ (1,0) [0|3] "" XXX
 SG_ Lamp_VendorInfo : 21|3@1+ (1,0) [0|7] "" XXX
 SG_ Lamp_AutoLtSnsrHorVal : 24|10@1+ (1,0) [0|1023] "" XXX
 SG_ IBU_HDPSpprtSWVer : 34|16@1+ (1,0) [0|65535] "" XXX
 SG_ IBU_HDPSpprtRdy : 50|6@1+ (1,0) [0|63] "" XXX
 SG_ Wiper_RainAmount : 56|8@1+ (1,0) [0|255] "" XXX

BO_ 1053 HU_DATC_E: 8 XXX
 SG_ DATC_AfterBlowUSMSet : 0|2@1+ (1,0) [0|3] "" XXX
 SG_ HU_DATC_PasModeSet : 2|4@1+ (1,0) [0|15] "" XXX
 SG_ DATC_SchdldVntUSMSet : 6|2@1+ (1,0) [0|3] "" XXX
 SG_ DATC_SchdldVntHrSet : 8|5@1+ (1,0) [0|31] "" XXX
 SG_ DATC_SchdldVntMinSet : 13|3@1+ (1,0) [0|7] "" XXX
 SG_ HU_DATC_WshFldUSMSet : 16|4@1+ (1,0) [0|15] "" XXX
 SG_ CF_DATC_HptFdbckLvl : 20|4@1+ (1,0) [0|15] "" XXX
 SG_ HU_DATC_PassAutoSet : 24|2@1+ (1,0) [0|3] "" XXX
 SG_ HU_DATC_PassBlower : 26|4@1+ (1,0) [0|15] "" XXX
 SG_ HU_DATC_PassBlowerUpDn : 30|2@1+ (1,0) [0|3] "" XXX
 SG_ HU_DATC_DrvOnlySet : 32|2@1+ (1,0) [0|3] "" XXX
 SG_ HU_DATC_HeatSet : 34|5@1+ (1,0) [0|31] "" XXX
 SG_ HU_DATC_FrPsMultiAutoBlower : 39|3@1+ (1,0) [0|7] "" XXX
 SG_ HU_DATC_RrDrMultiAutoBlower : 42|3@1+ (1,0) [0|7] "" XXX
 SG_ HU_DATC_FragranceStrhSet : 45|3@1+ (1,0) [0|7] "" XXX
 SG_ HU_DATC_FragranceKindSet : 48|5@1+ (1,0) [0|31] "" XXX
 SG_ HU_DATC_FrDrMultiAutoBlower : 53|3@1+ (1,0) [0|7] "" XXX

BO_ 1055 HU_AVM_PE: 8 XXX
 SG_ HU_SVM_tch_mpt_valid__ccp_pan : 8|8@1+ (1,0) [0|255] "" XXX
 SG_ HU_SVM_ccp_pan_valid : 9|1@1+ (1,0) [0|1] "" XXX
 SG_ SVM_CaptureModeCMD : 10|46@1+ (1,0) [0|70368744177663] "" XXX
 SG_ HU_SVM_ccp_pan : 56|8@1+ (1,0) [0|255] "" XXX

BO_ 1057 ILCU_LH_01_200ms: 8 XXX
 SG_ ILCU_LH_Crc1Val : 0|12@1+ (1,0) [0|4095] "" XXX
 SG_ ILCU_LH_AlvCnt1Val : 12|4@1+ (1,0) [0|15] "" XXX
 SG_ ILCULH_LowBeamAct_Sta : 16|2@1+ (1,0) [0|3] "" XXX
 SG_ ILCULH_LowBeamLED_Sta : 18|2@1+ (1,0) [0|3] "" XXX
 SG_ ILCULH_PstnAct_Sta : 20|2@1+ (1,0) [0|3] "" XXX
 SG_ ILCULH_PstnLED_Sta : 22|2@1+ (1,0) [0|3] "" XXX
 SG_ ILCULH_HighBeamAct_Sta : 24|2@1+ (1,0) [0|3] "" XXX
 SG_ ILCULH_HighBeamLED_Sta : 26|2@1+ (1,0) [0|3] "" XXX
 SG_ ILCULH_DRLAct_Sta : 28|2@1+ (1,0) [0|3] "" XXX
 SG_ ILCULH_DRLLED_Sta : 30|2@1+ (1,0) [0|3] "" XXX
 SG_ ILCULH_FrontTurnAct_Sta : 32|2@1+ (1,0) [0|3] "" XXX
 SG_ ILCULH_FrontTurnLED_Sta : 34|6@1+ (1,0) [0|63] "" XXX
 SG_ ILCULH_System_Sta : 40|2@1+ (1,0) [0|3] "" XXX
 SG_ ILCU_LH_TrfChgSta : 42|2@1+ (1,0) [0|3] "" XXX
 SG_ ILCULH_IFSActVehSpd : 44|4@1+ (1,0) [0|15] "" XXX
 SG_ ILCULH_IFSOpt_Sta : 48|2@1+ (1,0) [0|3] "" XXX
 SG_ ILCULH_IFSLamp_Act : 50|2@1+ (1,0) [0|3] "" XXX
 SG_ ILCULH_IFSSysState_Sta : 52|2@1+ (1,0) [0|3] "" XXX
 SG_ ILCULH_IFSWarning_Sta : 54|2@1+ (1,0) [0|3] "" XXX
 SG_ ILCULH_DWLRValueSet : 56|8@1+ (1,0) [0|255] "" XXX

BO_ 1058 BCM_10_200ms: 8 XXX
 SG_ BCM_Crc10Val : 0|8@1+ (1,0) [0|255] "" XXX
 SG_ Wiper_RainSnsrPartNum : 8|4@1+ (1,0) [0|15] "" XXX
 SG_ BCM_AlvCnt10Val : 12|4@1+ (1,0) [0|15] "" XXX
 SG_ Wiper_PrkngPosSta : 16|4@1+ (1,0) [0|15] "" XXX
 SG_ Wiper_RainSnsrOptionTyp : 20|2@1+ (1,0) [0|3] "" XXX
 SG_ Wiper_RainSnsrSta : 22|28@1+ (1,0) [0|268435455] "" XXX
 SG_ BCM_GearPosPSta : 50|2@1+ (1,0) [0|3] "" XXX
 SG_ BCM_SunRoofOpnSta : 52|4@1+ (1,0) [0|15] "" XXX
 SG_ SunRoof_RrBlindErrSta : 56|8@1+ (1,0) [0|255] "" XXX

BO_ 1062 ILCU_RH_01_200ms: 8 XXX
 SG_ ILCU_RH_Crc1Val : 0|12@1+ (1,0) [0|4095] "" XXX
 SG_ ILCU_RH_AlvCnt1Val : 12|4@1+ (1,0) [0|15] "" XXX
 SG_ ILCURH_LowBeamAct_Sta : 16|2@1+ (1,0) [0|3] "" XXX
 SG_ ILCURH_LowBeamLED_Sta : 18|2@1+ (1,0) [0|3] "" XXX
 SG_ ILCURH_PstnAct_Sta : 20|2@1+ (1,0) [0|3] "" XXX
 SG_ ILCURH_PstnLED_Sta : 22|2@1+ (1,0) [0|3] "" XXX
 SG_ ILCURH_HighBeamAct_Sta : 24|2@1+ (1,0) [0|3] "" XXX
 SG_ ILCURH_HighBeamLED_Sta : 26|2@1+ (1,0) [0|3] "" XXX
 SG_ ILCURH_DRLAct_Sta : 28|2@1+ (1,0) [0|3] "" XXX
 SG_ ILCURH_DRLLED_Sta : 30|2@1+ (1,0) [0|3] "" XXX
 SG_ ILCURH_FrontTurnAct_Sta : 32|2@1+ (1,0) [0|3] "" XXX
 SG_ ILCURH_FrontTurnLED_Sta : 34|6@1+ (1,0) [0|63] "" XXX
 SG_ ILCURH_System_Sta : 40|2@1+ (1,0) [0|3] "" XXX
 SG_ ILCU_RH_TrfChgSta : 42|2@1+ (1,0) [0|3] "" XXX
 SG_ ILCURH_IFSActVehSpd : 44|4@1+ (1,0) [0|15] "" XXX
 SG_ ILCURH_IFSOpt_Sta : 48|2@1+ (1,0) [0|3] "" XXX
 SG_ ILCURH_IFSLamp_Act : 50|2@1+ (1,0) [0|3] "" XXX
 SG_ ILCURH_IFSSysState_Sta : 52|2@1+ (1,0) [0|3] "" XXX
 SG_ ILCURH_IFSWarning_Sta : 54|2@1+ (1,0) [0|3] "" XXX
 SG_ ILCURH_DWLRValueSet : 56|8@1+ (1,0) [0|255] "" XXX

BO_ 1063 DATC_11_200ms: 8 XXX
 SG_ DATC_Crc11Val : 0|16@1+ (1,0) [0|65535] "" XXX
 SG_ DATC_AlvCnt11Val : 16|12@1+ (1,0) [0|4095] "" XXX
 SG_ DATC_TunnelFuncOff4AutoDfgReq : 28|4@1+ (1,0) [0|15] "" XXX
 SG_ DATC_RrCtlLckSta : 32|2@1+ (1,0) [0|3] "" XXX
 SG_ DATC_DrvrStHtrUSMSta : 34|4@1+ (1,0) [0|15] "" XXX
 SG_ DATC_WshFldUSMSta : 38|2@1+ (1,0) [0|3] "" XXX
 SG_ DATC_DfgLgcUSMSta : 40|2@1+ (1,0) [0|3] "" XXX
 SG_ DATC_AutoFrshUSMSta : 42|2@1+ (1,0) [0|3] "" XXX
 SG_ DATC_HptIntnstySta : 44|4@1+ (1,0) [0|15] "" XXX

BO_ 1065 DATC_12_200ms: 8 XXX
 SG_ DATC_Crc12Val : 0|16@1+ (1,0) [0|65535] "" XXX
 SG_ DATC_AlvCnt12Val : 16|8@1+ (1,0) [0|255] "" XXX
 SG_ DATC_StrWhlHtrSwReq : 24|6@1+ (1,0) [0|63] "" XXX
 SG_ DATC_RrDefSw : 30|2@1+ (1,0) [0|3] "" XXX
 SG_ DATC_FLStOpReq : 32|4@1+ (1,0) [0|15] "" XXX
 SG_ DATC_FRStOpReq : 36|12@1+ (1,0) [0|4095] "" XXX
 SG_ DATC_RRStHtrSwReq : 48|2@1+ (1,0) [0|3] "" XXX
 SG_ DATC_RRStVentSwReq : 50|2@1+ (1,0) [0|3] "" XXX
 SG_ DATC_RLStHtrSwReq : 52|2@1+ (1,0) [0|3] "" XXX
 SG_ DATC_RLStVentSwReq : 54|6@1+ (1,0) [0|63] "" XXX
 SG_ DATC_WdwClsReq : 60|2@1+ (1,0) [0|3] "" XXX
 SG_ DATC_RRSyncDis : 62|2@1+ (1,0) [0|3] "" XXX

BO_ 1066 DATC_13_200ms: 8 XXX
 SG_ DATC_Crc13Val : 0|16@1+ (1,0) [0|65535] "" XXX
 SG_ DATC_AlvCnt13Val : 16|8@1+ (1,0) [0|255] "" XXX
 SG_ DATC_MltAutoBlrTxt : 24|3@1+ (1,0) [0|7] "" XXX
 SG_ DATC_MltAutoBlrTxt_Ps : 27|3@1+ (1,0) [0|7] "" XXX
 SG_ DATC_MltAutoBlrTxt_Rr : 30|8@1+ (1,0) [0|255] "" XXX
 SG_ DATC_RLStTmblrSwReq : 38|2@1+ (1,0) [0|3] "" XXX
 SG_ DATC_RRStTmblrSwReq : 40|4@1+ (1,0) [0|15] "" XXX
 SG_ DATC_Opt5Typ : 44|4@1+ (1,0) [0|15] "" XXX

BO_ 1067 FR_CMR_02_100ms_1_ISLW: 8 XXX
 SG_ HWSW_SysSta : 0|8@1+ (1,0) [0|255] "" XXX

BO_ 1070 RL_SHVU_02_200ms: 8 XXX
 SG_ PSM_RrRtSldStrtSta : 11|9@1+ (1,0) [0|511] "" XXX
 SG_ RL_SHVU_HtSwHiIndSta : 12|2@1+ (1,0) [0|3] "" XXX
 SG_ RL_SHVU_HtSwMidIndSta : 14|2@1+ (1,0) [0|3] "" XXX
 SG_ RL_SHVU_HtSwLowIndSta : 16|2@1+ (1,0) [0|3] "" XXX
 SG_ RL_SHVU_VntSwHiIndSta : 18|2@1+ (1,0) [0|3] "" XXX
 SG_ RRPSM_APSMBzrOnReq : 20|4@1+ (1,0) [0|15] "" XXX
 SG_ RL_SHVU_VntSwLowIndSta : 22|4@1+ (1,0) [0|15] "" XXX
 SG_ RRPSM_SeatTyp : 24|3@1+ (1,0) [0|7] "" XXX
 SG_ RL_SHVU_HtBlcUsmSta : 26|6@1+ (1,0) [0|63] "" XXX
 SG_ RRPSM_RRStEsyAcsUSMSta : 27|5@1+ (1,0) [0|31] "" XXX
 SG_ RRPSM_RRSlidePosition : 32|16@1+ (1,0) [0|65535] "" XXX
 SG_ RRPSM_RearModeState : 48|8@1+ (1,0) [0|255] "" XXX
 SG_ RRPSM_RRLegRestPosition : 56|8@1+ (1,0) [0|255] "" XXX

BO_ 1071 RR_SHVU_02_200ms: 8 XXX
 SG_ RR_SHVU_HtSwHiIndSta : 12|2@1+ (1,0) [0|3] "" XXX
 SG_ RR_SHVU_HtSwMidIndSta : 14|2@1+ (1,0) [0|3] "" XXX
 SG_ RR_SHVU_HtSwLowIndSta : 16|2@1+ (1,0) [0|3] "" XXX
 SG_ RR_SHVU_VntSwHiIndSta : 18|2@1+ (1,0) [0|3] "" XXX
 SG_ RR_SHVU_VntSwMidIndSta : 20|2@1+ (1,0) [0|3] "" XXX
 SG_ RR_SHVU_VntSwLowIndSta : 22|2@1+ (1,0) [0|3] "" XXX
 SG_ RR_SHVU_HtBlcUsmSta : 24|8@1+ (1,0) [0|255] "" XXX

BO_ 1072 IAU_18_200ms: 8 XXX
 SG_ IAU_DigitalKeyProfileRval : 48|4@1+ (1,0) [0|15] "" XXX
 SG_ IAU_SharedPhnRegStat : 52|2@1+ (1,0) [0|3] "" XXX
 SG_ IAU_CardKeyEnblRVal : 54|2@1+ (1,0) [0|3] "" XXX
 SG_ IAU_DrvDHLPhnDetect : 56|2@1+ (1,0) [0|3] "" XXX
 SG_ IAU_AstDHLPhnDetect : 58|2@1+ (1,0) [0|3] "" XXX
 SG_ IAU_RLDHLPhnDetect : 60|2@1+ (1,0) [0|3] "" XXX
 SG_ IAU_RRDHLPhnDetect : 62|2@1+ (1,0) [0|3] "" XXX

BO_ 1073 RWPC_01_200ms: 8 XXX
 SG_ USM_ValCmdSta : 0|2@1+ (1,0) [0|3] "" XXX
 SG_ WPC_PhnLftWrngRWPCSta : 2|3@1+ (1,0) [0|7] "" XXX
 SG_ USM_ValCmdStaforATS : 5|3@1+ (1,0) [0|7] "" XXX
 SG_ RWPC_SWVerMajor1 : 8|8@1+ (1,0) [0|255] "" XXX
 SG_ RWS_AlvCnt1Val : 16|8@1+ (1,0) [0|255] "" XXX
 SG_ RWS_Sta : 24|8@1+ (1,0) [0|255] "" XXX
 SG_ RWS_FdFwdStrokeCmdVal : 32|16@1+ (1,0) [0|65535] "" XXX
 SG_ RWS_MsdStrokeVal : 48|16@1+ (1,0) [0|65535] "" XXX
 SG_ RWS_WrngLmpSta : 64|3@1+ (1,0) [0|7] "" XXX
 SG_ RWS_ModSta : 67|4@1+ (1,0) [0|15] "" XXX
 SG_ RWS_IcscErr : 71|2@1+ (1,0) [0|3] "" XXX
 SG_ RWS_MotCrnt : 73|16@1+ (1,0) [0|65535] "" XXX
 SG_ RWS_Chain_Flag : 89|7@1+ (1,0) [0|127] "" XXX
 SG_ RWS_LPSStrokeVal : 96|8@1+ (1,0) [0|255] "" XXX
 SG_ RSPA_Sta : 120|8@1+ (1,0) [0|255] "" XXX

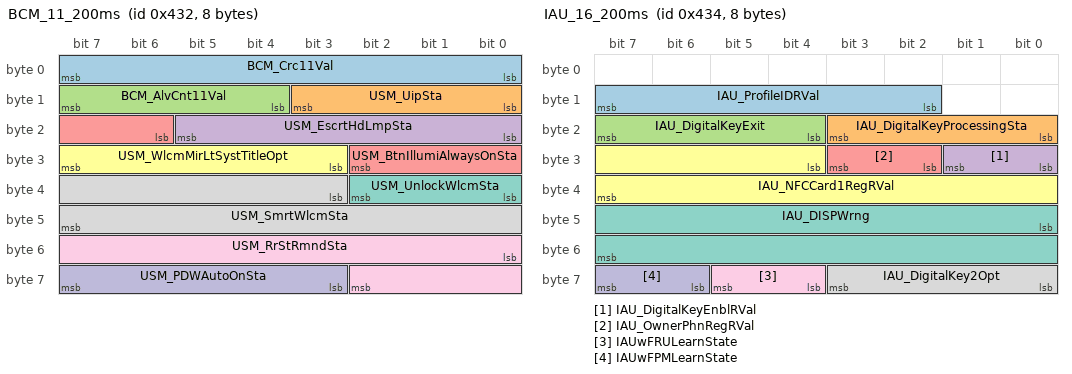
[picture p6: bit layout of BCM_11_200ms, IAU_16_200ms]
BO_ 1074 BCM_11_200ms: 8 XXX
 SG_ BCM_Crc11Val : 0|8@1+ (1,0) [0|255] "" XXX
 SG_ USM_UipSta : 8|4@1+ (1,0) [0|15] "" XXX
 SG_ BCM_AlvCnt11Val : 12|4@1+ (1,0) [0|15] "" XXX
 SG_ USM_EscrtHdLmpSta : 16|6@1+ (1,0) [0|63] "" XXX
 SG_ USM_BtnIllumiAlwaysOnSta : 22|5@1+ (1,0) [0|31] "" XXX
 SG_ USM_WlcmMirLtSystTitleOpt : 27|5@1+ (1,0) [0|31] "" XXX
 SG_ USM_UnlockWlcmSta : 32|3@1+ (1,0) [0|7] "" XXX
 SG_ USM_SmrtWlcmSta : 35|13@1+ (1,0) [0|8191] "" XXX
 SG_ USM_RrStRmndSta : 48|11@1+ (1,0) [0|2047] "" XXX
 SG_ USM_PDWAutoOnSta : 59|5@1+ (1,0) [0|31] "" XXX

BO_ 1076 IAU_16_200ms: 8 XXX
 SG_ IAU_ProfileIDRVal : 10|6@1+ (1,0) [0|63] "" XXX
 SG_ IAU_DigitalKeyProcessingSta : 16|4@1+ (1,0) [0|15] "" XXX
 SG_ IAU_DigitalKeyExit : 20|4@1+ (1,0) [0|15] "" XXX
 SG_ IAU_DigitalKeyEnblRVal : 24|2@1+ (1,0) [0|3] "" XXX
 SG_ IAU_OwnerPhnRegRVal : 26|2@1+ (1,0) [0|3] "" XXX
 SG_ IAU_NFCCard1RegRVal : 28|12@1+ (1,0) [0|4095] "" XXX
 SG_ IAU_DISPWrng : 40|16@1+ (1,0) [0|65535] "" XXX
 SG_ IAU_DigitalKey2Opt : 56|4@1+ (1,0) [0|15] "" XXX
 SG_ IAUwFRULearnState : 60|2@1+ (1,0) [0|3] "" XXX
 SG_ IAUwFPMLearnState : 62|2@1+ (1,0) [0|3] "" XXX

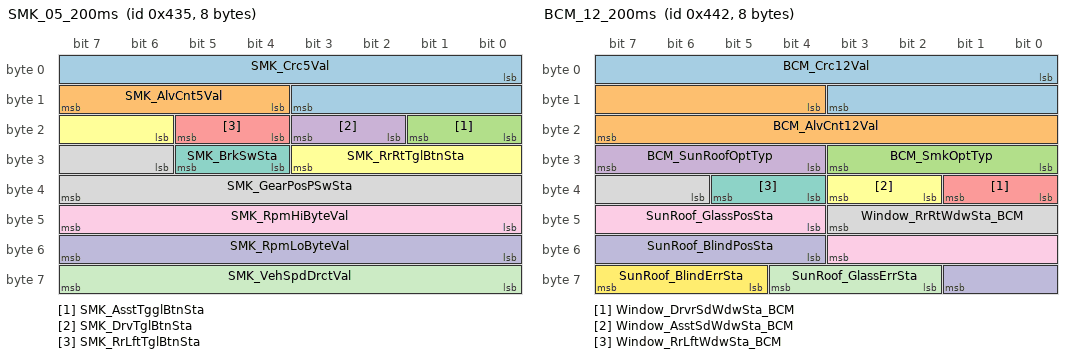
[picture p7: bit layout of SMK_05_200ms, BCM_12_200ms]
BO_ 1077 SMK_05_200ms: 8 XXX
 SG_ SMK_Crc5Val : 0|12@1+ (1,0) [0|4095] "" XXX
 SG_ SMK_AlvCnt5Val : 12|4@1+ (1,0) [0|15] "" XXX
 SG_ SMK_AsstTgglBtnSta : 16|2@1+ (1,0) [0|3] "" XXX
 SG_ SMK_DrvTglBtnSta : 18|2@1+ (1,0) [0|3] "" XXX
 SG_ SMK_RrLftTglBtnSta : 20|2@1+ (1,0) [0|3] "" XXX
 SG_ SMK_RrRtTglBtnSta : 22|6@1+ (1,0) [0|63] "" XXX
 SG_ SMK_BrkSwSta : 28|2@1+ (1,0) [0|3] "" XXX
 SG_ SMK_GearPosPSwSta : 30|10@1+ (1,0) [0|1023] "" XXX
 SG_ SMK_RpmHiByteVal : 40|8@1+ (1,0) [0|255] "" XXX
 SG_ SMK_RpmLoByteVal : 48|8@1+ (1,0) [0|255] "" XXX
 SG_ SMK_VehSpdDrctVal : 56|8@1+ (1,0) [0|255] "" XXX

BO_ 1080 RL_SHVU_01_200ms: 8 XXX
 SG_ RL_SHVU_SeatOptSta : 0|3@1+ (1,0) [0|7] "" XXX
 SG_ RL_SHVU_SeatHtOperSta : 3|43@1+ (1,0) [0|8796093022207] "" XXX
 SG_ RL_SHVU_HtSwHiIndSta_RHD : 46|2@1+ (1,0) [0|3] "" XXX
 SG_ RL_SHVU_HtSwMidIndSta_RHD : 48|2@1+ (1,0) [0|3] "" XXX
 SG_ RL_SHVU_HtSwLowIndSta_RHD : 50|2@1+ (1,0) [0|3] "" XXX
 SG_ RL_SHVU_VntSwHiIndSta_RHD : 52|2@1+ (1,0) [0|3] "" XXX
 SG_ RL_SHVU_VntSwMidIndSta_RHD : 54|2@1+ (1,0) [0|3] "" XXX
 SG_ RL_SHVU_VntSwLowIndSta_RHD : 56|8@1+ (1,0) [0|255] "" XXX

BO_ 1084 HU_GW_E_04_LaunchControl_GripLevel: 8 XXX
 SG_ Smt_ToAirSus_Reset : 58|6@1+ (1,0) [0|63] "" XXX

BO_ 1085 DLBCU_04_200ms: 8 XXX
 SG_ DLBCU_ActiveDis : 0|3@1+ (1,0) [0|7] "" XXX
 SG_ DLBCU_DrvModUSMSta : 3|2@1+ (1,0) [0|3] "" XXX
 SG_ DLBCU_ActiveStrSta : 5|2@1+ (1,0) [0|3] "" XXX
 SG_ DLBCU_ActiveTimeSta : 7|3@1+ (1,0) [0|7] "" XXX
 SG_ DLBCU_CushSoftSta : 10|3@1+ (1,0) [0|7] "" XXX
 SG_ DLBCU_CellOpt : 13|3@1+ (1,0) [0|7] "" XXX
 SG_ DLBCU_BodySpprtSta : 16|4@1+ (1,0) [0|15] "" XXX
 SG_ DLBCU_BodySpprtDis : 20|4@1+ (1,0) [0|15] "" XXX

BO_ 1086 RDC_01_200ms: 8 XXX
 SG_ RL_CURTAIN_POSITION : 0|3@1+ (1,0) [0|7] "" XXX
 SG_ RR_CURTAIN_POSITION : 3|3@1+ (1,0) [0|7] "" XXX
 SG_ RDC_OptTyp : 6|2@1+ (1,0) [0|3] "" XXX
 SG_ RDC_SWVerMajor1 : 8|8@1+ (1,0) [0|255] "" XXX
 SG_ RDC_SWVerMinor1 : 16|8@1+ (1,0) [0|255] "" XXX
 SG_ RDC_SWVerMinor2 : 24|8@1+ (1,0) [0|255] "" XXX

BO_ 1088 IAU_19_200ms: 8 XXX
 SG_ IAU_ValetDigitalkey : 0|16@1+ (1,0) [0|65535] "" XXX
 SG_ IAU_StartIdentifiedProfile : 16|8@1+ (1,0) [0|255] "" XXX
 SG_ IAU_NFCCard1SN : 24|8@1+ (1,0) [0|255] "" XXX

BO_ 1089 RLPSM_01_200ms_RLPSM: 8 XXX
 SG_ RRPSM_LimSetSta : 22|2@1+ (1,0) [0|3] "" XXX

BO_ 1090 BCM_12_200ms: 8 XXX
 SG_ BCM_Crc12Val : 0|12@1+ (1,0) [0|4095] "" XXX
 SG_ BCM_AlvCnt12Val : 12|12@1+ (1,0) [0|4095] "" XXX
 SG_ BCM_SmkOptTyp : 24|4@1+ (1,0) [0|15] "" XXX
 SG_ BCM_SunRoofOptTyp : 28|4@1+ (1,0) [0|15] "" XXX
 SG_ Window_DrvrSdWdwSta_BCM : 32|2@1+ (1,0) [0|3] "" XXX
 SG_ Window_AsstSdWdwSta_BCM : 34|2@1+ (1,0) [0|3] "" XXX
 SG_ Window_RrLftWdwSta_BCM : 36|2@1+ (1,0) [0|3] "" XXX
 SG_ Window_RrRtWdwSta_BCM : 38|6@1+ (1,0) [0|63] "" XXX
 SG_ SunRoof_GlassPosSta : 44|8@1+ (1,0) [0|255] "" XXX
 SG_ SunRoof_BlindPosSta : 52|6@1+ (1,0) [0|63] "" XXX
 SG_ SunRoof_GlassErrSta : 58|3@1+ (1,0) [0|7] "" XXX
 SG_ SunRoof_BlindErrSta : 61|3@1+ (1,0) [0|7] "" XXX

BO_ 1092 SMK_02_200ms: 8 XXX
 SG_ SMK_Crc2Val : 0|12@1+ (1,0) [0|4095] "" XXX
 SG_ SMK_AlvCnt2Val : 12|4@1+ (1,0) [0|15] "" XXX
 SG_ SSB_StrtStpBtnSw1Sta : 16|2@1+ (1,0) [0|3] "" XXX
 SG_ SSB_StrtStpBtnSw2Sta : 18|11@1+ (1,0) [0|2047] "" XXX
 SG_ ENG_PwrAutoOffInfo : 24|8@1+ (1,0) [0|255] "" XXX
 SG_ SMK_AuthSta : 29|3@1+ (1,0) [0|7] "" XXX
 SG_ SMK_Ign1InSta : 32|2@1+ (1,0) [0|3] "" XXX
 SG_ SMK_Ign1RlySta : 34|2@1+ (1,0) [0|3] "" XXX
 SG_ SMK_Ign2InSta : 36|2@1+ (1,0) [0|3] "" XXX
 SG_ SMK_Ign2RlySta : 38|2@1+ (1,0) [0|3] "" XXX
 SG_ SMK_StrtFdbckSta : 40|2@1+ (1,0) [0|3] "" XXX
 SG_ SMK_StrtrRlyOutSta : 42|2@1+ (1,0) [0|3] "" XXX
 SG_ SMK_AccInSta : 44|2@1+ (1,0) [0|3] "" XXX
 SG_ SMK_AccRlySta : 46|2@1+ (1,0) [0|3] "" XXX
 SG_ SMK_CLUAccIndOnReq : 48|8@1+ (1,0) [0|255] "" XXX
 SG_ SMK_TlEngRunSta : 56|2@1+ (1,0) [0|3] "" XXX
 SG_ SMK_TlCrnkModSta : 58|2@1+ (1,0) [0|3] "" XXX
 SG_ SMK_RmtKeyEngRunSta : 60|2@1+ (1,0) [0|3] "" XXX
 SG_ SMK_RmtKeyCrnkModSta : 62|2@1+ (1,0) [0|3] "" XXX

BO_ 1093 SMK_06_200ms: 8 XXX
 SG_ SMK_Crc6Val : 0|12@1+ (1,0) [0|4095] "" XXX
 SG_ SMK_AlvCnt6Val : 12|4@1+ (1,0) [0|15] "" XXX
 SG_ Lamp_HzrdBlnkngSta : 16|3@1+ (1,0) [0|7] "" XXX
 SG_ RSPA_LearntSta : 19|2@1+ (1,0) [0|3] "" XXX
 SG_ Lamp_SmrtWlcmLtOnReq : 21|3@1+ (1,0) [0|7] "" XXX
 SG_ Fob_BattStaInfo : 24|2@1+ (1,0) [0|3] "" XXX
 SG_ Fob_FoundDrvWlcmArea : 26|2@1+ (1,0) [0|3] "" XXX
 SG_ Fob_FoundAsstWlcmArea : 28|2@1+ (1,0) [0|3] "" XXX
 SG_ Fob_FoundExtrnlArea : 30|2@1+ (1,0) [0|3] "" XXX
 SG_ Fob_FoundIntArea : 32|2@1+ (1,0) [0|3] "" XXX
 SG_ Fob_LearntSta : 34|2@1+ (1,0) [0|3] "" XXX
 SG_ RSPA_RFSigErrSta : 36|2@1+ (1,0) [0|3] "" XXX
 SG_ RSPA_CanErrSta : 38|2@1+ (1,0) [0|3] "" XXX
 SG_ LFAnt_FltSta : 40|2@1+ (1,0) [0|3] "" XXX
 SG_ LFAnt_SrchSta : 42|6@1+ (1,0) [0|63] "" XXX
 SG_ RSPA_ModSta_SMK : 48|3@1+ (1,0) [0|7] "" XXX
 SG_ RSPA_FobBattSta : 51|3@1+ (1,0) [0|7] "" XXX
 SG_ Fob_BtnReleasedSta : 54|2@1+ (1,0) [0|3] "" XXX
 SG_ USM_SmrtTrnkTlgtModSta : 56|3@1+ (1,0) [0|7] "" XXX
 SG_ USM_WALModSta : 59|3@1+ (1,0) [0|7] "" XXX
 SG_ Fob_FoundWlcmArea : 62|2@1+ (1,0) [0|3] "" XXX

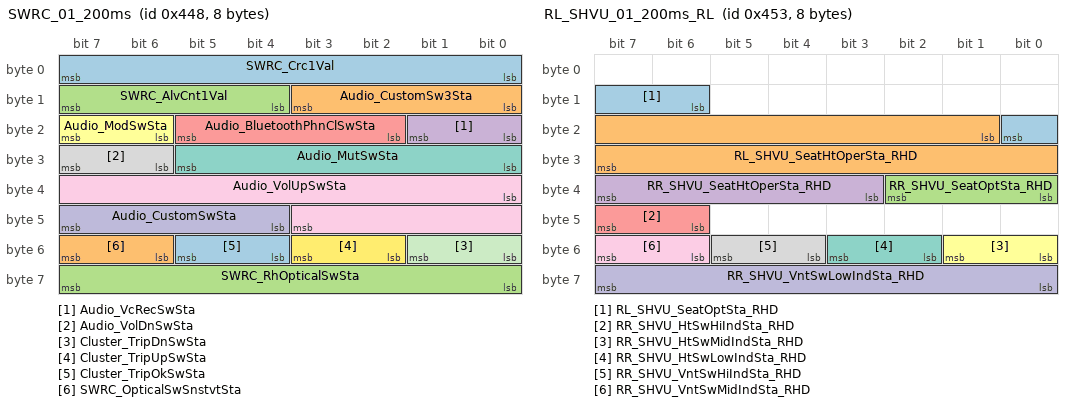
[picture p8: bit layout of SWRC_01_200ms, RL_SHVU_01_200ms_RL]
BO_ 1096 SWRC_01_200ms: 8 XXX
 SG_ SWRC_Crc1Val : 0|8@1+ (1,0) [0|255] "" XXX
 SG_ Audio_CustomSw3Sta : 8|4@1+ (1,0) [0|15] "" XXX
 SG_ SWRC_AlvCnt1Val : 12|4@1+ (1,0) [0|15] "" XXX
 SG_ Audio_VcRecSwSta : 16|2@1+ (1,0) [0|3] "" XXX
 SG_ Audio_BluetoothPhnClSwSta : 18|4@1+ (1,0) [0|15] "" XXX
 SG_ Audio_ModSwSta : 22|2@1+ (1,0) [0|3] "" XXX
 SG_ Audio_MutSwSta : 24|6@1+ (1,0) [0|63] "" XXX
 SG_ Audio_VolDnSwSta : 30|2@1+ (1,0) [0|3] "" XXX
 SG_ Audio_VolUpSwSta : 32|12@1+ (1,0) [0|4095] "" XXX
 SG_ Audio_CustomSwSta : 44|4@1+ (1,0) [0|15] "" XXX
 SG_ Cluster_TripDnSwSta : 48|2@1+ (1,0) [0|3] "" XXX
 SG_ Cluster_TripUpSwSta : 50|2@1+ (1,0) [0|3] "" XXX
 SG_ Cluster_TripOkSwSta : 52|2@1+ (1,0) [0|3] "" XXX
 SG_ SWRC_OpticalSwSnstvtSta : 54|2@1+ (1,0) [0|3] "" XXX
 SG_ SWRC_RhOpticalSwSta : 56|8@1+ (1,0) [0|255] "" XXX

BO_ 1099 WPC_01_200ms: 8 XXX
 SG_ USM_CmdWPCSta : 0|2@1+ (1,0) [0|3] "" XXX
 SG_ WPC_PhnLftWrngSta : 2|14@1+ (1,0) [0|16383] "" XXX
 SG_ WPC_SWVerMajor1 : 16|8@1+ (1,0) [0|255] "" XXX
 SG_ WPC_SWVerMinor1 : 24|8@1+ (1,0) [0|255] "" XXX
 SG_ WPC_SWVerMinor2 : 32|8@1+ (1,0) [0|255] "" XXX

BO_ 1107 RL_SHVU_01_200ms_RL: 8 XXX
 SG_ RL_SHVU_SeatOptSta_RHD : 14|3@1+ (1,0) [0|7] "" XXX
 SG_ RL_SHVU_SeatHtOperSta_RHD : 17|15@1+ (1,0) [0|32767] "" XXX
 SG_ RR_SHVU_SeatOptSta_RHD : 32|3@1+ (1,0) [0|7] "" XXX
 SG_ RR_SHVU_SeatHtOperSta_RHD : 35|5@1+ (1,0) [0|31] "" XXX
 SG_ RR_SHVU_HtSwHiIndSta_RHD : 46|2@1+ (1,0) [0|3] "" XXX
 SG_ RR_SHVU_HtSwMidIndSta_RHD : 48|2@1+ (1,0) [0|3] "" XXX
 SG_ RR_SHVU_HtSwLowIndSta_RHD : 50|2@1+ (1,0) [0|3] "" XXX
 SG_ RR_SHVU_VntSwHiIndSta_RHD : 52|2@1+ (1,0) [0|3] "" XXX
 SG_ RR_SHVU_VntSwMidIndSta_RHD : 54|2@1+ (1,0) [0|3] "" XXX
 SG_ RR_SHVU_VntSwLowIndSta_RHD : 56|8@1+ (1,0) [0|255] "" XXX

BO_ 1109 MLM_01_200ms: 8 XXX
 SG_ MLM_MdLmpBrgtnsVal : 0|5@1+ (1,0) [0|31] "" XXX
 SG_ MLM_MdLmpDrvngVal : 5|3@1+ (1,0) [0|7] "" XXX
 SG_ MLM_MdLmpClrVal : 8|8@1+ (1,0) [0|255] "" XXX
 SG_ MLM_MdLmpRedVal : 16|10@1+ (1,0) [0|1023] "" XXX
 SG_ MLM_MdLmpGreenVal : 26|10@1+ (1,0) [0|1023] "" XXX
 SG_ MLM_MdLmpBlueVal : 36|10@1+ (1,0) [0|1023] "" XXX
 SG_ MLM_MdLmpDrvngModRValue : 46|2@1+ (1,0) [0|3] "" XXX

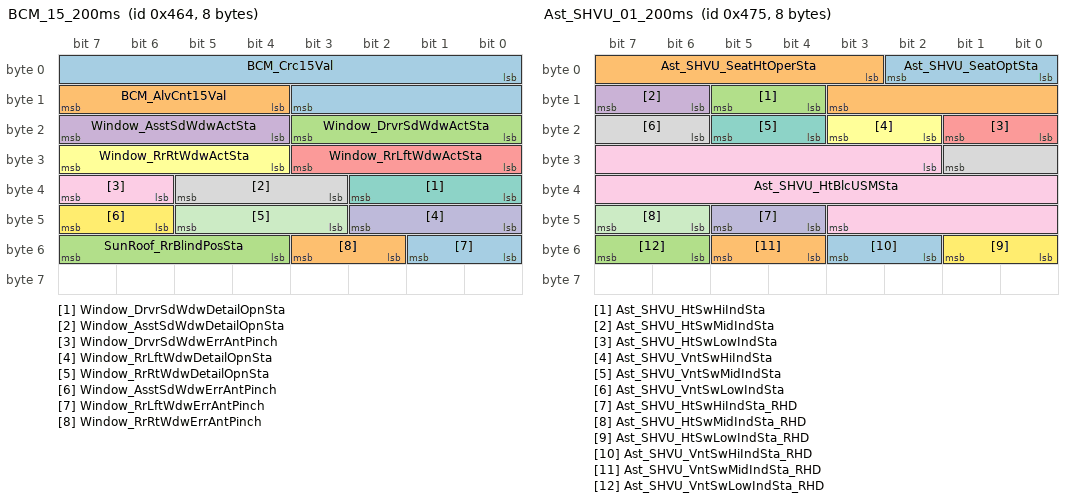
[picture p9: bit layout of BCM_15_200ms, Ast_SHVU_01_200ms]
BO_ 1124 BCM_15_200ms: 8 XXX
 SG_ BCM_Crc15Val : 0|12@1+ (1,0) [0|4095] "" XXX
 SG_ BCM_AlvCnt15Val : 12|4@1+ (1,0) [0|15] "" XXX
 SG_ Window_DrvrSdWdwActSta : 16|4@1+ (1,0) [0|15] "" XXX
 SG_ Window_AsstSdWdwActSta : 20|4@1+ (1,0) [0|15] "" XXX
 SG_ Window_RrLftWdwActSta : 24|4@1+ (1,0) [0|15] "" XXX
 SG_ Window_RrRtWdwActSta : 28|4@1+ (1,0) [0|15] "" XXX
 SG_ Window_DrvrSdWdwDetailOpnSta : 32|3@1+ (1,0) [0|7] "" XXX
 SG_ Window_AsstSdWdwDetailOpnSta : 35|3@1+ (1,0) [0|7] "" XXX
 SG_ Window_DrvrSdWdwErrAntPinch : 38|2@1+ (1,0) [0|3] "" XXX
 SG_ Window_RrLftWdwDetailOpnSta : 40|3@1+ (1,0) [0|7] "" XXX
 SG_ Window_RrRtWdwDetailOpnSta : 43|3@1+ (1,0) [0|7] "" XXX
 SG_ Window_AsstSdWdwErrAntPinch : 46|2@1+ (1,0) [0|3] "" XXX
 SG_ Window_RrLftWdwErrAntPinch : 48|2@1+ (1,0) [0|3] "" XXX
 SG_ Window_RrRtWdwErrAntPinch : 50|2@1+ (1,0) [0|3] "" XXX
 SG_ SunRoof_RrBlindPosSta : 52|4@1+ (1,0) [0|15] "" XXX

BO_ 1125 DATC_14_00ms: 8 XXX
 SG_ DATC_Crc14Val : 0|16@1+ (1,0) [0|65535] "" XXX
 SG_ DATC_AlvCnt14Val : 16|34@1+ (1,0) [0|17179869183] "" XXX
 SG_ DATC_Beep1Sound : 50|6@1+ (1,0) [0|63] "" XXX

BO_ 1129 DPSS_03_200ms: 8 XXX
 SG_ DPSS_Crc3Val : 0|12@1+ (1,0) [0|4095] "" XXX
 SG_ DPSS_AlvCnt3Val : 12|4@1+ (1,0) [0|15] "" XXX
 SG_ DPSS_SldTch : 16|2@1+ (1,0) [0|3] "" XXX
 SG_ DPSS_RclTch : 18|2@1+ (1,0) [0|3] "" XXX
 SG_ DPSS_ExtTch : 20|2@1+ (1,0) [0|3] "" XXX
 SG_ DPSS_LmbrTch : 22|2@1+ (1,0) [0|3] "" XXX
 SG_ DPSS_CushOnOffTch : 24|3@1+ (1,0) [0|7] "" XXX
 SG_ DPSS_HRestTch : 27|5@1+ (1,0) [0|31] "" XXX

BO_ 1130 DLBCU_01_200ms: 8 XXX
 SG_ DLBCU_LumbarUpDis : 0|2@1+ (1,0) [0|3] "" XXX
 SG_ DLBCU_LumbarMidDis : 2|2@1+ (1,0) [0|3] "" XXX
 SG_ DLBCU_LumbarLowDis : 4|2@1+ (1,0) [0|3] "" XXX
 SG_ DLBCU_LumbarDefDis : 6|2@1+ (1,0) [0|3] "" XXX

BO_ 1131 DLBCU_02_200ms: 8 XXX
 SG_ DLBCU_BolsterInfDis : 0|2@1+ (1,0) [0|3] "" XXX
 SG_ DLBCU_BolsterDefDis : 2|6@1+ (1,0) [0|63] "" XXX

BO_ 1132 DLBCU_03_200ms: 8 XXX
 SG_ DLBCU_CushInfDis : 0|2@1+ (1,0) [0|3] "" XXX
 SG_ DLBCU_CushDefDis : 2|6@1+ (1,0) [0|63] "" XXX

BO_ 1133 APSU_02_200ms: 8 XXX
 SG_ APSU_AstStEsyAcsUSMSta : 0|9@1+ (1,0) [0|511] "" XXX
 SG_ APSU_AstRelaxModeSta : 9|3@1+ (1,0) [0|7] "" XXX
 SG_ APSU_AstReturnModeSta : 12|4@1+ (1,0) [0|15] "" XXX

BO_ 1134 APSU_03_200ms: 8 XXX
 SG_ APSU_AstStSldFwdDis : 0|2@1+ (1,0) [0|3] "" XXX
 SG_ APSU_AstStSldBckwdDis : 2|2@1+ (1,0) [0|3] "" XXX
 SG_ APSU_AstStReclneFwdDis : 4|2@1+ (1,0) [0|3] "" XXX
 SG_ APSU_AstStReclneBckwdDis : 6|6@1+ (1,0) [0|63] "" XXX
 SG_ APSU_AstStHghtUpDis : 12|2@1+ (1,0) [0|3] "" XXX
 SG_ APSU_AstStHghtDnDis : 14|6@1+ (1,0) [0|63] "" XXX
 SG_ APSU_AstStRlxTiltUpDis : 20|2@1+ (1,0) [0|3] "" XXX
 SG_ APSU_AstStRlxTiltDnDis : 22|2@1+ (1,0) [0|3] "" XXX

BO_ 1141 Ast_SHVU_01_200ms: 8 XXX
 SG_ Ast_SHVU_SeatOptSta : 0|3@1+ (1,0) [0|7] "" XXX
 SG_ Ast_SHVU_SeatHtOperSta : 3|9@1+ (1,0) [0|511] "" XXX
 SG_ Ast_SHVU_HtSwHiIndSta : 12|2@1+ (1,0) [0|3] "" XXX
 SG_ Ast_SHVU_HtSwMidIndSta : 14|2@1+ (1,0) [0|3] "" XXX
 SG_ Ast_SHVU_HtSwLowIndSta : 16|2@1+ (1,0) [0|3] "" XXX
 SG_ Ast_SHVU_VntSwHiIndSta : 18|2@1+ (1,0) [0|3] "" XXX
 SG_ Ast_SHVU_VntSwMidIndSta : 20|2@1+ (1,0) [0|3] "" XXX
 SG_ Ast_SHVU_VntSwLowIndSta : 22|4@1+ (1,0) [0|15] "" XXX
 SG_ Ast_SHVU_HtBlcUSMSta : 26|18@1+ (1,0) [0|262143] "" XXX
 SG_ Ast_SHVU_HtSwHiIndSta_RHD : 44|2@1+ (1,0) [0|3] "" XXX
 SG_ Ast_SHVU_HtSwMidIndSta_RHD : 46|2@1+ (1,0) [0|3] "" XXX
 SG_ Ast_SHVU_HtSwLowIndSta_RHD : 48|2@1+ (1,0) [0|3] "" XXX
 SG_ Ast_SHVU_VntSwHiIndSta_RHD : 50|2@1+ (1,0) [0|3] "" XXX
 SG_ Ast_SHVU_VntSwMidIndSta_RHD : 52|2@1+ (1,0) [0|3] "" XXX
 SG_ Ast_SHVU_VntSwLowIndSta_RHD : 54|2@1+ (1,0) [0|3] "" XXX

BO_ 1142 SVM_01_600ms: 8 XXX
 SG_ BVM_ViewSta : 0|8@1+ (1,0) [0|255] "" XXX
 SG_ SVM_TopViewInfoA : 8|8@1+ (1,0) [0|255] "" XXX
 SG_ SVM_FrViewBtn_Sta : 16|3@1+ (1,0) [0|7] "" XXX
 SG_ SVM_RrViewBtn_Sta : 19|3@1+ (1,0) [0|7] "" XXX
 SG_ SVM_DRVViewBtn_Sta : 22|2@1+ (1,0) [0|3] "" XXX
 SG_ SVM_TopViewInfoB : 24|8@1+ (1,0) [0|255] "" XXX
 SG_ SVM_TopViewInfoC : 32|8@1+ (1,0) [0|255] "" XXX
 SG_ SVM_TopViewInfoD : 40|8@1+ (1,0) [0|255] "" XXX
 SG_ SVM_ViewSta_New : 48|8@1+ (1,0) [0|255] "" XXX
 SG_ SVM_Typ3 : 56|8@1+ (1,0) [0|255] "" XXX

BO_ 1143 SVM_01_600ms_1_BVM: 8 XXX
 SG_ SVM_ViewSta : 0|8@1+ (1,0) [0|255] "" XXX
 SG_ BVM_OnOffEquipSta : 18|2@1+ (1,0) [0|3] "" XXX
 SG_ BVM_OptSta : 20|4@1+ (1,0) [0|15] "" XXX
 SG_ SVM_TopviewGdLnSta : 24|4@1+ (1,0) [0|15] "" XXX
 SG_ SVM_TopviewDispSta : 28|4@1+ (1,0) [0|15] "" XXX
 SG_ SVM_GdLnSta : 32|4@1+ (1,0) [0|15] "" XXX
 SG_ SVM_Btn_Sta : 36|2@1+ (1,0) [0|3] "" XXX
 SG_ SVM_AutoOnSta : 38|10@1+ (1,0) [0|1023] "" XXX
 SG_ SVM_Ver_Typ : 48|8@1+ (1,0) [0|255] "" XXX

BO_ 1144 DRIVE_MODE: 8 XXX
 SG_ DRIVE_MODE : 0|16@1+ (1,-61611) [0|61611] "" XXX
 SG_ DRIVE_MODE2 : 28|3@1+ (1,0) [1|3] "" XXX

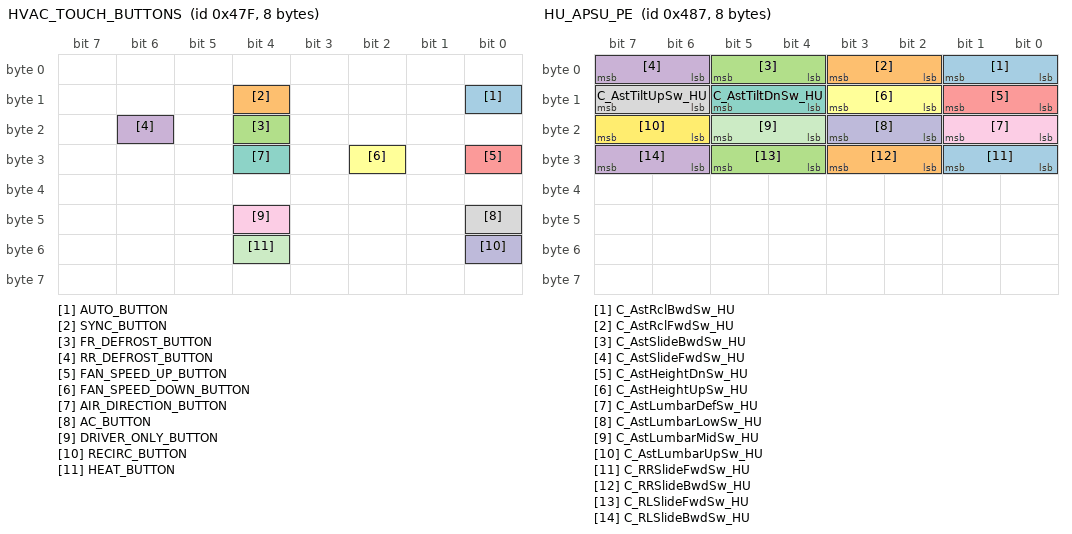
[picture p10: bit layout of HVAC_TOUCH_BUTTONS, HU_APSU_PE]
BO_ 1151 HVAC_TOUCH_BUTTONS: 8 XXX
 SG_ AUTO_BUTTON : 8|1@0+ (1,0) [0|1] "" XXX
 SG_ SYNC_BUTTON : 12|1@0+ (1,0) [0|1] "" XXX
 SG_ FR_DEFROST_BUTTON : 20|1@0+ (1,0) [0|1] "" XXX
 SG_ RR_DEFROST_BUTTON : 22|1@0+ (1,0) [0|1] "" XXX
 SG_ FAN_SPEED_UP_BUTTON : 24|1@0+ (1,0) [0|1] "" XXX
 SG_ FAN_SPEED_DOWN_BUTTON : 26|1@0+ (1,0) [0|1] "" XXX
 SG_ AIR_DIRECTION_BUTTON : 28|1@0+ (1,0) [0|1] "" XXX
 SG_ AC_BUTTON : 40|1@0+ (1,0) [0|1] "" XXX
 SG_ DRIVER_ONLY_BUTTON : 44|1@0+ (1,0) [0|1] "" XXX
 SG_ RECIRC_BUTTON : 48|1@0+ (1,0) [0|1] "" XXX
 SG_ HEAT_BUTTON : 52|1@0+ (1,0) [0|1] "" XXX

BO_ 1152 MCU_05_1000ms: 8 XXX
 SG_ MCU_Crc5Val : 0|16@1+ (1,0) [0|65535] "" XXX
 SG_ MCU_AlvCnt5Val : 16|8@1+ (1,0) [0|255] "" XXX
 SG_ VCRM_Mg1EstMtrTqVal : 24|8@1+ (1,0) [0|255] "" XXX
 SG_ VCRM_Mg1MtrDeratingFctrVal : 32|8@1+ (1,0) [0|255] "" XXX
 SG_ VCRM_Mg1InvtTempVal : 40|8@1+ (1,0) [0|255] "" XXX
 SG_ VCRM_Mg1MtrTempVal : 48|24@1+ (1,0) [0|16777215] "" XXX
 SG_ VCRM_Mg1IgbtJnctnTempVal : 72|16@1+ (1,0) [0|65535] "" XXX
 SG_ VCRM_Mg1InvtInVoltVal : 88|8@1+ (1,0) [0|255] "" XXX
 SG_ VCRM_Mg1EwpSpdReq : 96|8@1+ (1,0) [0|255] "" XXX
 SG_ VCRM_Mg1HtsnkTempVal : 104|8@1+ (1,0) [0|255] "" XXX
 SG_ VCRM_Mg1ActlMtrRotatSpdRpmVal : 112|16@1+ (1,0) [0|65535] "" XXX
 SG_ VCRM_Mg1EwpActSpdRpmVal : 128|8@1+ (1,0) [0|255] "" XXX
 SG_ MCU_Mg1IdcCurrent : 136|48@1+ (1,0) [0|281474976710655] "" XXX
 SG_ VCRM_Mg1LampReq : 184|2@1+ (1,0) [0|3] "" XXX
 SG_ VCRM_Mg1McuReq : 186|6@1+ (1,0) [0|63] "" XXX

BO_ 1157 VESS_PE: 8 XXX
 SG_ VESS_CLU_Warning : 6|5@1+ (1,0) [0|31] "" XXX
 SG_ VESS_LogSnapshotState : 11|2@1+ (1,0) [0|3] "" XXX
 SG_ VESS_ChgGuideMdLvlSt : 13|3@1+ (1,0) [0|7] "" XXX
 SG_ VESS_SWVerMajor : 16|8@1+ (1,0) [0|255] "" XXX
 SG_ VESS_SWVerMinor : 24|8@1+ (1,0) [0|255] "" XXX

BO_ 1159 HU_APSU_PE: 8 XXX
 SG_ C_AstRclBwdSw_HU : 0|2@1+ (1,0) [0|3] "" XXX
 SG_ C_AstRclFwdSw_HU : 2|2@1+ (1,0) [0|3] "" XXX
 SG_ C_AstSlideBwdSw_HU : 4|2@1+ (1,0) [0|3] "" XXX
 SG_ C_AstSlideFwdSw_HU : 6|2@1+ (1,0) [0|3] "" XXX
 SG_ C_AstHeightDnSw_HU : 8|2@1+ (1,0) [0|3] "" XXX
 SG_ C_AstHeightUpSw_HU : 10|2@1+ (1,0) [0|3] "" XXX
 SG_ C_AstTiltDnSw_HU : 12|2@1+ (1,0) [0|3] "" XXX
 SG_ C_AstTiltUpSw_HU : 14|2@1+ (1,0) [0|3] "" XXX
 SG_ C_AstLumbarDefSw_HU : 16|2@1+ (1,0) [0|3] "" XXX
 SG_ C_AstLumbarLowSw_HU : 18|2@1+ (1,0) [0|3] "" XXX
 SG_ C_AstLumbarMidSw_HU : 20|2@1+ (1,0) [0|3] "" XXX
 SG_ C_AstLumbarUpSw_HU : 22|2@1+ (1,0) [0|3] "" XXX
 SG_ C_RRSlideFwdSw_HU : 24|2@1+ (1,0) [0|3] "" XXX
 SG_ C_RRSlideBwdSw_HU : 26|2@1+ (1,0) [0|3] "" XXX
 SG_ C_RLSlideFwdSw_HU : 28|2@1+ (1,0) [0|3] "" XXX
 SG_ C_RLSlideBwdSw_HU : 30|2@1+ (1,0) [0|3] "" XXX

BO_ 1162 ODS_01_1000ms: 8 XXX
 SG_ ccIC_HU_Crc3Val : 0|12@1+ (1,0) [0|4095] "" XXX
 SG_ SMK_AlvCnt3Val : 12|4@1+ (1,0) [0|15] "" XXX
 SG_ ccIC_HU_AlvCnt3Val : 16|8@1+ (1,0) [0|255] "" XXX
 SG_ ODS_IdVal : 24|8@1+ (1,0) [0|255] "" XXX
 SG_ ODS_OccClassSta : 32|8@1+ (1,0) [0|255] "" XXX
 SG_ ODS_DiagSta : 40|8@1+ (1,0) [0|255] "" XXX
 SG_ ODS_SBRClassSta : 48|8@1+ (1,0) [0|255] "" XXX

BO_ 1167 ICU_11_1000ms: 8 XXX
 SG_ ICU_Crc11Val : 0|8@1+ (1,0) [0|255] "" XXX
 SG_ IGN_AutoOff_WarnSta : 8|2@1+ (1,0) [0|3] "" XXX
 SG_ Bat_dischrg : 10|2@1+ (1,0) [0|3] "" XXX
 SG_ ICU_AlvCnt11Val : 12|4@1+ (1,0) [0|15] "" XXX
 SG_ Batt_SoCWarningValue : 16|16@1+ (1,0) [0|65535] "" XXX
 SG_ C_StrgWhlHeatingOpt : 32|2@1+ (1,0) [0|3] "" XXX
 SG_ C_StrgWhlHeatingSWInf : 34|2@1+ (1,0) [0|3] "" XXX
 SG_ ICU_BattAutoCutPreWrng : 36|4@1+ (1,0) [0|15] "" XXX
 SG_ IGN_AutoOff_WarnSta_CLU : 40|8@1+ (1,0) [0|255] "" XXX

BO_ 1168 BMS_13_48V_100ms_4_CR_LdcVoltCmd: 8 XXX
 SG_ xEV_BatEvtAlarm_HS : 0|8@1+ (1,0) [0|255] "" XXX

BO_ 1172 WPC_01_200ms_WPC: 8 XXX
 SG_ RRPSM_SWVerMajor1 : 0|7@1+ (1,0) [0|127] "" XXX
 SG_ ROA_SWVerMinor1 : 7|1@1+ (1,0) [0|1] "" XXX
 SG_ RRPSM_SWVerMinor1 : 8|6@1+ (1,0) [0|63] "" XXX
 SG_ ROA_SWVerMinor2 : 14|2@1+ (1,0) [0|3] "" XXX
 SG_ RRPSM_SWVerMinor2 : 16|8@1+ (1,0) [0|255] "" XXX

BO_ 1173 AFCU_DRV_02_200ms: 8 XXX
 SG_ C_ApprUnlockRValue : 0|2@1+ (1,0) [0|3] "" XXX
 SG_ C_ApprUnlockStatus : 2|1@1+ (1,0) [0|1] "" XXX
 SG_ AutoFlushHandleSwOption : 3|3@1+ (1,0) [0|7] "" XXX
 SG_ Touch_TypeOption_DRV : 6|2@1+ (1,0) [0|3] "" XXX

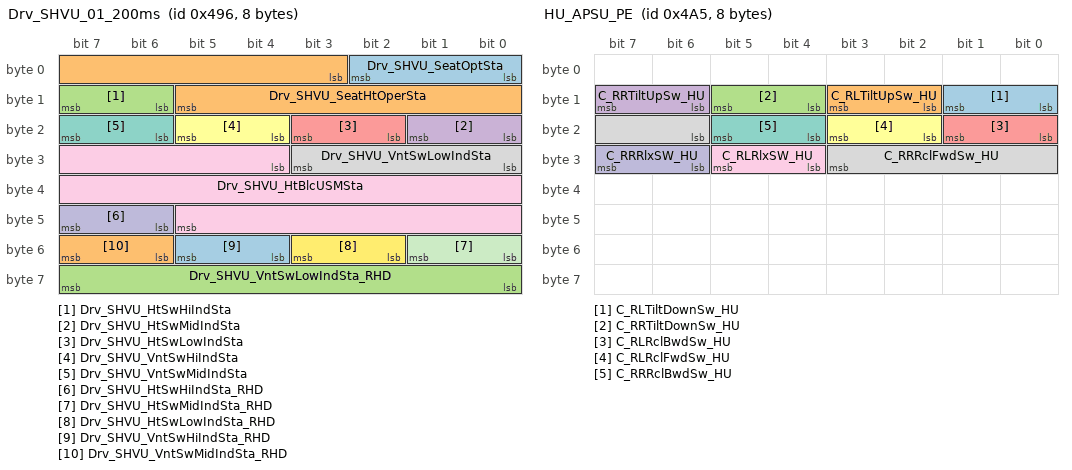
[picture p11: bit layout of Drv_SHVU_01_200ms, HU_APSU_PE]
BO_ 1174 Drv_SHVU_01_200ms: 8 XXX
 SG_ Drv_SHVU_SeatOptSta : 0|3@1+ (1,0) [0|7] "" XXX
 SG_ Drv_SHVU_SeatHtOperSta : 3|11@1+ (1,0) [0|2047] "" XXX
 SG_ Drv_SHVU_HtSwHiIndSta : 14|2@1+ (1,0) [0|3] "" XXX
 SG_ Drv_SHVU_HtSwMidIndSta : 16|2@1+ (1,0) [0|3] "" XXX
 SG_ Drv_SHVU_HtSwLowIndSta : 18|2@1+ (1,0) [0|3] "" XXX
 SG_ Drv_SHVU_VntSwHiIndSta : 20|2@1+ (1,0) [0|3] "" XXX
 SG_ Drv_SHVU_VntSwMidIndSta : 22|2@1+ (1,0) [0|3] "" XXX
 SG_ Drv_SHVU_VntSwLowIndSta : 24|4@1+ (1,0) [0|15] "" XXX
 SG_ Drv_SHVU_HtBlcUSMSta : 28|18@1+ (1,0) [0|262143] "" XXX
 SG_ Drv_SHVU_HtSwHiIndSta_RHD : 46|2@1+ (1,0) [0|3] "" XXX
 SG_ Drv_SHVU_HtSwMidIndSta_RHD : 48|2@1+ (1,0) [0|3] "" XXX
 SG_ Drv_SHVU_HtSwLowIndSta_RHD : 50|2@1+ (1,0) [0|3] "" XXX
 SG_ Drv_SHVU_VntSwHiIndSta_RHD : 52|2@1+ (1,0) [0|3] "" XXX
 SG_ Drv_SHVU_VntSwMidIndSta_RHD : 54|2@1+ (1,0) [0|3] "" XXX
 SG_ Drv_SHVU_VntSwLowIndSta_RHD : 56|8@1+ (1,0) [0|255] "" XXX

BO_ 1183 HU_DATC_E: 8 XXX
 SG_ HU_DATC_RearLockSet_New : 0|2@1+ (1,0) [0|3] "" XXX
 SG_ HU_DATC_RlTempUpDn : 2|2@1+ (1,0) [0|3] "" XXX
 SG_ HU_DATC_PsTempUpDn : 4|2@1+ (1,0) [0|3] "" XXX
 SG_ HU_DATC_DrTempUpDn : 6|6@1+ (1,0) [0|63] "" XXX
 SG_ HU_DATC_MainBlower : 12|8@1+ (1,0) [0|255] "" XXX
 SG_ HU_DATC_RearBlower : 20|4@1+ (1,0) [0|15] "" XXX
 SG_ HU_DATC_RearModeSet : 24|4@1+ (1,0) [0|15] "" XXX
 SG_ HU_DATC_FrontModeSet : 28|6@1+ (1,0) [0|63] "" XXX
 SG_ HU_DATC_IntakeSet : 34|4@1+ (1,0) [0|15] "" XXX
 SG_ HU_DATC_AutoSet : 38|4@1+ (1,0) [0|15] "" XXX
 SG_ HU_DATC_FrontDefog : 42|2@1+ (1,0) [0|3] "" XXX
 SG_ HU_DATC_RearSyncSet : 44|2@1+ (1,0) [0|3] "" XXX
 SG_ HU_DATC_AcSet : 46|2@1+ (1,0) [0|3] "" XXX
 SG_ DATC_ADSOnOffSet : 48|2@1+ (1,0) [0|3] "" XXX
 SG_ DATC_SmartVentOnOffSet : 50|6@1+ (1,0) [0|63] "" XXX
 SG_ HU_DATC_AirCleaningSet : 56|2@1+ (1,0) [0|3] "" XXX
 SG_ HU_DATC_MainBlowerUpDn : 58|4@1+ (1,0) [0|15] "" XXX
 SG_ HU_DATC_RearAutoDisp : 62|2@1+ (1,0) [0|3] "" XXX

BO_ 1184 HU_DATC_E: 8 XXX
 SG_ HU_DATC_DrTempSetC : 0|8@1+ (1,0) [0|255] "" XXX
 SG_ HU_DATC_DrTempSetF : 8|8@1+ (1,0) [0|255] "" XXX
 SG_ CF_Datc_DefLogic_USM_Set : 16|2@1+ (1,0) [0|3] "" XXX
 SG_ HU_DATC_RlBlowerUpDn : 18|8@1+ (1,0) [0|255] "" XXX
 SG_ HU_DATC_SyncSet : 26|4@1+ (1,0) [0|15] "" XXX
 SG_ CF_Datc_AutoFresh_USM_Set : 30|2@1+ (1,0) [0|3] "" XXX
 SG_ HU_DATC_RlTempSetC : 32|8@1+ (1,0) [0|255] "" XXX
 SG_ HU_DATC_RlTempSetF : 40|8@1+ (1,0) [0|255] "" XXX
 SG_ HU_DATC_PsTempSetC : 48|8@1+ (1,0) [0|255] "" XXX
 SG_ HU_DATC_PsTempSetF : 56|8@1+ (1,0) [0|255] "" XXX

BO_ 1185 HU_CNTL_E: 8 XXX
 SG_ C_AstWindowCmdAVN : 0|4@1+ (1,0) [0|15] "" XXX
 SG_ C_DrvWindowCmdAVN : 4|4@1+ (1,0) [0|15] "" XXX
 SG_ C_PTGCNTLCmdAVN : 8|6@1+ (1,0) [0|63] "" XXX
 SG_ C_RrDefoggerCmdAVN : 14|10@1+ (1,0) [0|1023] "" XXX
 SG_ C_RRWindowCmdAVN : 24|4@1+ (1,0) [0|15] "" XXX
 SG_ C_RLWindowCmdAVN : 28|6@1+ (1,0) [0|63] "" XXX
 SG_ C_BlindCmdAVN : 34|3@1+ (1,0) [0|7] "" XXX
 SG_ C_GlassCmdAVN : 37|3@1+ (1,0) [0|7] "" XXX

BO_ 1186 HU_GW_E: 8 XXX
 SG_ C_RemoteWdwCMDHU : 16|12@1+ (1,0) [0|4095] "" XXX
 SG_ HU_CDMOpenCmd : 28|2@1+ (1,0) [0|3] "" XXX
 SG_ C_PreCrankReq : 30|2@1+ (1,0) [0|3] "" XXX
 SG_ C_TeleAstSeatOpCmdIBOX : 32|4@1+ (1,0) [0|15] "" XXX
 SG_ C_TeleDrvSeatOpCmdIBOX : 36|4@1+ (1,0) [0|15] "" XXX
 SG_ C_TeleRRSeatOpCmdIBOX : 40|4@1+ (1,0) [0|15] "" XXX
 SG_ C_TeleRLSeatOpCmdIBOX : 44|4@1+ (1,0) [0|15] "" XXX

BO_ 1187 HU_Navi_ISLW_PE: 8 XXX
 SG_ Navi_ISLW_LinkClass : 0|3@1+ (1,0) [0|7] "" XXX
 SG_ Navi_ISLW_Frwinfo : 3|3@1+ (1,0) [0|7] "" XXX
 SG_ Navi_ISLW_SpdUnit : 6|2@1+ (1,0) [0|3] "" XXX
 SG_ Navi_ISLW_SpdLimit : 8|8@1+ (1,0) [0|255] "" XXX
 SG_ Navi_ISLW_CountryCode : 16|11@1+ (1,0) [0|2047] "" XXX
 SG_ Navi_ISLW_MapSource : 27|3@1+ (1,0) [0|7] "" XXX
 SG_ Navi_ISLW_TollExist : 30|8@1+ (1,0) [0|255] "" XXX
 SG_ Navi_ISLW_TunnelExist : 38|2@1+ (1,0) [0|3] "" XXX
 SG_ Navi_ISLW_TimeSpd : 40|8@1+ (1,0) [0|255] "" XXX

BO_ 1189 HU_APSU_PE: 8 XXX
 SG_ C_RLTiltDownSw_HU : 8|2@1+ (1,0) [0|3] "" XXX
 SG_ C_RLTiltUpSw_HU : 10|2@1+ (1,0) [0|3] "" XXX
 SG_ C_RRTiltDownSw_HU : 12|2@1+ (1,0) [0|3] "" XXX
 SG_ C_RRTiltUpSw_HU : 14|2@1+ (1,0) [0|3] "" XXX
 SG_ C_RLRclBwdSw_HU : 16|2@1+ (1,0) [0|3] "" XXX
 SG_ C_RLRclFwdSw_HU : 18|2@1+ (1,0) [0|3] "" XXX
 SG_ C_RRRclBwdSw_HU : 20|2@1+ (1,0) [0|3] "" XXX
 SG_ C_RRRclFwdSw_HU : 22|6@1+ (1,0) [0|63] "" XXX
 SG_ C_RLRlxSW_HU : 28|2@1+ (1,0) [0|3] "" XXX
 SG_ C_RRRlxSW_HU : 30|2@1+ (1,0) [0|3] "" XXX

BO_ 1190 HU_AVM_E_00_HU_AVM: 8 XXX
 SG_ HU_BVM_Option : 0|6@1+ (1,0) [0|63] "" XXX
 SG_ HU_RVM_CameraOff : 6|30@1+ (1,0) [0|1073741823] "" XXX
 SG_ HU_AVM_TopView_Option : 36|20@1+ (1,0) [0|1048575] "" XXX
 SG_ HU_AVM_FrontView_Option : 56|4@1+ (1,0) [0|15] "" XXX
 SG_ HU_AVM_RearView_Option : 60|4@1+ (1,0) [0|15] "" XXX

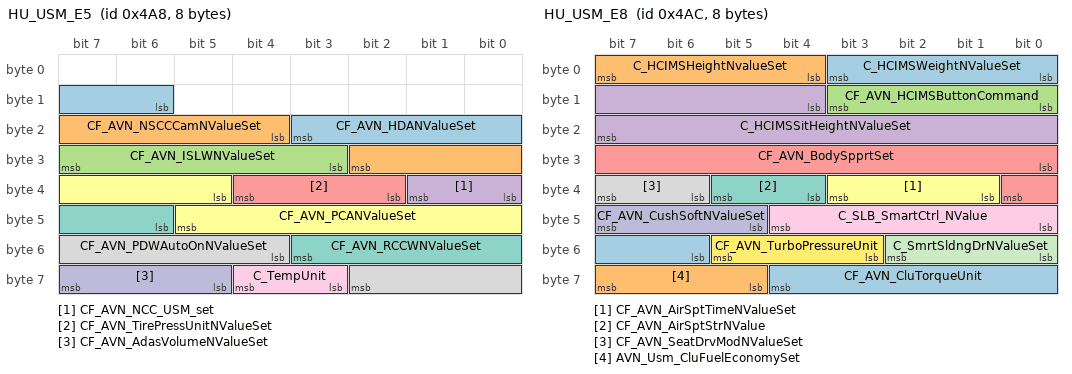
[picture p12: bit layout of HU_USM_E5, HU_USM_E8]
BO_ 1192 HU_USM_E5: 8 XXX
 SG_ CF_AVN_HDANValueSet : 14|6@1+ (1,0) [0|63] "" XXX
 SG_ CF_AVN_NSCCCamNValueSet : 20|7@1+ (1,0) [0|127] "" XXX
 SG_ CF_AVN_ISLWNValueSet : 27|5@1+ (1,0) [0|31] "" XXX
 SG_ CF_AVN_NCC_USM_set : 32|2@1+ (1,0) [0|3] "" XXX
 SG_ CF_AVN_TirePressUnitNValueSet : 34|3@1+ (1,0) [0|7] "" XXX
 SG_ CF_AVN_PCANValueSet : 37|9@1+ (1,0) [0|511] "" XXX
 SG_ CF_AVN_RCCWNValueSet : 46|6@1+ (1,0) [0|63] "" XXX
 SG_ CF_AVN_PDWAutoOnNValueSet : 52|7@1+ (1,0) [0|127] "" XXX
 SG_ C_TempUnit : 59|2@1+ (1,0) [0|3] "" XXX
 SG_ CF_AVN_AdasVolumeNValueSet : 61|3@1+ (1,0) [0|7] "" XXX

BO_ 1193 HU_USM_E6: 8 XXX
 SG_ C_PTGMNValueSet : 0|2@1+ (1,0) [0|3] "" XXX
 SG_ CF_AVN_ADrUNValueSet : 2|6@1+ (1,0) [0|63] "" XXX
 SG_ CF_AVN_EscortHLNValueSet : 8|2@1+ (1,0) [0|3] "" XXX
 SG_ CF_AVN_PSMNValueSet : 10|3@1+ (1,0) [0|7] "" XXX
 SG_ C_HfreeTrunkTgNValueSet : 13|4@1+ (1,0) [0|15] "" XXX
 SG_ CF_AVN_TrfChgSet : 17|2@1+ (1,0) [0|3] "" XXX
 SG_ CF_AVN_SCMNValueSet : 19|2@1+ (1,0) [0|3] "" XXX
 SG_ CF_AVN_OTTurnNValueSet : 21|3@1+ (1,0) [0|7] "" XXX
 SG_ CF_Gway_WPCNValueSet : 24|2@1+ (1,0) [0|3] "" XXX
 SG_ C_AVN_RearWiperNValueSet : 26|2@1+ (1,0) [0|3] "" XXX
 SG_ C_UnlockWelocomeNValueSet : 28|2@1+ (1,0) [0|3] "" XXX
 SG_ C_SmartWelocomeNValueSet : 30|2@1+ (1,0) [0|3] "" XXX
 SG_ CF_AVN_PTGSpeedNValueSet : 32|2@1+ (1,0) [0|3] "" XXX
 SG_ CR_Datc_DRSeatWheel_USM_Set : 34|4@1+ (1,0) [0|15] "" XXX
 SG_ CF_AVN_TTUnlockNValueSet : 38|2@1+ (1,0) [0|3] "" XXX
 SG_ CF_Gway_RWPCNValueSet : 40|4@1+ (1,0) [0|15] "" XXX
 SG_ C_PSDNValueSet : 44|5@1+ (1,0) [0|31] "" XXX
 SG_ CF_Avn_HAPTICWARNINGNValueSet : 49|3@1+ (1,0) [0|7] "" XXX
 SG_ CR_Datc_DRSeatHeat_USM_Set : 52|2@1+ (1,0) [0|3] "" XXX
 SG_ C_WALNValueSet : 54|2@1+ (1,0) [0|3] "" XXX
 SG_ C_ApprUnlockNValue : 56|8@1+ (1,0) [0|255] "" XXX

BO_ 1195 HU_USM_E7: 8 XXX
 SG_ CF_AVN_CluWelcomeSnd : 0|2@1+ (1,0) [0|3] "" XXX
 SG_ CF_AVN_CluAutoInitFuelEconomy : 2|3@1+ (1,0) [0|7] "" XXX
 SG_ CF_AVN_CluVoiceVolume : 5|3@1+ (1,0) [0|7] "" XXX
 SG_ CF_AVN_CluServiceReminderSet : 8|2@1+ (1,0) [0|3] "" XXX
 SG_ CF_AVN_CluTransmissionDisp : 10|2@1+ (1,0) [0|3] "" XXX
 SG_ CF_AVN_CluWiperLight : 12|2@1+ (1,0) [0|3] "" XXX
 SG_ CF_AVN_CluRoadInfoGuide : 14|3@1+ (1,0) [0|7] "" XXX
 SG_ CF_AVN_CluUserSettingPeriod : 17|10@1+ (1,0) [0|1023] "" XXX
 SG_ CF_AVN_CluFuelEconUnit_mi : 27|2@1+ (1,0) [0|3] "" XXX
 SG_ CF_AVN_CluFuelEconUnit_km : 29|2@1+ (1,0) [0|3] "" XXX
 SG_ CF_AVN_CluUserSettingDistance : 31|18@1+ (1,0) [0|262143] "" XXX
 SG_ CF_AVN_CluRheostatLvl : 49|5@1+ (1,0) [0|31] "" XXX
 SG_ CF_AVN_EVReset : 54|2@1+ (1,0) [0|3] "" XXX
 SG_ CF_AVN_UnitReset : 56|2@1+ (1,0) [0|3] "" XXX
 SG_ CF_AVN_IcyRoadWarn : 58|2@1+ (1,0) [0|3] "" XXX
 SG_ CF_AVN_CluServiceReminderReset : 60|2@1+ (1,0) [0|3] "" XXX
 SG_ CF_AVN_CluUSMReset : 62|2@1+ (1,0) [0|3] "" XXX

BO_ 1196 HU_USM_E8: 8 XXX
 SG_ C_HCIMSWeightNValueSet : 0|4@1+ (1,0) [0|15] "" XXX
 SG_ C_HCIMSHeightNvalueSet : 4|4@1+ (1,0) [0|15] "" XXX
 SG_ CF_AVN_HCIMSButtonCommand : 8|4@1+ (1,0) [0|15] "" XXX
 SG_ C_HCIMSSitHeightNValueSet : 12|12@1+ (1,0) [0|4095] "" XXX
 SG_ CF_AVN_BodySpprtSet : 24|9@1+ (1,0) [0|511] "" XXX
 SG_ CF_AVN_AirSptTimeNValueSet : 33|3@1+ (1,0) [0|7] "" XXX
 SG_ CF_AVN_AirSptStrNValue : 36|2@1+ (1,0) [0|3] "" XXX
 SG_ CF_AVN_SeatDrvModNValueSet : 38|2@1+ (1,0) [0|3] "" XXX
 SG_ C_SLB_SmartCtrl_NValue : 40|5@1+ (1,0) [0|31] "" XXX
 SG_ CF_AVN_CushSoftNValueSet : 45|3@1+ (1,0) [0|7] "" XXX
 SG_ C_SmrtSldngDrNValueSet : 48|3@1+ (1,0) [0|7] "" XXX
 SG_ CF_AVN_TurboPressureUnit : 51|3@1+ (1,0) [0|7] "" XXX
 SG_ CF_AVN_CluTorqueUnit : 54|7@1+ (1,0) [0|127] "" XXX
 SG_ AVN_Usm_CluFuelEconomySet : 61|3@1+ (1,0) [0|7] "" XXX

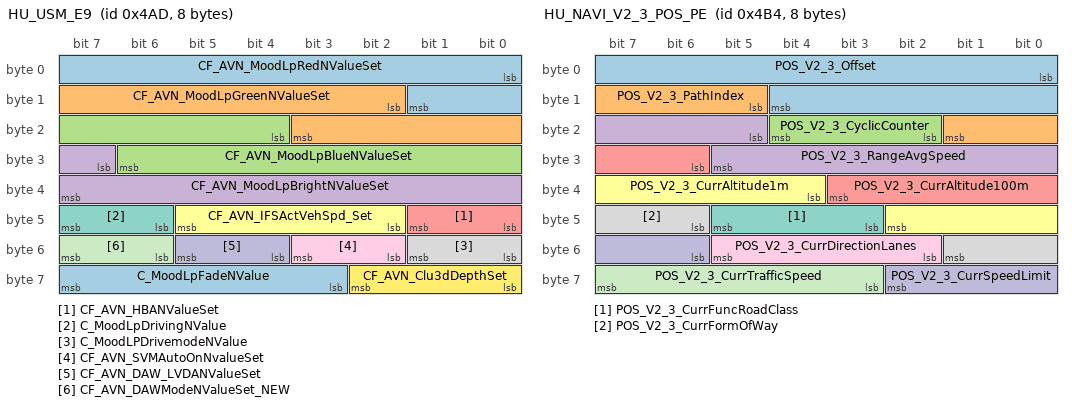
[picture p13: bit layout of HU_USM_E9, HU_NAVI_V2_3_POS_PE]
BO_ 1197 HU_USM_E9: 8 XXX
 SG_ CF_AVN_MoodLpRedNValueSet : 0|10@1+ (1,0) [0|1023] "" XXX
 SG_ CF_AVN_MoodLpGreenNValueSet : 10|10@1+ (1,0) [0|1023] "" XXX
 SG_ CF_AVN_MoodLpBlueNValueSet : 20|11@1+ (1,0) [0|2047] "" XXX
 SG_ CF_AVN_MoodLpBrightNValueSet : 31|9@1+ (1,0) [0|511] "" XXX
 SG_ CF_AVN_HBANValueSet : 40|2@1+ (1,0) [0|3] "" XXX
 SG_ CF_AVN_IFSActVehSpd_Set : 42|4@1+ (1,0) [0|15] "" XXX
 SG_ C_MoodLpDrivingNValue : 46|2@1+ (1,0) [0|3] "" XXX
 SG_ C_MoodLPDrivemodeNValue : 48|2@1+ (1,0) [0|3] "" XXX
 SG_ CF_AVN_SVMAutoOnNvalueSet : 50|2@1+ (1,0) [0|3] "" XXX
 SG_ CF_AVN_DAW_LVDANValueSet : 52|2@1+ (1,0) [0|3] "" XXX
 SG_ CF_AVN_DAWModeNValueSet_NEW : 54|2@1+ (1,0) [0|3] "" XXX
 SG_ CF_AVN_Clu3dDepthSet : 56|3@1+ (1,0) [0|7] "" XXX
 SG_ C_MoodLpFadeNValue : 59|5@1+ (1,0) [0|31] "" XXX

BO_ 1198 HU_USM_E10: 8 XXX
 SG_ CF_AVN_ISLANValueSet : 56|3@1+ (1,0) [0|7] "" XXX
 SG_ CF_AVN_ISLAOffstNValueSet : 59|3@1+ (1,0) [0|7] "" XXX
 SG_ CF_AVN_ISLAAutoNValueSet : 62|2@1+ (1,0) [0|3] "" XXX

BO_ 1201 HU_EV_P_02_CF_HU_DepartSet2: 8 XXX
 SG_ ICU_Popup_Enable : 26|6@1+ (1,0) [0|63] "" XXX

BO_ 1204 HU_NAVI_V2_3_POS_PE: 8 XXX
 SG_ POS_V2_3_Offset : 0|13@1+ (1,0) [0|8191] "" XXX
 SG_ POS_V2_3_PathIndex : 13|5@1+ (1,0) [0|31] "" XXX
 SG_ POS_V2_3_CyclicCounter : 18|3@1+ (1,0) [0|7] "" XXX
 SG_ POS_V2_3_RangeAvgSpeed : 21|9@1+ (1,0) [0|511] "" XXX
 SG_ POS_V2_3_CurrAltitude100m : 30|6@1+ (1,0) [0|63] "" XXX
 SG_ POS_V2_3_CurrAltitude1m : 36|7@1+ (1,0) [0|127] "" XXX
 SG_ POS_V2_3_CurrFuncRoadClass : 43|3@1+ (1,0) [0|7] "" XXX
 SG_ POS_V2_3_CurrFormOfWay : 46|4@1+ (1,0) [0|15] "" XXX
 SG_ POS_V2_3_CurrDirectionLanes : 50|4@1+ (1,0) [0|15] "" XXX
 SG_ POS_V2_3_CurrSpeedLimit : 54|5@1+ (1,0) [0|31] "" XXX
 SG_ POS_V2_3_CurrTrafficSpeed : 59|5@1+ (1,0) [0|31] "" XXX

BO_ 1205 HU_NAVI_V2_3_PATH_PE: 8 XXX
 SG_ PATH_V2_3_CalculatedRoute : 2|2@1+ (1,0) [0|3] "" XXX
 SG_ PATH_V2_3_PathType : 4|3@1+ (1,0) [0|7] "" XXX
 SG_ PATH_V2_3_Value0 : 7|4@1+ (1,0) [0|15] "" XXX
 SG_ PATH_V2_3_Value1 : 11|5@1+ (1,0) [0|31] "" XXX
 SG_ PATH_V2_3_FuncRoadClass : 16|3@1+ (1,0) [0|7] "" XXX
 SG_ PATH_V2_3_TurnAngle : 19|8@1+ (1,0) [0|255] "" XXX
 SG_ PATH_V2_3_DirectionLanes : 27|4@1+ (1,0) [0|15] "" XXX
 SG_ PATH_V2_3_RemainingDistance : 31|12@1+ (1,0) [0|4095] "" XXX
 SG_ PATH_V2_3_MeanEffectiveSlope : 43|10@1+ (1,0) [0|1023] "" XXX
 SG_ PATH_V2_3_CyclicCounter : 53|3@1+ (1,0) [0|7] "" XXX

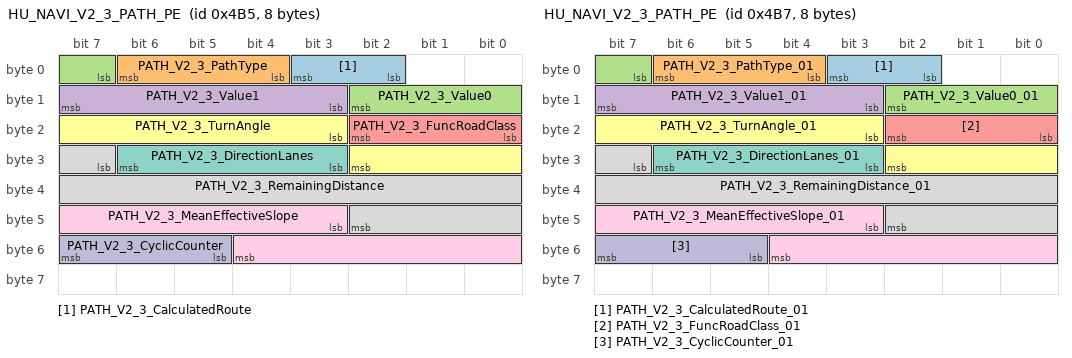
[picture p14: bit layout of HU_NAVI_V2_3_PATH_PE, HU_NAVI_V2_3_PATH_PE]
BO_ 1207 HU_NAVI_V2_3_PATH_PE: 8 XXX
 SG_ PATH_V2_3_CalculatedRoute_01 : 2|2@1+ (1,0) [0|3] "" XXX
 SG_ PATH_V2_3_PathType_01 : 4|3@1+ (1,0) [0|7] "" XXX
 SG_ PATH_V2_3_Value0_01 : 7|4@1+ (1,0) [0|15] "" XXX
 SG_ PATH_V2_3_Value1_01 : 11|5@1+ (1,0) [0|31] "" XXX
 SG_ PATH_V2_3_FuncRoadClass_01 : 16|3@1+ (1,0) [0|7] "" XXX
 SG_ PATH_V2_3_TurnAngle_01 : 19|8@1+ (1,0) [0|255] "" XXX
 SG_ PATH_V2_3_DirectionLanes_01 : 27|4@1+ (1,0) [0|15] "" XXX
 SG_ PATH_V2_3_RemainingDistance_01 : 31|12@1+ (1,0) [0|4095] "" XXX
 SG_ PATH_V2_3_MeanEffectiveSlope_01 : 43|10@1+ (1,0) [0|1023] "" XXX
 SG_ PATH_V2_3_CyclicCounter_01 : 53|3@1+ (1,0) [0|7] "" XXX

BO_ 1208 HU_NAVI_V2_3_META_E: 8 XXX
 SG_ META_V2_3_MapProvider : 0|3@1+ (1,0) [0|7] "" XXX
 SG_ META_V2_3_CountryCode : 3|10@1+ (1,0) [0|1023] "" XXX
 SG_ META_V2_3_RegionCode : 13|17@1+ (1,0) [0|131071] "" XXX
 SG_ META_V2_3_MajorProtocolVersion : 30|2@1+ (1,0) [0|3] "" XXX
 SG_ META_V2_3_MinorProtocolVersion : 32|4@1+ (1,0) [0|15] "" XXX
 SG_ META_V2_3_DrivingSide : 36|2@1+ (1,0) [0|3] "" XXX
 SG_ META_V2_3_SpeedUnit : 38|2@1+ (1,0) [0|3] "" XXX
 SG_ META_V2_3_Country_OptADAS : 40|5@1+ (1,0) [0|31] "" XXX
 SG_ META_V2_3_CyclicCounter : 45|3@1+ (1,0) [0|7] "" XXX

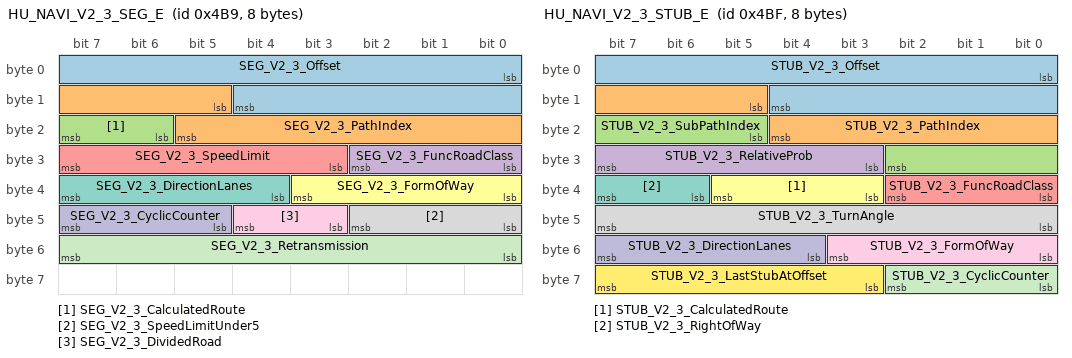
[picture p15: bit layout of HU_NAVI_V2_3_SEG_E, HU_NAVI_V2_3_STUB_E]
BO_ 1209 HU_NAVI_V2_3_SEG_E: 8 XXX
 SG_ SEG_V2_3_Offset : 0|13@1+ (1,0) [0|8191] "" XXX
 SG_ SEG_V2_3_PathIndex : 13|9@1+ (1,0) [0|511] "" XXX
 SG_ SEG_V2_3_CalculatedRoute : 22|2@1+ (1,0) [0|3] "" XXX
 SG_ SEG_V2_3_FuncRoadClass : 24|3@1+ (1,0) [0|7] "" XXX
 SG_ SEG_V2_3_SpeedLimit : 27|5@1+ (1,0) [0|31] "" XXX
 SG_ SEG_V2_3_FormOfWay : 32|4@1+ (1,0) [0|15] "" XXX
 SG_ SEG_V2_3_DirectionLanes : 36|4@1+ (1,0) [0|15] "" XXX
 SG_ SEG_V2_3_SpeedLimitUnder5 : 40|3@1+ (1,0) [0|7] "" XXX
 SG_ SEG_V2_3_DividedRoad : 43|2@1+ (1,0) [0|3] "" XXX
 SG_ SEG_V2_3_CyclicCounter : 45|3@1+ (1,0) [0|7] "" XXX
 SG_ SEG_V2_3_Retransmission : 48|8@1+ (1,0) [0|255] "" XXX

BO_ 1210 HU_NAVI_V2_3_PROSHORT_E: 8 XXX
 SG_ PROSHORT_V2_3_Offset : 0|13@1+ (1,0) [0|8191] "" XXX
 SG_ PROSHORT_V2_3_PathIndex : 13|10@1+ (1,0) [0|1023] "" XXX
 SG_ PROSHORT_V2_3_Distance : 23|10@1+ (1,0) [0|1023] "" XXX
 SG_ PROSHORT_V2_3_Value0 : 33|10@1+ (1,0) [0|1023] "" XXX
 SG_ PROSHORT_V2_3_Value1 : 43|10@1+ (1,0) [0|1023] "" XXX
 SG_ PROSHORT_V2_3_ProfileType : 53|5@1+ (1,0) [0|31] "" XXX
 SG_ PROSHORT_V2_3_CyclicCounter : 58|3@1+ (1,0) [0|7] "" XXX
 SG_ PROSHORT_V2_3_Accuracy : 61|3@1+ (1,0) [0|7] "" XXX

BO_ 1212 HU_NAVI_V2_3_PROSHORT_E: 8 XXX
 SG_ PROSHORT_V2_3_Offset_01 : 0|13@1+ (1,0) [0|8191] "" XXX
 SG_ PROSHORT_V2_3_PathIndex_01 : 13|10@1+ (1,0) [0|1023] "" XXX
 SG_ PROSHORT_V2_3_Distance_01 : 23|10@1+ (1,0) [0|1023] "" XXX
 SG_ PROSHORT_V2_3_Value0_01 : 33|10@1+ (1,0) [0|1023] "" XXX
 SG_ PROSHORT_V2_3_Value1_01 : 43|10@1+ (1,0) [0|1023] "" XXX
 SG_ PROSHORT_V2_3_ProfileType_01 : 53|5@1+ (1,0) [0|31] "" XXX
 SG_ PROSHORT_V2_3_CyclicCounter_01 : 58|3@1+ (1,0) [0|7] "" XXX
 SG_ PROSHORT_V2_3_Accuracy_01 : 61|3@1+ (1,0) [0|7] "" XXX

BO_ 1213 HU_NAVI_V2_3_PROSHORT_E: 8 XXX
 SG_ PROSHORT_V2_3_Offset_02 : 0|13@1+ (1,0) [0|8191] "" XXX
 SG_ PROSHORT_V2_3_PathIndex_02 : 13|10@1+ (1,0) [0|1023] "" XXX
 SG_ PROSHORT_V2_3_Distance_02 : 23|10@1+ (1,0) [0|1023] "" XXX
 SG_ PROSHORT_V2_3_Value0_02 : 33|10@1+ (1,0) [0|1023] "" XXX
 SG_ PROSHORT_V2_3_Value1_02 : 43|10@1+ (1,0) [0|1023] "" XXX
 SG_ PROSHORT_V2_3_ProfileType_02 : 53|5@1+ (1,0) [0|31] "" XXX
 SG_ PROSHORT_V2_3_CyclicCounter_02 : 58|3@1+ (1,0) [0|7] "" XXX
 SG_ PROSHORT_V2_3_Accuracy_02 : 61|3@1+ (1,0) [0|7] "" XXX

BO_ 1214 HU_NAVI_V2_3_PROLONG_E: 8 XXX
 SG_ PROLONG_V2_3_Value : 0|32@1+ (1,0) [0|4294967295] "" XXX
 SG_ PROLONG_V2_3_Offset : 32|16@1+ (1,0) [0|65535] "" XXX
 SG_ PROLONG_V2_3_PathIndex : 48|6@1+ (1,0) [0|63] "" XXX
 SG_ PROLONG_V2_3_ProfileType : 54|5@1+ (1,0) [0|31] "" XXX
 SG_ PROLONG_V2_3_CyclicCounter : 59|3@1+ (1,0) [0|7] "" XXX
 SG_ PROLONG_V2_3_Update : 62|2@1+ (1,0) [0|3] "" XXX

BO_ 1215 HU_NAVI_V2_3_STUB_E: 8 XXX
 SG_ STUB_V2_3_Offset : 0|13@1+ (1,0) [0|8191] "" XXX
 SG_ STUB_V2_3_PathIndex : 13|8@1+ (1,0) [0|255] "" XXX
 SG_ STUB_V2_3_SubPathIndex : 21|6@1+ (1,0) [0|63] "" XXX
 SG_ STUB_V2_3_RelativeProb : 27|5@1+ (1,0) [0|31] "" XXX
 SG_ STUB_V2_3_FuncRoadClass : 32|3@1+ (1,0) [0|7] "" XXX
 SG_ STUB_V2_3_CalculatedRoute : 35|3@1+ (1,0) [0|7] "" XXX
 SG_ STUB_V2_3_RightOfWay : 38|2@1+ (1,0) [0|3] "" XXX
 SG_ STUB_V2_3_TurnAngle : 40|8@1+ (1,0) [0|255] "" XXX
 SG_ STUB_V2_3_FormOfWay : 48|4@1+ (1,0) [0|15] "" XXX
 SG_ STUB_V2_3_DirectionLanes : 52|4@1+ (1,0) [0|15] "" XXX
 SG_ STUB_V2_3_CyclicCounter : 56|3@1+ (1,0) [0|7] "" XXX
 SG_ STUB_V2_3_LastStubAtOffset : 59|5@1+ (1,0) [0|31] "" XXX

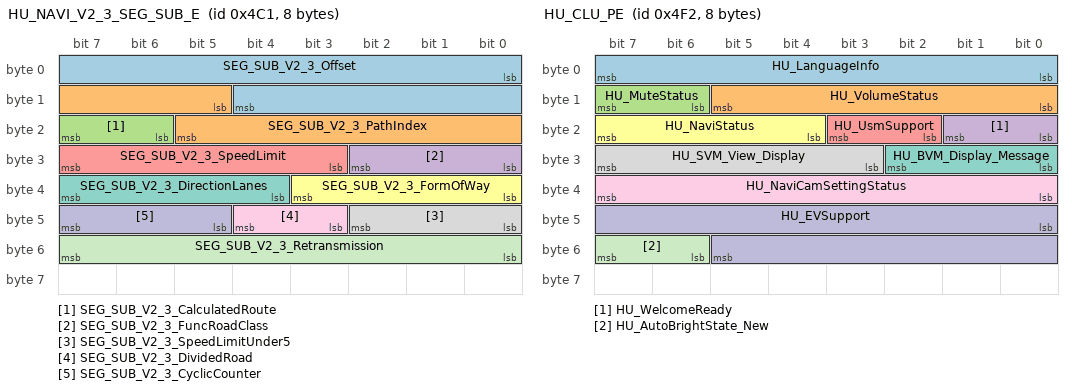
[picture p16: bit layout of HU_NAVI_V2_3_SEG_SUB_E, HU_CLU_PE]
BO_ 1217 HU_NAVI_V2_3_SEG_SUB_E: 8 XXX
 SG_ SEG_SUB_V2_3_Offset : 0|13@1+ (1,0) [0|8191] "" XXX
 SG_ SEG_SUB_V2_3_PathIndex : 13|9@1+ (1,0) [0|511] "" XXX
 SG_ SEG_SUB_V2_3_CalculatedRoute : 22|2@1+ (1,0) [0|3] "" XXX
 SG_ SEG_SUB_V2_3_FuncRoadClass : 24|3@1+ (1,0) [0|7] "" XXX
 SG_ SEG_SUB_V2_3_SpeedLimit : 27|5@1+ (1,0) [0|31] "" XXX
 SG_ SEG_SUB_V2_3_FormOfWay : 32|4@1+ (1,0) [0|15] "" XXX
 SG_ SEG_SUB_V2_3_DirectionLanes : 36|4@1+ (1,0) [0|15] "" XXX
 SG_ SEG_SUB_V2_3_SpeedLimitUnder5 : 40|3@1+ (1,0) [0|7] "" XXX
 SG_ SEG_SUB_V2_3_DividedRoad : 43|2@1+ (1,0) [0|3] "" XXX
 SG_ SEG_SUB_V2_3_CyclicCounter : 45|3@1+ (1,0) [0|7] "" XXX
 SG_ SEG_SUB_V2_3_Retransmission : 48|8@1+ (1,0) [0|255] "" XXX

BO_ 1218 HU_USM_E11: 64 XXX
 SG_ C_RH_Unfolding_SW : 0|2@1+ (1,0) [0|3] "" XXX
 SG_ C_RH_Folding_SW : 2|2@1+ (1,0) [0|3] "" XXX
 SG_ C_LH_Unfolding_SW : 4|2@1+ (1,0) [0|3] "" XXX
 SG_ C_LH_Folding_SW : 6|2@1+ (1,0) [0|3] "" XXX
 SG_ CF_AVN_HDALCFuncNValueSet : 8|2@1+ (1,0) [0|3] "" XXX
 SG_ C_PSMHeightNValueSet : 10|3@1+ (1,0) [0|7] "" XXX
 SG_ C_AVN_PTGHeightNValueSet : 13|3@1+ (1,0) [0|7] "" XXX
 SG_ CF_AVN_SCCMLReset : 16|2@1+ (1,0) [0|3] "" XXX
 SG_ C_TgltAwayCloseNValue : 18|2@1+ (1,0) [0|3] "" XXX
 SG_ C_HAnBNValueSet : 20|2@1+ (1,0) [0|3] "" XXX
 SG_ CF_AVN_RrSeatRemindNValueSet : 22|2@1+ (1,0) [0|3] "" XXX
 SG_ CF_AVN_DSWNValueSet : 24|2@1+ (1,0) [0|3] "" XXX
 SG_ CF_AVN_RRPSU_RLNValueSet : 26|3@1+ (1,0) [0|7] "" XXX
 SG_ CF_AVN_APSUNValueSet : 29|6@1+ (1,0) [0|63] "" XXX
 SG_ CF_AVN_NCC_CameraNValueSet : 35|2@1+ (1,0) [0|3] "" XXX
 SG_ CF_AVN_FCAJnctnNValueSet : 37|2@1+ (1,0) [0|3] "" XXX
 SG_ CF_AVN_RRPSU_RRNValueSet : 39|3@1+ (1,0) [0|7] "" XXX
 SG_ CF_AVN_HtBlcAstNValueSet : 42|4@1+ (1,0) [0|15] "" XXX
 SG_ CF_AVN_HtBlcDrvNValueSet : 46|4@1+ (1,0) [0|15] "" XXX
 SG_ CF_AVN_SCCModeNValueSet : 50|2@1+ (1,0) [0|3] "" XXX
 SG_ CF_AVN_SCCMLChar1Set : 52|4@1+ (1,0) [0|15] "" XXX
 SG_ CF_AVN_UIPNValueSet : 56|2@1+ (1,0) [0|3] "" XXX
 SG_ CF_AVN_SCCMLChar2Set : 58|3@1+ (1,0) [0|7] "" XXX
 SG_ CF_AVN_SCCMLChar3Set : 61|3@1+ (1,0) [0|7] "" XXX
 SG_ CF_AVN_NmodeFCAoffNValue : 64|6@1+ (1,0) [0|63] "" XXX

BO_ 1219 HU_BLTN_CAM_E_01_BLTN_CAM_StoProp: 8 XXX
 SG_ DVRS_Display_Advanced_TBT : 4|1@1+ (1,0) [0|1] "" XXX
 SG_ HU_Display_Advanced_TBT : 5|3@1+ (1,0) [0|7] "" XXX
 SG_ DVRS_Rec_Normal_NvalueSet : 8|2@1+ (1,0) [0|3] "" XXX
 SG_ DVRS_Rec_Crash_NvalueSet : 10|2@1+ (1,0) [0|3] "" XXX
 SG_ DVRS_Rec_Normal_Prk_NvalueSet : 12|2@1+ (1,0) [0|3] "" XXX
 SG_ DVRS_Rec_Crash_Prk_NvalueSet : 14|2@1+ (1,0) [0|3] "" XXX

BO_ 1220 HU_NFC_E: 8 XXX
 SG_ CF_AVN_ProfileIDNValueSet : 2|4@1+ (1,0) [0|15] "" XXX
 SG_ CF_AVN_CardKeyEnableNValueSet : 6|2@1+ (1,0) [0|3] "" XXX
 SG_ CF_AVN_DigitKeyEnableNValueSet : 8|2@1+ (1,0) [0|3] "" XXX
 SG_ CF_AVN_OwnerPhoneNValueSet : 10|2@1+ (1,0) [0|3] "" XXX
 SG_ CF_AVN_NFCCard1NValueSet : 12|4@1+ (1,0) [0|15] "" XXX
 SG_ CF_AVN_OwnerPhoneNValueSet2 : 16|6@1+ (1,0) [0|63] "" XXX
 SG_ CF_AVN_DigitalKeyMenuExit : 22|2@1+ (1,0) [0|3] "" XXX
 SG_ C_AVN_DigitalKeyProfileNvalSet : 24|13@1+ (1,0) [0|8191] "" XXX
 SG_ CF_AVN_ValetDigitalKeyReset : 37|3@1+ (1,0) [0|7] "" XXX

BO_ 1221 HU_GW_E: 8 XXX
 SG_ SWRC_Sensitivity_SET : 2|9@1+ (1,0) [0|511] "" XXX
 SG_ MODE_ENG_SET : 5|3@1+ (1,0) [0|7] "" XXX
 SG_ SHIFT_IND_N_Mode_SET : 8|2@1+ (1,0) [0|3] "" XXX
 SG_ MODE_REV_SET : 10|3@1+ (1,0) [0|7] "" XXX
 SG_ HU_ChgInCurrModSet : 11|11@1+ (1,0) [0|2047] "" XXX
 SG_ MODE_MDPS_SET : 13|5@1+ (1,0) [0|31] "" XXX
 SG_ MODE_ELSD_SET : 18|3@1+ (1,0) [0|7] "" XXX
 SG_ MODE_4WD_SET : 21|5@1+ (1,0) [0|31] "" XXX
 SG_ HU_EV_WinterMode : 22|10@1+ (1,0) [0|1023] "" XXX
 SG_ MODE_ESND_SET : 26|3@1+ (1,0) [0|7] "" XXX
 SG_ MODE_ESC_SET : 29|5@1+ (1,0) [0|31] "" XXX
 SG_ HU_TgSoc_ScChg_Set : 32|8@1+ (1,0) [0|255] "" XXX
 SG_ MODE_VCU_SET : 34|6@1+ (1,0) [0|63] "" XXX
 SG_ MODE_TM_SET : 40|8@1+ (1,0) [0|255] "" XXX
 SG_ SHIFT_IND_Custom_Mode_SET : 48|2@1+ (1,0) [0|3] "" XXX
 SG_ SHIFT_IND_Sport_Mode_SET : 50|2@1+ (1,0) [0|3] "" XXX
 SG_ SHIFT_IND_Normal_Mode_SET : 52|2@1+ (1,0) [0|3] "" XXX
 SG_ SHIFT_IND_Eco_Mode_SET : 54|8@1+ (1,0) [0|255] "" XXX
 SG_ HU_UserApproval : 56|4@1+ (1,0) [0|15] "" XXX
 SG_ HU_OtaInfomationReq : 60|4@1+ (1,0) [0|15] "" XXX
 SG_ SHIFT_IND_BeepSound_SET : 62|2@1+ (1,0) [0|3] "" XXX

BO_ 1223 HU_GW_E_03_MODE_DECSEN: 8 XXX
 SG_ PushFeel_SET : 14|2@1+ (1,0) [0|3] "" XXX
 SG_ N_ADAPTIVE_SHIFT_SET : 16|18@1+ (1,0) [0|262143] "" XXX
 SG_ MODE_BRAKE_SET : 34|3@1+ (1,0) [0|7] "" XXX
 SG_ MODE_PRFL_SET : 37|6@1+ (1,0) [0|63] "" XXX
 SG_ LaunchControl_RPM_SET : 43|13@1+ (1,0) [0|8191] "" XXX
 SG_ TRANS_CREEP_START_SET : 56|2@1+ (1,0) [0|3] "" XXX
 SG_ SHIFT_IND_RPM_SET : 58|6@1+ (1,0) [0|63] "" XXX

BO_ 1224 HU_TMU_E: 8 XXX
 SG_ HU_eCallStatus : 19|5@1+ (1,0) [0|31] "" XXX
 SG_ C_SHVU_DTC_Mode : 26|6@1+ (1,0) [0|63] "" XXX
 SG_ HU_TempUnit : 36|4@1+ (1,0) [0|15] "" XXX

BO_ 1227 PSM_01_00ms: 8 XXX
 SG_ DrvIMS_MemoryP1Req : 0|2@1+ (1,0) [0|3] "" XXX
 SG_ DrvIMS_MemoryP2Req : 2|2@1+ (1,0) [0|3] "" XXX
 SG_ DrvIMS_MemoryP3Req : 4|2@1+ (1,0) [0|3] "" XXX
 SG_ DrvIMS_MemorySetEnaSta : 6|2@1+ (1,0) [0|3] "" XXX
 SG_ DrvIMS_PlyBckP1Req : 8|2@1+ (1,0) [0|3] "" XXX
 SG_ DrvIMS_PlyBckP2Req : 10|2@1+ (1,0) [0|3] "" XXX
 SG_ DrvIMS_PlyBckP3Req : 12|2@1+ (1,0) [0|3] "" XXX
 SG_ DrvIMS_PlyBckStpReq : 14|2@1+ (1,0) [0|3] "" XXX
 SG_ SmrtIMS_PlyBckReq : 16|16@1+ (1,0) [0|65535] "" XXX
 SG_ SmrtIMS_ImgDBVal : 32|5@1+ (1,0) [0|31] "" XXX
 SG_ SmrtIMS_PlyBckStpReq : 37|3@1+ (1,0) [0|7] "" XXX
 SG_ SmrtIMS_EnterSwSta : 40|2@1+ (1,0) [0|3] "" XXX
 SG_ DrvIMS_BzrReq : 42|4@1+ (1,0) [0|15] "" XXX
 SG_ DrvIMS_ErrConWmgDis : 46|2@1+ (1,0) [0|3] "" XXX
 SG_ PSM_DrvRlxReturn_Req : 48|3@1+ (1,0) [0|7] "" XXX
 SG_ Drv_AutoRlxWrngDis : 51|3@1+ (1,0) [0|7] "" XXX
 SG_ DrvIMS_AMPBzrReq : 54|2@1+ (1,0) [0|3] "" XXX

BO_ 1229 HU_AVM_E: 8 XXX
 SG_ HU_SVM_SelectedMenu_New : 8|24@1+ (1,0) [0|16777215] "" XXX
 SG_ SVM_CaptureModeVideoRequest : 32|2@1+ (1,0) [0|3] "" XXX
 SG_ SVM_CaptureModeViewRequest : 34|6@1+ (1,0) [0|63] "" XXX

BO_ 1230 HU_CLU_PE: 8 XXX
 SG_ HU_Frequency_New : 51|5@1+ (1,0) [0|31] "" XXX

BO_ 1239 HU_Car_PE: 8 XXX
 SG_ HU_VehiclePwr : 4|4@1+ (1,0) [0|15] "" XXX
 SG_ HU_BtnShowReq : 8|8@1+ (1,0) [0|255] "" XXX

BO_ 1240 HU_CLU_PE_06_HU_User: 8 XXX
 SG_ DISTANCE_UNIT : 0|1@1+ (1,0) [0|1] "" XXX
 SG_ AVN_PDW_Input : 49|2@1+ (1,0) [0|3] "" XXX
 SG_ AVN_RSPA_Input : 51|5@1+ (1,0) [0|31] "" XXX

BO_ 1241 HU_AVM_E: 8 XXX
 SG_ HU_AVM_Cal_Cmd : 4|4@1+ (1,0) [0|15] "" XXX
 SG_ HU_AVM_PT_X : 8|12@1+ (1,0) [0|4095] "" XXX
 SG_ HU_AVM_SelectedZoom : 20|4@1+ (1,0) [0|15] "" XXX
 SG_ HU_AVM_PT_Y : 24|17@1+ (1,0) [0|131071] "" XXX
 SG_ HU_AVM_CameraOff : 41|7@1+ (1,0) [0|127] "" XXX
 SG_ HU_AVM_Option2 : 48|4@1+ (1,0) [0|15] "" XXX
 SG_ HU_AVM_Option : 52|4@1+ (1,0) [0|15] "" XXX

BO_ 1244 HU_NAVI_V2_3_PROSHORT_SUB_E: 8 XXX
 SG_ PROSHORT_SUB_V2_3_Offset : 0|13@1+ (1,0) [0|8191] "" XXX
 SG_ PROSHORT_SUB_V2_3_PathIndex : 13|10@1+ (1,0) [0|1023] "" XXX
 SG_ PROSHORT_SUB_V2_3_Distance : 23|10@1+ (1,0) [0|1023] "" XXX
 SG_ PROSHORT_SUB_V2_3_Value0 : 33|10@1+ (1,0) [0|1023] "" XXX
 SG_ PROSHORT_SUB_V2_3_Value1 : 43|10@1+ (1,0) [0|1023] "" XXX
 SG_ PROSHORT_SUB_V2_3_ProfileType : 53|5@1+ (1,0) [0|31] "" XXX
 SG_ PROSHORT_SUB_V2_3_CyclicCounter : 58|3@1+ (1,0) [0|7] "" XXX
 SG_ PROSHORT_SUB_V2_3_Accuracy : 61|3@1+ (1,0) [0|7] "" XXX

BO_ 1245 AMP_HU_E_08_AMP_CLUinfo_OutputCh: 8 XXX
 SG_ HU_EV_GpsSched_State : 26|6@1+ (1,0) [0|63] "" XXX
 SG_ HU_LatchHoldReq_EV_PE : 34|6@1+ (1,0) [0|63] "" XXX

BO_ 1246 HU_NAVI_V2_3_PROLONG_SUB_E: 8 XXX
 SG_ PROLONG_SUB_V2_3_Value : 0|32@1+ (1,0) [0|4294967295] "" XXX
 SG_ PROLONG_SUB_V2_3_Offset : 32|16@1+ (1,0) [0|65535] "" XXX
 SG_ PROLONG_SUB_V2_3_PathIndex : 48|6@1+ (1,0) [0|63] "" XXX
 SG_ PROLONG_SUB_V2_3_ProfileType : 54|5@1+ (1,0) [0|31] "" XXX
 SG_ PROLONG_SUB_V2_3_CyclicCounter : 59|3@1+ (1,0) [0|7] "" XXX
 SG_ PROLONG_SUB_V2_3_Update : 62|2@1+ (1,0) [0|3] "" XXX

BO_ 1247 HU_NAVI_PE: 8 XXX
 SG_ Navi_AirConditionWarning : 18|6@1+ (1,0) [0|63] "" XXX
 SG_ Navi_AirConditionType : 24|8@1+ (1,0) [0|255] "" XXX

BO_ 1253 IEB_01_10ms_2_IEB_InhbtTrnstnTo4wd: 8 XXX
 SG_ Auth_Req : 35|23@1+ (1,0) [0|8388607] "" XXX
 SG_ SecureCom_Req : 58|6@1+ (1,0) [0|63] "" XXX

BO_ 1257 HU_GW_P: 8 XXX
 SG_ CF_Tmu_RoadType2 : 0|4@1+ (1,0) [0|15] "" XXX
 SG_ CF_Tmu_RoadType1 : 4|20@1+ (1,0) [0|1048575] "" XXX
 SG_ CF_Tmu_RoadType4 : 24|4@1+ (1,0) [0|15] "" XXX
 SG_ CF_Tmu_RoadType3 : 28|24@1+ (1,0) [0|16777215] "" XXX
 SG_ CF_Tmu_RoadType5 : 52|4@1+ (1,0) [0|15] "" XXX

BO_ 1258 HU_GW_P: 8 XXX
 SG_ CF_Tmu_RoadType7 : 0|4@1+ (1,0) [0|15] "" XXX
 SG_ CF_Tmu_RoadType6 : 4|20@1+ (1,0) [0|1048575] "" XXX
 SG_ CF_Tmu_RoadType9 : 24|4@1+ (1,0) [0|15] "" XXX
 SG_ CF_Tmu_RoadType8 : 28|24@1+ (1,0) [0|16777215] "" XXX
 SG_ CF_Tmu_RoadType10 : 52|4@1+ (1,0) [0|15] "" XXX

BO_ 1259 HU_GW_P: 8 XXX
 SG_ CF_Tmu_Cur_Sun : 0|1@1+ (1,0) [0|1] "" XXX
 SG_ CF_Tmu_Cur_Sat : 1|1@1+ (1,0) [0|1] "" XXX
 SG_ CF_Tmu_Cur_Fri : 2|1@1+ (1,0) [0|1] "" XXX
 SG_ CF_Tmu_Cur_Thu : 3|1@1+ (1,0) [0|1] "" XXX
 SG_ CF_Tmu_Cur_Wed : 4|1@1+ (1,0) [0|1] "" XXX
 SG_ CF_Tmu_Cur_Tue : 5|1@1+ (1,0) [0|1] "" XXX
 SG_ CF_Tmu_Cur_Mon : 6|5@1+ (1,0) [0|31] "" XXX
 SG_ CR_Tmu_Cur_Hour : 11|4@1+ (1,0) [0|15] "" XXX
 SG_ HOURS : 15|1@0+ (1,0) [0|1] "" XXX
 SG_ CR_Tmu_Cur_Min : 16|5@1+ (1,0) [0|31] "" XXX
 SG_ MINUTES : 21|3@0+ (1,0) [0|7] "" XXX
 SG_ CR_Tmu_Cur_Sec : 24|6@1+ (1,0) [0|63] "" XXX
 SG_ CF_Tmu_Rdy : 39|1@0+ (1,0) [0|1] "" XXX

BO_ 1260 HU_GW_P: 8 XXX
 SG_ CR_Tmu_DrvDistance1 : 0|10@1+ (1,0) [0|1023] "" XXX
 SG_ CR_Tmu_DrvDistance2 : 10|10@1+ (1,0) [0|1023] "" XXX
 SG_ CR_Tmu_DrvDistance3 : 20|10@1+ (1,0) [0|1023] "" XXX
 SG_ CR_Tmu_DrvDistance4 : 30|10@1+ (1,0) [0|1023] "" XXX
 SG_ CR_Tmu_DrvDistance5 : 40|10@1+ (1,0) [0|1023] "" XXX
 SG_ CR_Tmu_DrvDistance6 : 50|6@1+ (1,0) [0|63] "" XXX

BO_ 1261 HU_GW_P: 8 XXX
 SG_ CR_Tmu_DrvDistance7 : 0|10@1+ (1,0) [0|1023] "" XXX
 SG_ CR_Tmu_DrvDistance8 : 10|10@1+ (1,0) [0|1023] "" XXX
 SG_ CR_Tmu_DrvDistance9 : 20|10@1+ (1,0) [0|1023] "" XXX
 SG_ CR_Tmu_DrvDistance10 : 30|10@1+ (1,0) [0|1023] "" XXX
 SG_ NAVI_Battcond_RouteDis : 40|11@1+ (1,0) [0|2047] "" XXX
 SG_ NAVI_Battcond_RemainTime : 51|5@1+ (1,0) [0|31] "" XXX

BO_ 1262 HU_EV_P: 8 XXX
 SG_ CR_HU_EconStMin_WeedDay : 0|3@1+ (1,0) [0|7] "" XXX
 SG_ CR_HU_EconStHr_WeekDay : 3|5@1+ (1,0) [0|31] "" XXX
 SG_ CR_HU_EconEndMin_WeekDay : 8|3@1+ (1,0) [0|7] "" XXX
 SG_ CR_HU_EconEndHr_WeekDay : 11|27@1+ (1,0) [0|134217727] "" XXX
 SG_ CR_HU_ChgCtrMode : 38|2@1+ (1,0) [0|3] "" XXX

BO_ 1263 HU_EV_P: 8 XXX
 SG_ CR_HU_DepartSet1_Min : 0|3@1+ (1,0) [0|7] "" XXX
 SG_ CR_HU_DepartSet1_Hour : 3|5@1+ (1,0) [0|31] "" XXX
 SG_ CF_HU_DepartSet1_Enable : 8|1@1+ (1,0) [0|1] "" XXX
 SG_ CF_HU_DepartSet1_Sun : 9|1@1+ (1,0) [0|1] "" XXX
 SG_ CF_HU_DepartSet1_Sat : 10|1@1+ (1,0) [0|1] "" XXX
 SG_ CF_HU_DepartSet1_Fri : 11|1@1+ (1,0) [0|1] "" XXX
 SG_ CF_HU_DepartSet1_Thu : 12|1@1+ (1,0) [0|1] "" XXX
 SG_ CF_HU_DepartSet1_Wed : 13|1@1+ (1,0) [0|1] "" XXX
 SG_ CF_HU_DepartSet1_Tue : 14|1@1+ (1,0) [0|1] "" XXX
 SG_ CF_HU_DepartSet1_Mon : 15|1@1+ (1,0) [0|1] "" XXX
 SG_ CR_HU_DepartSet2_Min : 16|3@1+ (1,0) [0|7] "" XXX
 SG_ CR_HU_DepartSet2_Hour : 19|5@1+ (1,0) [0|31] "" XXX
 SG_ CF_HU_DepartSet2_Enable : 24|1@1+ (1,0) [0|1] "" XXX
 SG_ CF_HU_DepartSet2_Sun : 25|1@1+ (1,0) [0|1] "" XXX
 SG_ CF_HU_DepartSet2_Sat : 26|1@1+ (1,0) [0|1] "" XXX
 SG_ CF_HU_DepartSet2_Fri : 27|1@1+ (1,0) [0|1] "" XXX
 SG_ CF_HU_DepartSet2_Thu : 28|1@1+ (1,0) [0|1] "" XXX
 SG_ CF_HU_DepartSet2_Wed : 29|1@1+ (1,0) [0|1] "" XXX
 SG_ CF_HU_DepartSet2_Tue : 30|1@1+ (1,0) [0|1] "" XXX
 SG_ CF_HU_DepartSet2_Mon : 31|1@1+ (1,0) [0|1] "" XXX
 SG_ CF_HU_DepartSet1_TempUnit : 32|1@1+ (1,0) [0|1] "" XXX
 SG_ CR_HU_DepartSet1_TempSet : 33|6@1+ (1,0) [0|63] "" XXX
 SG_ CF_HU_DepartSet1_PreCondSet : 39|8@1+ (1,0) [0|255] "" XXX
 SG_ CF_HU_DepartSet1_DefrostCtr : 47|1@1+ (1,0) [0|1] "" XXX

BO_ 1264 HU_CLOCK_PE: 8 XXX
 SG_ HU_TimeSetting : 0|2@1+ (1,0) [0|3] "" XXX
 SG_ HU_Status : 2|4@1+ (1,0) [0|15] "" XXX
 SG_ HU_TimeFormat : 6|2@1+ (1,0) [0|3] "" XXX
 SG_ HU_DisplayHour : 8|4@1+ (1,0) [0|15] "" XXX
 SG_ HOURS : 12|4@0+ (1,0) [0|15] "" XXX
 SG_ HU_DisplayMinute : 16|5@1+ (1,0) [0|31] "" XXX
 SG_ MINUTES : 21|3@0+ (1,0) [0|7] "" XXX
 SG_ HU_DisplaySecond : 24|7@1+ (1,0) [0|127] "" XXX
 SG_ SECONDS : 31|3@0+ (1,0) [0|7] "" XXX
 SG_ HU_DisplayMonth : 34|4@1+ (1,0) [0|15] "" XXX
 SG_ HU_DisplayYear1 : 38|2@1+ (1,0) [0|3] "" XXX
 SG_ HU_DisplayYear2 : 40|8@1+ (1,0) [0|255] "" XXX
 SG_ HU_DisplayDay : 48|8@1+ (1,0) [0|255] "" XXX
 SG_ HU_AM_PM_INFO : 56|4@1+ (1,0) [0|15] "" XXX
 SG_ HU_ComRefresh : 60|2@1+ (1,0) [0|3] "" XXX
 SG_ HU_ClockInfo : 62|2@1+ (1,0) [0|3] "" XXX

BO_ 1265 HU_GW_PE: 8 XXX
 SG_ AMP_UpdateIGNIhn : 0|11@1+ (1,0) [0|2047] "" XXX
 SG_ HU_Background_Time_Info : 8|2@1+ (1,0) [0|3] "" XXX
 SG_ C_FRU_Option_Info : 10|6@1+ (1,0) [0|63] "" XXX
 SG_ HU_RrStRemindOffSetReq : 11|5@1+ (1,0) [0|31] "" XXX
 SG_ HU_IG3_Request : 12|6@1+ (1,0) [0|63] "" XXX
 SG_ HU_Background : 18|3@1+ (1,0) [0|7] "" XXX
 SG_ ccIC_HUD_PbackSta : 21|3@1+ (1,0) [0|7] "" XXX
 SG_ HU_BackgroundFadeInOut : 24|8@1+ (1,0) [0|255] "" XXX

BO_ 1266 HU_CLU_PE: 8 XXX
 SG_ HU_LanguageInfo : 0|8@1+ (1,0) [0|255] "" XXX
 SG_ HU_VolumeStatus : 8|6@1+ (1,0) [0|63] "" XXX
 SG_ HU_MuteStatus : 14|2@1+ (1,0) [0|3] "" XXX
 SG_ HU_WelcomeReady : 16|2@1+ (1,0) [0|3] "" XXX
 SG_ HU_UsmSupport : 18|2@1+ (1,0) [0|3] "" XXX
 SG_ HU_NaviStatus : 20|4@1+ (1,0) [0|15] "" XXX
 SG_ HU_BVM_Display_Message : 24|3@1+ (1,0) [0|7] "" XXX
 SG_ HU_SVM_View_Display : 27|5@1+ (1,0) [0|31] "" XXX
 SG_ HU_NaviCamSettingStatus : 32|8@1+ (1,0) [0|255] "" XXX
 SG_ HU_EVSupport : 40|14@1+ (1,0) [0|16383] "" XXX
 SG_ HU_AutoBrightState_New : 54|2@1+ (1,0) [0|3] "" XXX

BO_ 1267 DATC_08_200ms: 8 XXX
 SG_ RSELockOnOff_PE : 0|36@1+ (1,0) [0|68719476735] "" XXX
 SG_ HU_DATC_DisplayThemes : 14|2@1+ (1,0) [0|3] "" XXX
 SG_ DATC_AlvCnt8Val : 16|10@1+ (1,0) [0|1023] "" XXX
 SG_ DATC_SmrtVntOnOffSta : 26|2@1+ (1,0) [0|3] "" XXX
 SG_ DATC_PsAutoDis : 28|4@1+ (1,0) [0|15] "" XXX
 SG_ DATC_RrAutoDis : 32|8@1+ (1,0) [0|255] "" XXX
 SG_ HU_PhoneActivity_PE : 36|2@1+ (1,0) [0|3] "" XXX
 SG_ HU_VRActivity_PE : 38|2@1+ (1,0) [0|3] "" XXX
 SG_ DATC_RrDrvModDis : 40|10@1+ (1,0) [0|1023] "" XXX
 SG_ DATC_DisplayThemes : 50|6@1+ (1,0) [0|63] "" XXX
 SG_ DATC_AUTOStepPS : 56|3@1+ (1,0) [0|7] "" XXX
 SG_ DATC_AUTOStepRR : 59|5@1+ (1,0) [0|31] "" XXX

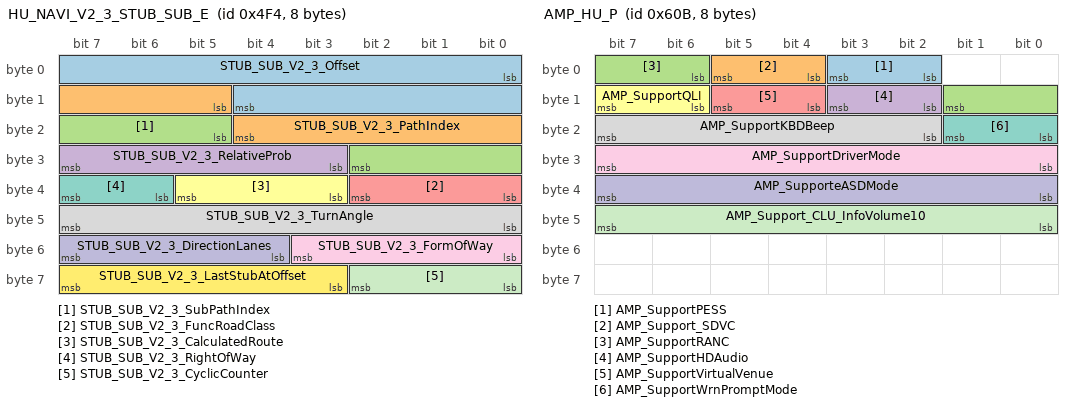
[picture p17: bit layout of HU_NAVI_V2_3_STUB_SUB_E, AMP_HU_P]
BO_ 1268 HU_NAVI_V2_3_STUB_SUB_E: 8 XXX
 SG_ STUB_SUB_V2_3_Offset : 0|13@1+ (1,0) [0|8191] "" XXX
 SG_ STUB_SUB_V2_3_PathIndex : 13|8@1+ (1,0) [0|255] "" XXX
 SG_ STUB_SUB_V2_3_SubPathIndex : 21|6@1+ (1,0) [0|63] "" XXX
 SG_ STUB_SUB_V2_3_RelativeProb : 27|5@1+ (1,0) [0|31] "" XXX
 SG_ STUB_SUB_V2_3_FuncRoadClass : 32|3@1+ (1,0) [0|7] "" XXX
 SG_ STUB_SUB_V2_3_CalculatedRoute : 35|3@1+ (1,0) [0|7] "" XXX
 SG_ STUB_SUB_V2_3_RightOfWay : 38|2@1+ (1,0) [0|3] "" XXX
 SG_ STUB_SUB_V2_3_TurnAngle : 40|8@1+ (1,0) [0|255] "" XXX
 SG_ STUB_SUB_V2_3_FormOfWay : 48|4@1+ (1,0) [0|15] "" XXX
 SG_ STUB_SUB_V2_3_DirectionLanes : 52|4@1+ (1,0) [0|15] "" XXX
 SG_ STUB_SUB_V2_3_CyclicCounter : 56|3@1+ (1,0) [0|7] "" XXX
 SG_ STUB_SUB_V2_3_LastStubAtOffset : 59|5@1+ (1,0) [0|31] "" XXX

BO_ 1278 HU_MON_PE: 8 XXX
 SG_ HU_Type : 0|8@1+ (1,0) [0|255] "" XXX
 SG_ HU_Navi_RspADASMapMsg : 8|16@1+ (1,0) [0|65535] "" XXX
 SG_ HU_DistributeInfo : 24|8@1+ (1,0) [0|255] "" XXX
 SG_ HU_OptionInfo : 32|22@1+ (1,0) [0|4194303] "" XXX
 SG_ HU_NaviHandshakingSupport : 54|2@1+ (1,0) [0|3] "" XXX
 SG_ HU_AMP_EQVariant : 56|5@1+ (1,0) [0|31] "" XXX
 SG_ HU_AdasSupport : 61|3@1+ (1,0) [0|7] "" XXX

BO_ 1279 HU_USM_E12: 8 XXX
 SG_ HU_Display_New : 0|8@1+ (1,0) [0|255] "" XXX
 SG_ C_DrvLegDnSw_HU : 2|10@1+ (1,0) [0|1023] "" XXX
 SG_ C_EV_RegenLevel_Sport_Set : 3|3@1+ (1,0) [0|7] "" XXX
 SG_ C_EV_RegenLevel_Eco_Set : 6|3@1+ (1,0) [0|7] "" XXX
 SG_ USM_SmartRegen_Set : 9|39@1+ (1,0) [0|549755813887] "" XXX
 SG_ USM_SmartRegen_Map_Set : 11|2@1+ (1,0) [0|3] "" XXX
 SG_ C_DrvHeightUpSw_HU : 12|2@1+ (1,0) [0|3] "" XXX
 SG_ USM_SmartRegen_Sens_Set : 13|3@1+ (1,0) [0|7] "" XXX
 SG_ C_DrvHeightDnSw_HU : 14|2@1+ (1,0) [0|3] "" XXX
 SG_ C_DrvTiltUpSw_HU : 16|2@1+ (1,0) [0|3] "" XXX
 SG_ C_EsyAcsProfileID_HU : 18|0@1+ (1,0) [0|0] "" XXX
 SG_ AVN_SeatPosPlyBck_Btn : 19|3@1+ (1,0) [0|7] "" XXX
 SG_ C_DrvRlxTiltUpSw_HU : 20|2@1+ (1,0) [0|3] "" XXX
 SG_ USM_RhstaLvlEnaSetReq : 22|2@1+ (1,0) [0|3] "" XXX
 SG_ USM_CMSDayBrgtnsLvlLHSetReq : 24|4@1+ (1,0) [0|15] "" XXX
 SG_ C_DrvHrestDnSw_HU : 26|2@1+ (1,0) [0|3] "" XXX
 SG_ USM_CMSNgtBrgtnsLvlLHSetReq : 28|4@1+ (1,0) [0|15] "" XXX
 SG_ C_DrvHrestBwdSw_HU : 30|2@1+ (1,0) [0|3] "" XXX
 SG_ USM_CMSDayBrgtnsLvlRHSetReq : 32|4@1+ (1,0) [0|15] "" XXX
 SG_ C_DrvLumbarMidSw_HU : 34|2@1+ (1,0) [0|3] "" XXX
 SG_ USM_CMSNgtBrgtnsLvlRHSetReq : 36|4@1+ (1,0) [0|15] "" XXX
 SG_ C_DrvLumbarDefSw_HU : 38|2@1+ (1,0) [0|3] "" XXX
 SG_ USM_CMSBrgtnsReset : 40|2@1+ (1,0) [0|3] "" XXX
 SG_ USM_TurnDistLnDispSetReq : 42|2@1+ (1,0) [0|3] "" XXX
 SG_ PCA_FrSd_NValueSet : 44|2@1+ (1,0) [0|3] "" XXX
 SG_ C_DrvCushDefSw_HU : 46|2@1+ (1,0) [0|3] "" XXX
 SG_ HU_TgSoc_GPSChg_Set : 48|8@1+ (1,0) [0|255] "" XXX
 SG_ C_DrvCushExtBwdSw_HU : 50|6@1+ (1,0) [0|63] "" XXX
 SG_ VESS_ChgGuideMdLvl : 57|7@1+ (1,0) [0|127] "" XXX

BO_ 1538 AMP_HU_E: 8 XXX
 SG_ AMP_MTSVolumeState : 0|8@1+ (1,0) [0|255] "" XXX
 SG_ DVRS_BeepVolumeState : 8|8@1+ (1,0) [0|255] "" XXX
 SG_ DVRS_Beep_OutputCh_State : 16|16@1+ (1,0) [0|65535] "" XXX
 SG_ DVRS_BeepFrequencyState : 32|8@1+ (1,0) [0|255] "" XXX

BO_ 1539 AMP_HU_E: 8 XXX
 SG_ AMP_HFVolumeState : 0|8@1+ (1,0) [0|255] "" XXX
 SG_ ATS_BeepVolumeState : 8|8@1+ (1,0) [0|255] "" XXX
 SG_ ATS_Beep_OutputCh_State : 16|16@1+ (1,0) [0|65535] "" XXX
 SG_ ATS_BeepFrequencyState : 32|8@1+ (1,0) [0|255] "" XXX

BO_ 1540 AMP_HU_E: 8 XXX
 SG_ AMP_MaxVolumeStep : 0|8@1+ (1,0) [0|255] "" XXX
 SG_ AMP_MaxBalanceStep : 8|8@1+ (1,0) [0|255] "" XXX
 SG_ AMP_MaxFadeStep : 16|8@1+ (1,0) [0|255] "" XXX
 SG_ AMP_MaxBassStep : 24|8@1+ (1,0) [0|255] "" XXX
 SG_ AMP_MaxMidStep : 32|8@1+ (1,0) [0|255] "" XXX
 SG_ AMP_MaxTrebleStep : 40|8@1+ (1,0) [0|255] "" XXX

BO_ 1542 AMP_HU_E: 8 XXX
 SG_ AMP_MaxBeep1VolumeState : 0|8@1+ (1,0) [0|255] "" XXX
 SG_ AMP_Beep1FrequencyState : 8|16@1+ (1,0) [0|65535] "" XXX
 SG_ AMP_CLU_InfoVolumeState : 24|8@1+ (1,0) [0|255] "" XXX
 SG_ AMP_CLUinfo_OutputCh_State : 32|8@1+ (1,0) [0|255] "" XXX

BO_ 1543 AMP_HU_E_08_AMP_CLUinfo: 8 XXX
 SG_ AMP_WalkieTalkie_OutputCh_State : 8|8@1+ (1,0) [0|255] "" XXX

BO_ 1545 AMP_HU_E: 8 XXX
 SG_ AMP_Beep1VolumeState : 0|8@1+ (1,0) [0|255] "" XXX
 SG_ AMP_SPDIF_OutputCh_State : 8|16@1+ (1,0) [0|65535] "" XXX
 SG_ AMP_Analog_OutputCh_State : 24|16@1+ (1,0) [0|65535] "" XXX
 SG_ AMP_Beep1_OutputCh_State : 40|16@1+ (1,0) [0|65535] "" XXX
 SG_ AMP_Beep1KBDVolumeState : 56|8@1+ (1,0) [0|255] "" XXX

BO_ 1546 AMP_HU_P: 8 XXX
 SG_ AMP_SupportBeepVolumeControl : 0|18@1+ (1,0) [0|262143] "" XXX
 SG_ AMP_SupportESEVMode : 18|4@1+ (1,0) [0|15] "" XXX
 SG_ AMP_SupportANCMode : 22|10@1+ (1,0) [0|1023] "" XXX
 SG_ AMP_MakerID : 32|8@1+ (1,0) [0|255] "" XXX
 SG_ AMP_SupportQLS : 40|6@1+ (1,0) [0|63] "" XXX
 SG_ AMP_SupportASDMode : 46|8@1+ (1,0) [0|255] "" XXX
 SG_ AMP_SupportSignalDoctor : 54|8@1+ (1,0) [0|255] "" XXX
 SG_ AMP_Support_ElecSound : 62|2@1+ (1,0) [0|3] "" XXX

BO_ 1547 AMP_HU_P: 8 XXX
 SG_ AMP_SupportPESS : 2|2@1+ (1,0) [0|3] "" XXX
 SG_ AMP_Support_SDVC : 4|2@1+ (1,0) [0|3] "" XXX
 SG_ AMP_SupportRANC : 6|4@1+ (1,0) [0|15] "" XXX
 SG_ AMP_SupportHDAudio : 10|2@1+ (1,0) [0|3] "" XXX
 SG_ AMP_SupportVirtualVenue : 12|2@1+ (1,0) [0|3] "" XXX
 SG_ AMP_SupportQLI : 14|2@1+ (1,0) [0|3] "" XXX
 SG_ AMP_SupportWrnPromptMode : 16|2@1+ (1,0) [0|3] "" XXX
 SG_ AMP_SupportKBDBeep : 18|6@1+ (1,0) [0|63] "" XXX
 SG_ AMP_SupportDriverMode : 24|8@1+ (1,0) [0|255] "" XXX
 SG_ AMP_SupporteASDMode : 32|8@1+ (1,0) [0|255] "" XXX
 SG_ AMP_Support_CLU_InfoVolume10 : 40|8@1+ (1,0) [0|255] "" XXX

BO_ 1548 AMP_HU_PE: 8 XXX
 SG_ AMP_ASDModeState : 1|3@1+ (1,0) [0|7] "" XXX
 SG_ HU_InitInfo : 4|2@1+ (1,0) [0|3] "" XXX
 SG_ AMP_TTSModeState : 6|3@1+ (1,0) [0|7] "" XXX
 SG_ AMP_StartUpComplete : 9|2@1+ (1,0) [0|3] "" XXX
 SG_ AMP_SPDIFInfo : 11|3@1+ (1,0) [0|7] "" XXX
 SG_ AMP_NaviModeState : 14|2@1+ (1,0) [0|3] "" XXX
 SG_ AMP_EngASDMasterGainState : 16|10@1+ (1,0) [0|1023] "" XXX
 SG_ AMP_SDVCStepState : 26|10@1+ (1,0) [0|1023] "" XXX
 SG_ AMP_Beep1KBDModeState : 36|2@1+ (1,0) [0|3] "" XXX
 SG_ AMP_Beep1ModeState : 38|5@1+ (1,0) [0|31] "" XXX
 SG_ AMP_MasterBeepVolumeState : 43|3@1+ (1,0) [0|7] "" XXX
 SG_ AMP_ANCModeState : 46|2@1+ (1,0) [0|3] "" XXX
 SG_ AMP_DistrInfoState : 48|12@1+ (1,0) [0|4095] "" XXX
 SG_ AMP_SignalDoctorState : 60|2@1+ (1,0) [0|3] "" XXX
 SG_ AMP_INFORM_TO_IPM : 62|2@1+ (1,0) [0|3] "" XXX

BO_ 1549 AMP_HU_PE: 8 XXX
 SG_ AMP_VirtualVenueModeStatus : 0|3@1+ (1,0) [0|7] "" XXX
 SG_ AMP_QLIModeStatus : 3|3@1+ (1,0) [0|7] "" XXX
 SG_ AMP_MuteState : 6|2@1+ (1,0) [0|3] "" XXX
 SG_ AMP_LogSnapshotState : 8|2@1+ (1,0) [0|3] "" XXX
 SG_ AMP_EQState : 10|2@1+ (1,0) [0|3] "" XXX
 SG_ AMP_DriverModeStatus : 12|4@1+ (1,0) [0|15] "" XXX
 SG_ AMP_WrnPromptModeSta : 16|4@1+ (1,0) [0|15] "" XXX
 SG_ AMP_ESEVwarning : 20|2@1+ (1,0) [0|3] "" XXX
 SG_ AMP_SPDIFMuteSt : 22|2@1+ (1,0) [0|3] "" XXX
 SG_ AMP_RANCwarning : 24|3@1+ (1,0) [0|7] "" XXX
 SG_ AMP_RANCstate : 27|5@1+ (1,0) [0|31] "" XXX
 SG_ AMP_AudioSource : 32|8@1+ (1,0) [0|255] "" XXX
 SG_ AMP_QuietModeState : 40|2@1+ (1,0) [0|3] "" XXX
 SG_ AMP_CabinTalkModeState : 42|2@1+ (1,0) [0|3] "" XXX
 SG_ AMP_QLSModeState : 44|9@1+ (1,0) [0|511] "" XXX
 SG_ AMP_VoiceGuideTTSLevelStatus : 53|5@1+ (1,0) [0|31] "" XXX
 SG_ AMP_VoiceGuideTTSStatus : 58|6@1+ (1,0) [0|63] "" XXX

BO_ 1550 AMP_HU_PE: 8 XXX
 SG_ AMP_MainVolumeSetting : 0|8@1+ (1,0) [0|255] "" XXX
 SG_ AMP_BalanceSetting : 8|8@1+ (1,0) [0|255] "" XXX
 SG_ AMP_FadeSetting : 16|8@1+ (1,0) [0|255] "" XXX
 SG_ AMP_BassSetting : 24|8@1+ (1,0) [0|255] "" XXX
 SG_ AMP_MidSetting : 32|8@1+ (1,0) [0|255] "" XXX
 SG_ AMP_TrebleSetting : 40|8@1+ (1,0) [0|255] "" XXX
 SG_ AMP_ESEVModeState : 48|3@1+ (1,0) [0|7] "" XXX
 SG_ AMP_ESEVMasterGainState : 51|5@1+ (1,0) [0|31] "" XXX

BO_ 1551 AMP_HU_PE: 8 XXX
 SG_ AMP_PESSAPSSetting : 0|3@1+ (1,0) [0|7] "" XXX
 SG_ AMP_PESSDesignSetting : 3|3@1+ (1,0) [0|7] "" XXX
 SG_ AMP_PESSModeState : 6|2@1+ (1,0) [0|3] "" XXX
 SG_ AMP_PESSVolumeSetting : 8|8@1+ (1,0) [0|255] "" XXX
 SG_ AMP_PESSDesignSetting_New : 16|4@1+ (1,0) [0|15] "" XXX
 SG_ AMP_PESSCANSetting : 20|4@1+ (1,0) [0|15] "" XXX
 SG_ AMP_eASDCstVolumeState : 24|5@1+ (1,0) [0|31] "" XXX
 SG_ AMP_eASDModeState : 29|3@1+ (1,0) [0|7] "" XXX
 SG_ AMP_eASDSEngVolumeSetting : 32|5@1+ (1,0) [0|31] "" XXX
 SG_ AMP_eASDEMotVolumeSetting : 37|5@1+ (1,0) [0|31] "" XXX
 SG_ AMP_eASDAPSState : 42|2@1+ (1,0) [0|3] "" XXX
 SG_ AMP_eASDSEngAPSState : 44|2@1+ (1,0) [0|3] "" XXX
 SG_ AMP_eASDEMotAPSState : 46|2@1+ (1,0) [0|3] "" XXX
 SG_ AMP_eASDCstModeState : 48|8@1+ (1,0) [0|255] "" XXX
 SG_ AMP_ADASVolumeState : 56|8@1+ (1,0) [0|255] "" XXX

BO_ 1552 AMP_HU_PE: 8 XXX
 SG_ AMP_EngOrderC2Setting : 0|8@1+ (1,0) [0|255] "" XXX
 SG_ AMP_EngOrderC4Setting : 8|8@1+ (1,0) [0|255] "" XXX
 SG_ AMP_EngOrderC6Setting : 16|8@1+ (1,0) [0|255] "" XXX
 SG_ AMP_ToneScapeXSetting : 24|8@1+ (1,0) [0|255] "" XXX
 SG_ AMP_ToneScapeYSetting : 32|8@1+ (1,0) [0|255] "" XXX
 SG_ AMP_ToneScapeZSetting : 40|8@1+ (1,0) [0|255] "" XXX
 SG_ AMP_SiriModeState : 48|2@1+ (1,0) [0|3] "" XXX
 SG_ AMP_SiriVolumeState : 50|6@1+ (1,0) [0|63] "" XXX

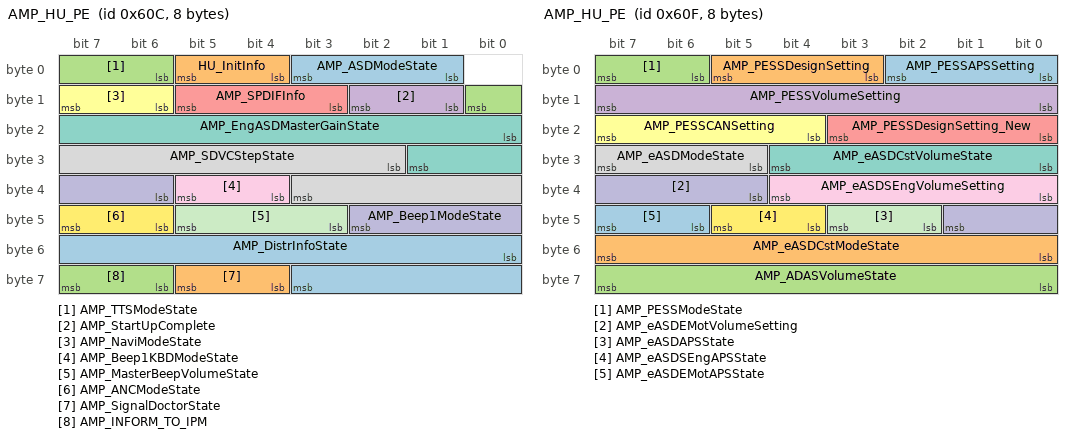
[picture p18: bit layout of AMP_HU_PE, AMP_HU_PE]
BO_ 1553 AMP_HU_PE: 8 XXX
 SG_ AMP_Binary1Ver : 0|8@1+ (1,0) [0|255] "" XXX
 SG_ AMP_Binary2Ver : 8|8@1+ (1,0) [0|255] "" XXX
 SG_ AMP_Binary3Ver : 16|8@1+ (1,0) [0|255] "" XXX
 SG_ AMP_Binary4Ver : 24|8@1+ (1,0) [0|255] "" XXX
 SG_ AMP_Binary5Ver : 32|8@1+ (1,0) [0|255] "" XXX
 SG_ AMP_Binary6Ver : 40|8@1+ (1,0) [0|255] "" XXX

BO_ 1554 AMP_HU_E: 8 XXX
 SG_ AMP_NaviVoice_PriorityState : 10|6@1+ (1,0) [0|63] "" XXX
 SG_ AMP_MajorVer : 16|8@1+ (1,0) [0|255] "" XXX
 SG_ AMP_MinorVer : 24|24@1+ (1,0) [0|16777215] "" XXX
 SG_ AMP_TuningMajorVer : 48|8@1+ (1,0) [0|255] "" XXX
 SG_ AMP_TuningMinorVer : 56|8@1+ (1,0) [0|255] "" XXX

BO_ 1555 AMP_HU_E: 8 XXX
 SG_ AMP_NaviVolumeState : 0|8@1+ (1,0) [0|255] "" XXX
 SG_ DATC_Beep1VolumeState : 8|8@1+ (1,0) [0|255] "" XXX
 SG_ DATC_Beep1_OutputCh_State : 16|16@1+ (1,0) [0|65535] "" XXX
 SG_ DATC_Beep1FrequencyState : 32|8@1+ (1,0) [0|255] "" XXX

BO_ 1584 HU_AMP_E: 8 XXX
 SG_ AMP_RrTTSSound : 2|2@1+ (1,0) [0|3] "" XXX
 SG_ AMP_NaviSound : 4|2@1+ (1,0) [0|3] "" XXX
 SG_ AMP_TTSSound : 6|3@1+ (1,0) [0|7] "" XXX
 SG_ AMP_SDVCStep : 9|5@1+ (1,0) [0|31] "" XXX
 SG_ AMP_Beep1Mode : 14|2@1+ (1,0) [0|3] "" XXX
 SG_ AMP_MasterBeepVolumeStep : 16|3@1+ (1,0) [0|7] "" XXX
 SG_ AMP_SignalDoctor : 19|2@1+ (1,0) [0|3] "" XXX
 SG_ AMP_ASDMode : 21|4@1+ (1,0) [0|15] "" XXX
 SG_ AMP_ANCMode : 25|7@1+ (1,0) [0|127] "" XXX
 SG_ AMP_VirtualVenueMode : 32|3@1+ (1,0) [0|7] "" XXX
 SG_ AMP_QLIMode : 35|3@1+ (1,0) [0|7] "" XXX
 SG_ AMP_DriverMode : 38|6@1+ (1,0) [0|63] "" XXX
 SG_ AMP_VoiceGuideTTS : 44|2@1+ (1,0) [0|3] "" XXX
 SG_ AMP_Beep1KBDMode : 46|2@1+ (1,0) [0|3] "" XXX

BO_ 1585 HU_AMP_E: 8 XXX
 SG_ AMP_Mute : 6|2@1+ (1,0) [0|3] "" XXX
 SG_ AMP_AudioMode : 8|8@1+ (1,0) [0|255] "" XXX
 SG_ AMP_WrnPromptMode : 16|2@1+ (1,0) [0|3] "" XXX
 SG_ AMP_SPDIFMute : 18|2@1+ (1,0) [0|3] "" XXX
 SG_ AMP_Reset : 20|2@1+ (1,0) [0|3] "" XXX
 SG_ AMP_QuietMode : 22|2@1+ (1,0) [0|3] "" XXX
 SG_ AMP_DSCMode : 24|4@1+ (1,0) [0|15] "" XXX
 SG_ AMP_RANCMode : 28|4@1+ (1,0) [0|15] "" XXX
 SG_ AMP_CenterpointMode : 32|2@1+ (1,0) [0|3] "" XXX
 SG_ AMP_QLSMode : 34|14@1+ (1,0) [0|16383] "" XXX
 SG_ AMP_SiriMode : 48|8@1+ (1,0) [0|255] "" XXX

BO_ 1586 HU_AMP_E: 8 XXX
 SG_ AMP_LogSnapshot : 0|2@1+ (1,0) [0|3] "" XXX
 SG_ VESS_LogSnapshot : 2|20@1+ (1,0) [0|1048575] "" XXX
 SG_ AMP_VersionReq : 22|2@1+ (1,0) [0|3] "" XXX

BO_ 1587 HU_AMP_E: 8 XXX
 SG_ AMP_EngASDMasterGain : 0|8@1+ (1,0) [0|255] "" XXX
 SG_ AMP_Beep1Frequency : 8|8@1+ (1,0) [0|255] "" XXX

BO_ 1588 HU_AMP_E: 8 XXX
 SG_ AMP_NaviVolumeStep : 0|8@1+ (1,0) [0|255] "" XXX
 SG_ ATS_Beep_OutputCh_Select : 8|16@1+ (1,0) [0|65535] "" XXX
 SG_ ATS_BeepVolumeStep : 24|8@1+ (1,0) [0|255] "" XXX
 SG_ ATS_BeepFrequency : 32|17@1+ (1,0) [0|131071] "" XXX
 SG_ AMP_ESEVMasterGain : 49|5@1+ (1,0) [0|31] "" XXX
 SG_ AMP_NaviVoice_Priority : 54|2@1+ (1,0) [0|3] "" XXX
 SG_ AMP_ESEVMode : 56|8@1+ (1,0) [0|255] "" XXX

BO_ 1589 HU_AMP_E: 8 XXX
 SG_ AMP_MTSVolumeStep : 0|8@1+ (1,0) [0|255] "" XXX
 SG_ AMP_eASDMode : 8|3@1+ (1,0) [0|7] "" XXX
 SG_ AMP_eASDCstVolumeSet : 11|15@1+ (1,0) [0|32767] "" XXX
 SG_ AMP_eASDAPSSet : 26|6@1+ (1,0) [0|63] "" XXX
 SG_ AMP_eASDCstMode : 32|5@1+ (1,0) [0|31] "" XXX
 SG_ AMP_eASDCstReset : 37|3@1+ (1,0) [0|7] "" XXX

BO_ 1590 HU_AMP_E: 8 XXX
 SG_ AMP_HFVolumeStep : 0|8@1+ (1,0) [0|255] "" XXX
 SG_ DVRS_Beep_OutputCh_Select : 8|16@1+ (1,0) [0|65535] "" XXX
 SG_ DVRS_BeepVolumeStep : 24|8@1+ (1,0) [0|255] "" XXX
 SG_ DVRS_BeepFrequency : 32|16@1+ (1,0) [0|65535] "" XXX
 SG_ AMP_SiriVolumeStep : 48|8@1+ (1,0) [0|255] "" XXX

BO_ 1591 HU_AMP_E: 8 XXX
 SG_ AMP_MainVolumeSet : 0|8@1+ (1,0) [0|255] "" XXX
 SG_ AMP_BalanceSet : 8|8@1+ (1,0) [0|255] "" XXX
 SG_ AMP_FadeSet : 16|8@1+ (1,0) [0|255] "" XXX
 SG_ AMP_BassSet : 24|8@1+ (1,0) [0|255] "" XXX
 SG_ AMP_MidSet : 32|8@1+ (1,0) [0|255] "" XXX
 SG_ AMP_TrebleSet : 40|8@1+ (1,0) [0|255] "" XXX

BO_ 1593 HU_AMP_E: 8 XXX
 SG_ DATC_Beep1_OutputCh_Select : 8|16@1+ (1,0) [0|65535] "" XXX
 SG_ DATC_Beep1VolumeStep : 24|8@1+ (1,0) [0|255] "" XXX
 SG_ DATC_Beep1Frequency : 32|8@1+ (1,0) [0|255] "" XXX

BO_ 1595 HU_AMP_E: 8 XXX
 SG_ AMP_CLU_InfoVolumeStep : 24|8@1+ (1,0) [0|255] "" XXX
 SG_ AMP_CLUinfo_OutputCh_Select : 32|8@1+ (1,0) [0|255] "" XXX

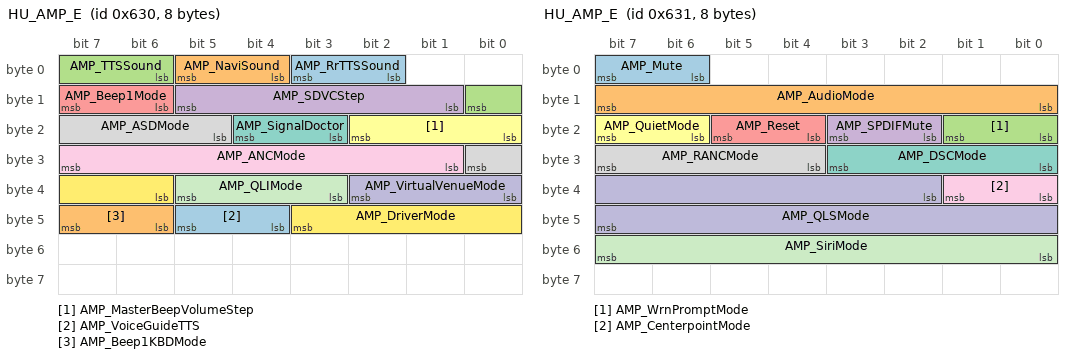
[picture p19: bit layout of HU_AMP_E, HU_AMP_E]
BO_ 1596 HU_AMP_E: 8 XXX
 SG_ AMP_ToneScapeX : 8|8@1+ (1,0) [0|255] "" XXX
 SG_ AMP_ToneScapeY : 16|8@1+ (1,0) [0|255] "" XXX
 SG_ AMP_ToneScapeZ : 24|8@1+ (1,0) [0|255] "" XXX
 SG_ AMP_MasterBeepVolumeLevel : 32|8@1+ (1,0) [0|255] "" XXX

BO_ 1597 HU_AMP_P: 8 XXX
 SG_ AMP_SetMaxMainVolStep : 14|2@1+ (1,0) [0|3] "" XXX

BO_ 1712 TP_AMP_HU_Dev_Res: 8 XXX
 SG_ Byte0_TCP_796 : 0|8@1+ (1,0) [0|255] "" XXX
 SG_ Byte1_Data_796 : 8|8@1+ (1,0) [0|255] "" XXX
 SG_ Byte2_Data_796 : 16|8@1+ (1,0) [0|255] "" XXX
 SG_ Byte3_Data_796 : 24|8@1+ (1,0) [0|255] "" XXX
 SG_ Byte4_Data_796 : 32|8@1+ (1,0) [0|255] "" XXX
 SG_ Byte5_Data_796 : 40|8@1+ (1,0) [0|255] "" XXX
 SG_ Byte6_Data_796 : 48|8@1+ (1,0) [0|255] "" XXX
 SG_ Byte7_Data_796 : 56|8@1+ (1,0) [0|255] "" XXX

BO_ 1745 TP_HU_AMP_Dev_Req: 8 XXX
 SG_ Byte0_TCP_795 : 0|8@1+ (1,0) [0|255] "" XXX
 SG_ Byte1_Data_795 : 8|8@1+ (1,0) [0|255] "" XXX
 SG_ Byte2_Data_795 : 16|8@1+ (1,0) [0|255] "" XXX
 SG_ Byte3_Data_795 : 24|8@1+ (1,0) [0|255] "" XXX
 SG_ Byte4_Data_795 : 32|8@1+ (1,0) [0|255] "" XXX
 SG_ Byte5_Data_795 : 40|8@1+ (1,0) [0|255] "" XXX
 SG_ Byte6_Data_795 : 48|8@1+ (1,0) [0|255] "" XXX
 SG_ Byte7_Data_795 : 56|8@1+ (1,0) [0|255] "" XXX

BO_ 1788 TP_VESS_HU_Dev_Res: 8 XXX
 SG_ VESS_HU_Dev_Byte0 : 0|8@1+ (1,0) [0|255] "" XXX
 SG_ VESS_HU_Dev_Byte1 : 8|8@1+ (1,0) [0|255] "" XXX
 SG_ VESS_HU_Dev_Byte2 : 16|8@1+ (1,0) [0|255] "" XXX
 SG_ VESS_HU_Dev_Byte3 : 24|8@1+ (1,0) [0|255] "" XXX
 SG_ VESS_HU_Dev_Byte4 : 32|8@1+ (1,0) [0|255] "" XXX
 SG_ VESS_HU_Dev_Byte5 : 40|8@1+ (1,0) [0|255] "" XXX
 SG_ VESS_HU_Dev_Byte6 : 48|8@1+ (1,0) [0|255] "" XXX
 SG_ VESS_HU_Dev_Byte7 : 56|8@1+ (1,0) [0|255] "" XXX

BO_ 1789 TP_HU_VESS_Dev_Req: 8 XXX
 SG_ HU_VESS_Dev_Byte0 : 0|8@1+ (1,0) [0|255] "" XXX
 SG_ HU_VESS_Dev_Byte1 : 8|8@1+ (1,0) [0|255] "" XXX
 SG_ HU_VESS_Dev_Byte2 : 16|8@1+ (1,0) [0|255] "" XXX
 SG_ HU_VESS_Dev_Byte3 : 24|8@1+ (1,0) [0|255] "" XXX
 SG_ HU_VESS_Dev_Byte4 : 32|8@1+ (1,0) [0|255] "" XXX
 SG_ HU_VESS_Dev_Byte5 : 40|8@1+ (1,0) [0|255] "" XXX
 SG_ HU_VESS_Dev_Byte6 : 48|8@1+ (1,0) [0|255] "" XXX
 SG_ HU_VESS_Dev_Byte7 : 56|8@1+ (1,0) [0|255] "" XXX
